AUTOSAR XML (schema 4-3-0)
standard types defined: dtRef_const_VOID, dtRef_VOID, boolean, float32, float64, sint16, sint16_least, sint32, sint32_least, sint64, sint8, sint8_least, uint16, uint16_least, uint32, uint32_least, uint64, uint8, uint8_least, boolean_CompuMethod, boolean_DataConstr, float32_DataConstr, float64_DataConstr, sint16_DataConstr, sint16_least_DataConstr, sint32_DataConstr, sint32_least_DataConstr, sint64_DataConstr, sint8_DataConstr, sint8_least_DataConstr, uint16_DataConstr, uint16_least_DataConstr, uint32_DataConstr, uint32_least_DataConstr, uint64_DataConstr, uint8_DataConstr, uint8_least_DataConstr, UInt8
package /MICROSAR/BswM_swc
  mode declaration group ESH_Mode: initial-mode=STARTUP
    5 x mode:
      STARTUP
      RUN
      POSTRUN
      WAKEUP
      SHUTDOWN
  mode declaration group ESH_RunRequest: initial-mode=RELEASED
    mode RELEASED
    mode REQUESTED
  mode declaration group MdgShutdownTimerState: initial-mode=TIMER_NOT_EXPIRED
    mode TIMER_EXPIRED
    mode TIMER_NOT_EXPIRED
  data type mapping set BswMMappingSet  # Contains Mapping for ModeDeclarations Groups which are provided by BswM.
    mode-request-type-maps:
      implementation-data-type=BswM_ESH_Mode, mode-group=ESH_Mode
      implementation-data-type=BswM_ESH_RunRequest, mode-group=ESH_RunRequest
      implementation-data-type=BswM_MdgShutdownTimerState, mode-group=MdgShutdownTimerState
package /MICROSAR/BswM_swc/DataTypes
  impl type BswM_ESH_Mode: compu {0=STARTUP, 1=RUN, 2=POSTRUN, 3=WAKEUP, 4=SHUTDOWN}, implementation-data-type=ImplementationDataTypes/uint8  # Unique value for each user
  impl type BswM_ESH_RunRequest: compu {0=RELEASED, 1=REQUESTED}, implementation-data-type=ImplementationDataTypes/uint8  # Unique value for each user
  impl type BswM_MdgShutdownTimerState: compu {0=TIMER_EXPIRED, 1=TIMER_NOT_EXPIRED}, implementation-data-type=ImplementationDataTypes/uint8  # Unique value for each user
package /MICROSAR/BswM_swc/Interfaces
  mode switch interface BswM_MSI_ESH_Mode: is-service=true, service-kind=BASIC-SOFTWARE-MODE-MANAGER
    mode group BswM_MDGP_ESH_Mode: type=ESH_Mode
  sender receiver interface BswM_SRI_BswM_MSI_ESH_Mode_BswM_MDGP_ESH_Mode: is-service=true, service-kind=BASIC-SOFTWARE-MODE-MANAGER
    data requestedMode: type=BswM_ESH_Mode
  mode switch interface BswM_MSI_ESH_RunRequest: is-service=true, service-kind=BASIC-SOFTWARE-MODE-MANAGER
    mode group BswM_MDGP_ESH_RunRequest: type=ESH_RunRequest
  sender receiver interface BswM_SRI_BswM_MSI_ESH_RunRequest_BswM_MDGP_ESH_RunRequest: is-service=true, service-kind=BASIC-SOFTWARE-MODE-MANAGER
    data requestedMode: type=BswM_ESH_RunRequest
  mode switch interface BswM_MSI_MdgShutdownTimerState: is-service=true, service-kind=BASIC-SOFTWARE-MODE-MANAGER
    mode group BswM_MDGP_MdgShutdownTimerState: type=MdgShutdownTimerState
  sender receiver interface BswM_SRI_BswM_MSI_MdgShutdownTimerState_BswM_MDGP_MdgShutdownTimerState: is-service=true, service-kind=BASIC-SOFTWARE-MODE-MANAGER
    data requestedMode: type=BswM_MdgShutdownTimerState
package /MICROSAR/BswM_swc/ComponentTypes
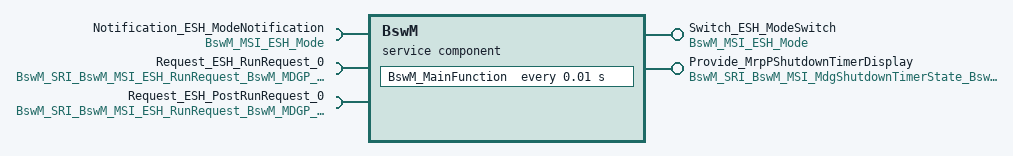
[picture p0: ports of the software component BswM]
  service sw component type BswM: category=SERVICE_COMPONENT
    provide port Switch_ESH_ModeSwitch: provided-interface=BswM_MSI_ESH_Mode
    require port Notification_ESH_ModeNotification: required-interface=BswM_MSI_ESH_Mode
    require port Request_ESH_RunRequest_0: nonqueued-receiver-com-spec{data-element=BswM_SRI_BswM_MSI_ESH_RunRequest_BswM_MDGP_ESH_RunRequest/requestedMode, handle-out-of-range-status=SILENT, init-value=RELEASED}, required-interface=BswM_SRI_BswM_MSI_ESH_RunRequest_BswM_MDGP_ESH_RunRequest
    require port Request_ESH_PostRunRequest_0: nonqueued-receiver-com-spec{data-element=BswM_SRI_BswM_MSI_ESH_RunRequest_BswM_MDGP_ESH_RunRequest/requestedMode, handle-out-of-range-status=SILENT, init-value=RELEASED}, required-interface=BswM_SRI_BswM_MSI_ESH_RunRequest_BswM_MDGP_ESH_RunRequest
    provide port Provide_MrpPShutdownTimerDisplay: nonqueued-sender-com-spec{data-element=BswM_SRI_BswM_MSI_MdgShutdownTimerState_BswM_MDGP_MdgShutdownTimerState/requestedMode, init-value=TIMER_NOT_EXPIRED}, provided-interface=BswM_SRI_BswM_MSI_MdgShutdownTimerState_BswM_MDGP_MdgShutdownTimerState
    behavior BswMInternalBehavior: data-type-mapping=BswMMappingSet, handle-termination-and-restart=NO-SUPPORT, included-data-type-set=data-type=[BswM_ESH_Mode, BswM_ESH_RunRequest, BswM_MdgShutdownTimerState]
      timing event Timer_BswM_MainFunction: start-on-event=BswM_MainFunction, period=0.01
      port-api-options:
        enable-take-address=true, indirect-api=false, port=Switch_ESH_ModeSwitch
        enable-take-address=true, indirect-api=false, port=Notification_ESH_ModeNotification
        enable-take-address=true, indirect-api=false, port=Request_ESH_RunRequest_0
        enable-take-address=true, indirect-api=false, port=Request_ESH_PostRunRequest_0
        enable-take-address=true, indirect-api=false, port=Provide_MrpPShutdownTimerDisplay
      runnable BswM_MainFunction: mode-access-point=Notification_ESH_ModeNotification.BswM_MDGP_ESH_Mode
        data-receive-point-by-arguments:
          access DataReceivePointBswM_MainFunction_Request_ESH_RunRequest_0_requestedMode: accessed-variable=Request_ESH_RunRequest_0.requestedMode
          access DataReceivePointBswM_MainFunction_Request_ESH_PostRunRequest_0_requestedMode: accessed-variable=Request_ESH_PostRunRequest_0.requestedMode
        data-send-points:
          access DataSendPointBswM_MainFunction_Provide_MrpPShutdownTimerDisplay_requestedMode: accessed-variable=Provide_MrpPShutdownTimerDisplay.requestedMode
        mode switch point ModeSwitchPointBswM_MainFunction_Switch_ESH_ModeSwitch_BswM_MDGP_ESH_Mode: mode-group=Switch_ESH_ModeSwitch.BswM_MDGP_ESH_Mode
  swc implementation BswMImplementation: programming-language=C, behavior=BswMInternalBehavior
package /MICROSAR/ComM_swc
  mode declaration group ComMMode: initial-mode=COMM_NO_COMMUNICATION
    mode COMM_NO_COMMUNICATION
    mode COMM_SILENT_COMMUNICATION
    mode COMM_FULL_COMMUNICATION
  data type mapping set ComMMode_DataTypeMappingSet: mode-request-type-map{implementation-data-type=ComM_ModeType, mode-group=ComMMode}  # Data Mapping for the Mode Declaration Group ComMMode.
package /MICROSAR/ComM_swc/DataTypes
  4 x impl type, all with category=TYPE_REFERENCE, implementation-data-type=ImplementationDataTypes/uint8:
    ComM_ModeType: compu {0=COMM_NO_COMMUNICATION, 1=COMM_SILENT_COMMUNICATION, 2=COMM_FULL_COMMUNICATION}
    ComM_InhibitionStatusType: range raw 0..255
    ComM_UserHandleType: range raw 0..255
    NetworkHandleType: range raw 0..255, type-emitter=ComM
package /MICROSAR/ComM_swc/Interfaces
  4 x client server interface, all with is-service=true, service-kind=COM-MANAGER:
    ComM_UserRequest
      4 x operation:
        RequestComMode: possible-error=[ComM_UserRequest/E_NOT_OK, E_MODE_LIMITATION]
          arg ComMode: type=ComM_ModeType, direction=IN
        GetCurrentComMode: possible-error=ComM_UserRequest/E_NOT_OK
          arg ComMode: type=ComM_ModeType, direction=OUT
        GetMaxComMode: possible-error=ComM_UserRequest/E_NOT_OK
          arg ComMode: type=ComM_ModeType, direction=OUT
        GetRequestedComMode: possible-error=ComM_UserRequest/E_NOT_OK
          arg ComMode: type=ComM_ModeType, direction=OUT
      error E_NOT_OK: error-code=1
      error E_MODE_LIMITATION: error-code=2
    ComM_ECUModeLimitation
      4 x operation, all with possible-error=ComM_ECUModeLimitation/E_NOT_OK:
        LimitECUToNoComMode
          arg Status: type=ImplementationDataTypes/boolean, direction=IN
        ReadInhibitCounter
          arg CounterValue: type=uint16, direction=OUT
        ResetInhibitCounter
        SetECUGroupClassification
          arg Status: type=ComM_InhibitionStatusType, direction=IN
      error E_NOT_OK: error-code=1
    ComM_ChannelWakeUp
      operation PreventWakeUp: possible-error=ComM_ChannelWakeUp/E_NOT_OK
        arg Status: type=ImplementationDataTypes/boolean, direction=IN
      error E_NOT_OK: error-code=1
    ComM_ChannelLimitation
      operation LimitChannelToNoComMode: possible-error=ComM_ChannelLimitation/E_NOT_OK
        arg Status: type=ImplementationDataTypes/boolean, direction=IN
      operation GetInhibitionStatus: possible-error=ComM_ChannelLimitation/E_NOT_OK
        arg Status: type=ComM_InhibitionStatusType, direction=OUT
      error E_NOT_OK: error-code=1
  mode switch interface ComM_CurrentMode: is-service=true, service-kind=COM-MANAGER
    mode group currentMode: type=ComMMode
package /MICROSAR/ComM_swc/ComponentTypes
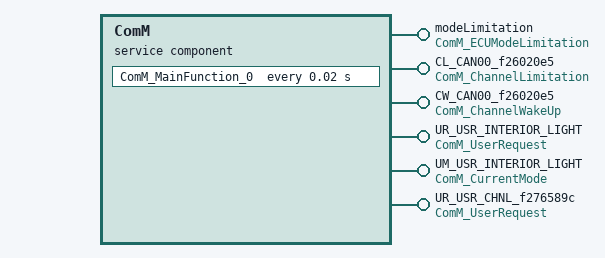
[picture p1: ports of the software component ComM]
  service sw component type ComM: category=SERVICE_COMPONENT
    6 x provide port:
      modeLimitation: provided-interface=ComM_ECUModeLimitation
      CL_CAN00_f26020e5: provided-interface=ComM_ChannelLimitation
      CW_CAN00_f26020e5: provided-interface=ComM_ChannelWakeUp
      UR_USR_INTERIOR_LIGHT: provided-interface=ComM_UserRequest
      UM_USR_INTERIOR_LIGHT: mode-switch-sender-com-spec=currentMode, provided-interface=ComM_CurrentMode
      UR_USR_CHNL_f276589c: provided-interface=ComM_UserRequest
    behavior ComMInternalBehavior: data-type-mapping=ComMMode_DataTypeMappingSet, handle-termination-and-restart=NO-SUPPORT, included-data-type-set=data-type=[ComM_ModeType, ComM_InhibitionStatusType, ComM_UserHandleType, NetworkHandleType]
      timing event Timer_ComM_MainFunction_0: start-on-event=ComM_MainFunction_0, period=0.02
      15 x operation invoked event:
        OpEventGetInhibitionStatus_GetInhibitionStatus_CL_CAN00_f26020e5: start-on-event=GetInhibitionStatus, operation=CL_CAN00_f26020e5.GetInhibitionStatus
        OpEventLimitECUToNoComMode_LimitECUToNoComMode_modeLimitation: start-on-event=LimitECUToNoComMode, operation=modeLimitation.LimitECUToNoComMode
        OpEventReadInhibitCounter_ReadInhibitCounter_modeLimitation: start-on-event=ReadInhibitCounter, operation=modeLimitation.ReadInhibitCounter
        OpEventResetInhibitCounter_ResetInhibitCounter_modeLimitation: start-on-event=ResetInhibitCounter, operation=modeLimitation.ResetInhibitCounter
        OpEventSetECUGroupClassification_SetECUGroupClassification_modeLimitation: start-on-event=SetECUGroupClassification, operation=modeLimitation.SetECUGroupClassification
        OpEventLimitChannelToNoComMode_LimitChannelToNoComMode_CL_CAN00_f26020e5: start-on-event=LimitChannelToNoComMode, operation=CL_CAN00_f26020e5.LimitChannelToNoComMode
        OpEventPreventWakeUp_PreventWakeUp_CW_CAN00_f26020e5: start-on-event=PreventWakeUp, operation=CW_CAN00_f26020e5.PreventWakeUp
        OpEventRequestComMode_RequestComMode_UR_USR_INTERIOR_LIGHT: start-on-event=RequestComMode, operation=UR_USR_INTERIOR_LIGHT.RequestComMode
        OpEventGetCurrentComMode_GetCurrentComMode_UR_USR_INTERIOR_LIGHT: start-on-event=GetCurrentComMode, operation=UR_USR_INTERIOR_LIGHT.GetCurrentComMode
        OpEventGetMaxComMode_GetMaxComMode_UR_USR_INTERIOR_LIGHT: start-on-event=GetMaxComMode, operation=UR_USR_INTERIOR_LIGHT.GetMaxComMode
        OpEventGetRequestedComMode_GetRequestedComMode_UR_USR_INTERIOR_LIGHT: start-on-event=GetRequestedComMode, operation=UR_USR_INTERIOR_LIGHT.GetRequestedComMode
        OpEventRequestComMode_RequestComMode_UR_USR_CHNL_f276589c: start-on-event=RequestComMode, operation=UR_USR_CHNL_f276589c.RequestComMode
        OpEventGetCurrentComMode_GetCurrentComMode_UR_USR_CHNL_f276589c: start-on-event=GetCurrentComMode, operation=UR_USR_CHNL_f276589c.GetCurrentComMode
        OpEventGetMaxComMode_GetMaxComMode_UR_USR_CHNL_f276589c: start-on-event=GetMaxComMode, operation=UR_USR_CHNL_f276589c.GetMaxComMode
        OpEventGetRequestedComMode_GetRequestedComMode_UR_USR_CHNL_f276589c: start-on-event=GetRequestedComMode, operation=UR_USR_CHNL_f276589c.GetRequestedComMode
      port-api-options:
        enable-take-address=true, indirect-api=false, port=modeLimitation
        {enable-take-address=true, indirect-api=false, port-defined-argument-value{value=0, value-type=NetworkHandleType}, port=CL_CAN00_f26020e5}
        {enable-take-address=true, indirect-api=false, port-defined-argument-value{value=0, value-type=NetworkHandleType}, port=CW_CAN00_f26020e5}
        {enable-take-address=true, indirect-api=false, port-defined-argument-value{value=0, value-type=ComM_UserHandleType}, port=UR_USR_INTERIOR_LIGHT}
        enable-take-address=true, indirect-api=false, port=UM_USR_INTERIOR_LIGHT
        {enable-take-address=true, indirect-api=false, port-defined-argument-value{value=1, value-type=ComM_UserHandleType}, port=UR_USR_CHNL_f276589c}
      12 x runnable, all with can-be-invoked-concurrently=true:
        ComM_MainFunction_0
          mode switch point ModeSwitchPointComM_MainFunction_0_UM_USR_INTERIOR_LIGHT_currentMode: mode-group=UM_USR_INTERIOR_LIGHT.currentMode
        GetInhibitionStatus: symbol=ComM_GetInhibitionStatus
        LimitECUToNoComMode: symbol=ComM_LimitECUToNoComMode
        ReadInhibitCounter: symbol=ComM_ReadInhibitCounter
        ResetInhibitCounter: symbol=ComM_ResetInhibitCounter
        SetECUGroupClassification: symbol=ComM_SetECUGroupClassification
        LimitChannelToNoComMode: symbol=ComM_LimitChannelToNoComMode
        PreventWakeUp: symbol=ComM_PreventWakeUp
        RequestComMode: symbol=ComM_RequestComMode
        GetCurrentComMode: symbol=ComM_GetCurrentComMode
        GetMaxComMode: symbol=ComM_GetMaxComMode
        GetRequestedComMode: symbol=ComM_GetRequestedComMode
  swc implementation ComMImplementation: programming-language=C, behavior=ComMInternalBehavior
package /MICROSAR/Dcm_swc
  mode declaration group DcmControlDtcSetting: category=EXPLICIT_ORDER, initial-mode=ENABLEDTCSETTING, on-transition-value=2
    mode ENABLEDTCSETTING: value=0
    mode DISABLEDTCSETTING: value=1
  mode declaration group DcmEcuReset: category=EXPLICIT_ORDER, initial-mode=NONE, on-transition-value=7
    7 x mode:
      NONE: value=0
      HARD: value=1
      KEYONOFF: value=2
      SOFT: value=3
      JUMPTOBOOTLOADER: value=4
      JUMPTOSYSSUPPLIERBOOTLOADER: value=5
      EXECUTE: value=6
  mode declaration group DcmDiagnosticSessionControl: category=EXPLICIT_ORDER, initial-mode=DEFAULT_SESSION, on-transition-value=255
    mode DEFAULT_SESSION: value=1
    mode PROGRAMMING_SESSION: value=2
    mode EXTENDED_SESSION: value=3
  data type mapping set DcmMappingSet  # Contains mapping for ModeDeclarationGroups which are provided by Dcm.
    mode-request-type-maps:
      implementation-data-type=Dcm_ControlDtcSettingType, mode-group=DcmControlDtcSetting
      implementation-data-type=Dcm_EcuResetType, mode-group=DcmEcuReset
      implementation-data-type=Dcm_DiagnosticSessionControlType, mode-group=DcmDiagnosticSessionControl
package /MICROSAR/Dcm_swc/DataTypes
  17 x impl type:
    Dcm_ConfirmationStatusType: compu {0=DCM_RES_POS_OK, 1=DCM_RES_POS_NOT_OK, 2=DCM_RES_NEG_OK, 3=DCM_RES_NEG_NOT_OK}, implementation-data-type=ImplementationDataTypes/uint8
    Dcm_OpStatusType: compu {0=DCM_INITIAL, 1=DCM_PENDING, 2=DCM_CANCEL, 3=DCM_FORCE_RCRRP_OK, 64=DCM_FORCE_RCRRP_NOT_OK}, implementation-data-type=ImplementationDataTypes/uint8
    Dcm_NegativeResponseCodeType: compu {0=DCM_E_POSITIVERESPONSE, 16=DCM_E_GENERALREJECT, 17=DCM_E_SERVICENOTSUPPORTED, 18=DCM_E_SUBFUNCTIONNOTSUPPORTED, 19=DCM_E_INCORRECTMESSAGELENGTHORINVALIDFORMAT, 20=DCM_E_RESPONSETOOLONG, 33=DCM_E_BUSYREPEATREQUEST, 34=DCM_E_CONDITIONSNOTCORRECT, 36=DCM_E_REQUESTSEQUENCEERROR, 37=DCM_E_NORESPONSEFROMSUBNETCOMPONENT, 38=DCM_E_FAILUREPREVENTSEXECUTIONOFREQUESTEDACTION, 49=DCM_E_REQUESTOUTOFRANGE, 51=DCM_E_SECURITYACCESSDENIED, 53=DCM_E_INVALIDKEY, 54=DCM_E_EXCEEDNUMBEROFATTEMPTS, 55=DCM_E_REQUIREDTIMEDELAYNOTEXPIRED, 112=DCM_E_UPLOADDOWNLOADNOTACCEPTED, 113=DCM_E_TRANSFERDATASUSPENDED, 114=DCM_E_GENERALPROGRAMMINGFAILURE, 115=DCM_E_WRONGBLOCKSEQUENCECOUNTER, 120=DCM_E_REQUESTCORRECTLYRECEIVEDRESPONSEPENDING, 126=DCM_E_SUBFUNCTIONNOTSUPPORTEDINACTIVESESSION, 127=DCM_E_SERVICENOTSUPPORTEDINACTIVESESSION, 129=DCM_E_RPMTOOHIGH, 130=DCM_E_RPMTOOLOW, 131=DCM_E_ENGINEISRUNNING, 132=DCM_E_ENGINEISNOTRUNNING, 133=DCM_E_ENGINERUNTIMETOOLOW, 134=DCM_E_TEMPERATURETOOHIGH, 135=DCM_E_TEMPERATURETOOLOW, 136=DCM_E_VEHICLESPEEDTOOHIGH, 137=DCM_E_VEHICLESPEEDTOOLOW, 138=DCM_E_THROTTLE_PEDALTOOHIGH, 139=DCM_E_THROTTLE_PEDALTOOLOW, 140=DCM_E_TRANSMISSIONRANGENOTINNEUTRAL, 141=DCM_E_TRANSMISSIONRANGENOTINGEAR, 143=DCM_E_BRAKESWITCH_NOTCLOSED, 144=DCM_E_SHIFTERLEVERNOTINPARK, 145=DCM_E_TORQUECONVERTERCLUTCHLOCKED, 146=DCM_E_VOLTAGETOOHIGH, 147=DCM_E_VOLTAGETOOLOW, 240..249=DCM_E_VMSCNC_0..DCM_E_VMSCNC_9, 250=DCM_E_VMSCNC_A, 251=DCM_E_VMSCNC_B, 252=DCM_E_VMSCNC_C, 253=DCM_E_VMSCNC_D, 254=DCM_E_VMSCNC_E}, implementation-data-type=ImplementationDataTypes/uint8
    Dcm_ProtocolType: compu {0=DCM_OBD_ON_CAN, 1=DCM_OBD_ON_FLEXRAY, 2=DCM_OBD_ON_IP, 3=DCM_UDS_ON_CAN, 4=DCM_UDS_ON_FLEXRAY, 5=DCM_UDS_ON_IP, 12=DCM_NO_ACTIVE_PROTOCOL, 240..254=DCM_SUPPLIER_1..DCM_SUPPLIER_15}, implementation-data-type=ImplementationDataTypes/uint8
    Dcm_RequestKindType: compu {0=DCM_REQ_KIND_NONE, 1=DCM_REQ_KIND_EXTERNAL, 2=DCM_REQ_KIND_ROE}, implementation-data-type=ImplementationDataTypes/uint8
    Dcm_SecLevelType: compu {0=DCM_SEC_LEV_LOCKED, 1=DCM_SEC_LEV_L1}, implementation-data-type=ImplementationDataTypes/uint8
    Dcm_SesCtrlType: compu {1=DCM_DEFAULT_SESSION, 2=DCM_PROGRAMMING_SESSION, 3=DCM_EXTENDED_DIAGNOSTIC_SESSION}, implementation-data-type=ImplementationDataTypes/uint8
    Dem_DTCFormatType: compu {0=DEM_DTC_FORMAT_OBD, 1=DEM_DTC_FORMAT_UDS, 2=DEM_DTC_FORMAT_J1939}, implementation-data-type=ImplementationDataTypes/uint8
    Dem_DTCKindType: compu {1=DEM_DTC_KIND_ALL_DTCS, 2=DEM_DTC_KIND_EMISSION_REL_DTCS}, implementation-data-type=ImplementationDataTypes/uint8
    Dem_DTCGroupType: range raw 0..16777215, implementation-data-type=ImplementationDataTypes/uint32
    Dem_DTCOriginType: compu {1=DEM_DTC_ORIGIN_PRIMARY_MEMORY, 2=DEM_DTC_ORIGIN_MIRROR_MEMORY, 3=DEM_DTC_ORIGIN_PERMANENT_MEMORY, 4=DEM_DTC_ORIGIN_SECONDARY_MEMORY}, implementation-data-type=ImplementationDataTypes/uint8
    Dcm_ControlDtcSettingType: compu {0=DCM_ENUM_ENABLEDTCSETTING, 1=DCM_ENUM_DISABLEDTCSETTING}, implementation-data-type=ImplementationDataTypes/uint8
    Dcm_EcuResetType: compu {0=DCM_ENUM_NONE, 1=DCM_ENUM_HARD, 2=DCM_ENUM_KEYONOFF, 3=DCM_ENUM_SOFT, 4=DCM_ENUM_JUMPTOBOOTLOADER, 5=DCM_ENUM_JUMPTOSYSSUPPLIERBOOTLOADER, 6=DCM_ENUM_EXECUTE}, implementation-data-type=ImplementationDataTypes/uint8
    Dcm_DiagnosticSessionControlType: compu {1=DCM_ENUM_DEFAULT_SESSION, 2=DCM_ENUM_PROGRAMMING_SESSION, 3=DCM_ENUM_EXTENDED_SESSION}, implementation-data-type=ImplementationDataTypes/uint8
    Dcm_CommunicationModeType: compu {0=DCM_ENABLE_RX_TX_NORM, 1=DCM_ENABLE_RX_DISABLE_TX_NORM, 2=DCM_DISABLE_RX_ENABLE_TX_NORM, 3=DCM_DISABLE_RX_TX_NORMAL, 4=DCM_ENABLE_RX_TX_NM, 5=DCM_ENABLE_RX_DISABLE_TX_NM, 6=DCM_DISABLE_RX_ENABLE_TX_NM, 7=DCM_DISABLE_RX_TX_NM, 8=DCM_ENABLE_RX_TX_NORM_NM, 9=DCM_ENABLE_RX_DISABLE_TX_NORM_NM, 10=DCM_DISABLE_RX_ENABLE_TX_NORM_NM, 11=DCM_DISABLE_RX_TX_NORM_NM}, implementation-data-type=ImplementationDataTypes/uint8
    Dcm_Data2ByteType: category=ARRAY, sw-calibration-access=READ-ONLY
      element Dcm_Data2ByteTypeElement: array-size=2, array-size-semantics=FIXED-SIZE, implementation-data-type=ImplementationDataTypes/uint8
    Dcm_Data4ByteType: category=ARRAY, sw-calibration-access=READ-ONLY
      element Dcm_Data4ByteTypeElement: array-size=4, array-size-semantics=FIXED-SIZE, implementation-data-type=ImplementationDataTypes/uint8
package /MICROSAR/Dcm_swc/Interfaces
  mode switch interface DcmControlDtcSetting: is-service=true, service-kind=DIAGNOSTIC-COMMUNICATION-MANAGER
    mode group DcmControlDtcSetting: type=DcmControlDtcSetting
  mode switch interface DcmEcuReset: is-service=true, service-kind=DIAGNOSTIC-COMMUNICATION-MANAGER
    mode group DcmEcuReset: type=DcmEcuReset
  mode switch interface DcmDiagnosticSessionControl: is-service=true, service-kind=DIAGNOSTIC-COMMUNICATION-MANAGER
    mode group DcmDiagnosticSessionControl: type=DcmDiagnosticSessionControl
  client server interface DCMServices: is-service=true, service-kind=DIAGNOSTIC-COMMUNICATION-MANAGER
    6 x operation:
      GetActiveProtocol: possible-error=DCMServices/E_OK
        arg ActiveProtocol: type=Dcm_ProtocolType, direction=OUT
      GetSesCtrlType: possible-error=DCMServices/E_OK
        arg SesCtrlType: type=Dcm_SesCtrlType, direction=OUT
      ResetToDefaultSession: possible-error=DCMServices/E_OK
      GetSecurityLevel: possible-error=DCMServices/E_OK
        arg SecLevel: type=Dcm_SecLevelType, direction=OUT
      SetActiveDiagnostic: possible-error=DCMServices/E_OK
        arg active: type=ImplementationDataTypes/boolean, direction=IN
      GetRequestKind: possible-error=DCMServices/E_NOT_OK
        arg TesterSourceAddress: type=uint16, direction=IN
        arg RequestKind: type=Dcm_RequestKindType, direction=OUT
    error E_OK: error-code=0
    error E_NOT_OK: error-code=1
  client server interface SecurityAccess_Level_01: is-service=true, service-kind=DIAGNOSTIC-COMMUNICATION-MANAGER
    operation GetSeed: possible-error=[SecurityAccess_Level_01/E_NOT_OK, SecurityAccess_Level_01/DCM_E_PENDING]
      arg OpStatus: type=Dcm_OpStatusType, direction=IN
      arg Seed: type=Dcm_Data2ByteType, direction=OUT
      arg ErrorCode: type=Dcm_NegativeResponseCodeType, direction=OUT
    operation CompareKey: possible-error=[SecurityAccess_Level_01/E_NOT_OK, SecurityAccess_Level_01/DCM_E_PENDING, DCM_E_COMPARE_KEY_FAILED]
      arg Key: type=Dcm_Data2ByteType, direction=IN
      arg OpStatus: type=Dcm_OpStatusType, direction=IN
      arg ErrorCode: type=Dcm_NegativeResponseCodeType, direction=OUT
    error E_NOT_OK: error-code=1
    error DCM_E_PENDING: error-code=10
    error DCM_E_COMPARE_KEY_FAILED: error-code=11
  client server interface DataServices_Diag_RWDI_LightOnOffCounter_LightOnOffCounter_Value: is-service=true, service-kind=DIAGNOSTIC-COMMUNICATION-MANAGER
    operation ReadData: possible-error=[DataServices_Diag_RWDI_LightOnOffCounter_LightOnOffCounter_Value/E_NOT_OK, DataServices_Diag_RWDI_LightOnOffCounter_LightOnOffCounter_Value/DCM_E_PENDING]
      arg OpStatus: type=Dcm_OpStatusType, direction=IN
      arg Data: type=Dcm_Data4ByteType, direction=OUT
    operation ConditionCheckRead: possible-error=[DataServices_Diag_RWDI_LightOnOffCounter_LightOnOffCounter_Value/E_NOT_OK, DataServices_Diag_RWDI_LightOnOffCounter_LightOnOffCounter_Value/DCM_E_PENDING]
      arg OpStatus: type=Dcm_OpStatusType, direction=IN
      arg ErrorCode: type=Dcm_NegativeResponseCodeType, direction=OUT
    operation WriteData: possible-error=[DataServices_Diag_RWDI_LightOnOffCounter_LightOnOffCounter_Value/E_NOT_OK, DataServices_Diag_RWDI_LightOnOffCounter_LightOnOffCounter_Value/DCM_E_PENDING]
      arg Data: type=Dcm_Data4ByteType, direction=IN
      arg OpStatus: type=Dcm_OpStatusType, direction=IN
      arg ErrorCode: type=Dcm_NegativeResponseCodeType, direction=OUT
    error E_NOT_OK: error-code=1
    error DCM_E_PENDING: error-code=10
package /MICROSAR/Dcm_swc/ComponentTypes
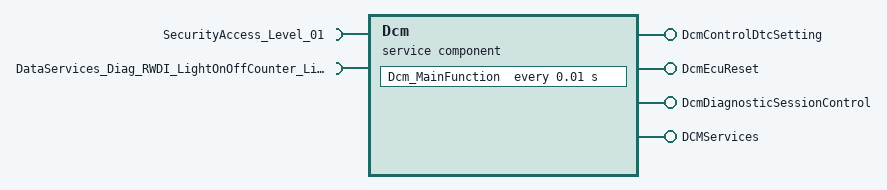
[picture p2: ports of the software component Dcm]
  service sw component type Dcm: category=SERVICE_COMPONENT
    4 x provide port:
      DcmControlDtcSetting: provided-interface=DcmControlDtcSetting
      DcmEcuReset: mode-switch-sender-com-spec{mode-group=DcmEcuReset, mode-switched-ack=timeout=0}, provided-interface=DcmEcuReset
      DcmDiagnosticSessionControl: provided-interface=DcmDiagnosticSessionControl
      DCMServices: provided-interface=DCMServices
    require port SecurityAccess_Level_01: required-interface=SecurityAccess_Level_01
    require port DataServices_Diag_RWDI_LightOnOffCounter_LightOnOffCounter_Value: required-interface=DataServices_Diag_RWDI_LightOnOffCounter_LightOnOffCounter_Value
    behavior DcmInternalBehavior: data-type-mapping=DcmMappingSet, handle-termination-and-restart=NO-SUPPORT, included-data-type-set=data-type=[Dcm_ConfirmationStatusType, Dcm_OpStatusType, Dcm_NegativeResponseCodeType, Dcm_ProtocolType, Dcm_RequestKindType, Dcm_SecLevelType, Dcm_SesCtrlType, Dcm_ControlDtcSettingType, Dcm_EcuResetType, Dcm_DiagnosticSessionControlType, Dcm_CommunicationModeType]
      timing event Timer_Dcm_MainFunction: start-on-event=Dcm_MainFunction, period=0.01
      6 x operation invoked event:
        OpEventGetActiveProtocol_GetActiveProtocol_DCMServices: start-on-event=GetActiveProtocol, operation=DCMServices.GetActiveProtocol
        OpEventGetSesCtrlType_GetSesCtrlType_DCMServices: start-on-event=GetSesCtrlType, operation=DCMServices.GetSesCtrlType
        OpEventResetToDefaultSession_ResetToDefaultSession_DCMServices: start-on-event=ResetToDefaultSession, operation=DCMServices.ResetToDefaultSession
        OpEventGetSecurityLevel_GetSecurityLevel_DCMServices: start-on-event=GetSecurityLevel, operation=DCMServices.GetSecurityLevel
        OpEventSetActiveDiagnostic_SetActiveDiagnostic_DCMServices: start-on-event=SetActiveDiagnostic, operation=DCMServices.SetActiveDiagnostic
        OpEventGetRequestKind_GetRequestKind_DCMServices: start-on-event=GetRequestKind, operation=DCMServices.GetRequestKind
      port-api-options:
        enable-take-address=true, indirect-api=false, port=DcmControlDtcSetting
        enable-take-address=true, indirect-api=false, port=DcmEcuReset
        enable-take-address=true, indirect-api=false, port=DcmDiagnosticSessionControl
        enable-take-address=true, indirect-api=false, port=DCMServices
        enable-take-address=true, indirect-api=false, port=SecurityAccess_Level_01
        enable-take-address=true, indirect-api=false, port=DataServices_Diag_RWDI_LightOnOffCounter_LightOnOffCounter_Value
      7 x runnable:
        Dcm_MainFunction
          mode switch point ModeSwitchPointDcm_MainFunction_DcmControlDtcSetting_DcmControlDtcSetting: mode-group=DcmControlDtcSetting.DcmControlDtcSetting
          mode switch point ModeSwitchPointDcm_MainFunction_DcmEcuReset_DcmEcuReset: mode-group=DcmEcuReset.DcmEcuReset
          mode switch point ModeSwitchPointDcm_MainFunction_DcmDiagnosticSessionControl_DcmDiagnosticSessionControl: mode-group=DcmDiagnosticSessionControl.DcmDiagnosticSessionControl
          5 x sync call, all with timeout=0:
            OpServerCallDcm_MainFunction_GetSeed_SecurityAccess_Level_01: operation=SecurityAccess_Level_01.GetSeed
            OpServerCallDcm_MainFunction_CompareKey_SecurityAccess_Level_01: operation=SecurityAccess_Level_01.CompareKey
            OpServerCallDcm_MainFunction_ReadData_DataServices_Diag_RWDI_LightOnOffCounter_LightOnOffCounter_Value: operation=DataServices_Diag_RWDI_LightOnOffCounter_LightOnOffCounter_Value.ReadData
            OpServerCallDcm_MainFunction_ConditionCheckRead_DataServices_Diag_RWDI_LightOnOffCounter_LightOnOffCounter_Value: operation=DataServices_Diag_RWDI_LightOnOffCounter_LightOnOffCounter_Value.ConditionCheckRead
            OpServerCallDcm_MainFunction_WriteData_DataServices_Diag_RWDI_LightOnOffCounter_LightOnOffCounter_Value: operation=DataServices_Diag_RWDI_LightOnOffCounter_LightOnOffCounter_Value.WriteData
        GetActiveProtocol: can-be-invoked-concurrently=true, symbol=Dcm_GetActiveProtocol
        GetSesCtrlType: can-be-invoked-concurrently=true, symbol=Dcm_GetSesCtrlType
        ResetToDefaultSession: can-be-invoked-concurrently=true, symbol=Dcm_ResetToDefaultSession
        GetSecurityLevel: can-be-invoked-concurrently=true, symbol=Dcm_GetSecurityLevel
        SetActiveDiagnostic: can-be-invoked-concurrently=true, symbol=Dcm_SetActiveDiagnostic
        GetRequestKind: can-be-invoked-concurrently=true, symbol=Dcm_GetRequestKind
  swc implementation DcmImplementation: programming-language=C, behavior=DcmInternalBehavior
package /MICROSAR/Dem_swc/DataTypes
  23 x impl type:
    Dem_EventIdType: range raw 1..65535, implementation-data-type=uint16
    Dem_RatioIdType: range raw 1..65535, implementation-data-type=uint16
    Dem_DTCStatusMaskType: range raw 0..255, implementation-data-type=ImplementationDataTypes/uint8
    Dem_OperationCycleIdType: range raw 0..255, implementation-data-type=ImplementationDataTypes/uint8
    Dem_DTCGroupType: range raw 0..16777215, implementation-data-type=ImplementationDataTypes/uint32
    Dem_EventStatusType: compu {0=DEM_EVENT_STATUS_PASSED, 1=DEM_EVENT_STATUS_FAILED, 2=DEM_EVENT_STATUS_PREPASSED, 3=DEM_EVENT_STATUS_PREFAILED, 4=DEM_EVENT_STATUS_FDC_THRESHOLD_REACHED, 5=DEM_EVENT_STATUS_PASSED_CONDITIONS_NOT_FULFILLED, 6=DEM_EVENT_STATUS_FAILED_CONDITIONS_NOT_FULFILLED, 7=DEM_EVENT_STATUS_PREPASSED_CONDITIONS_NOT_FULFILLED, 8=DEM_EVENT_STATUS_PREFAILED_CONDITIONS_NOT_FULFILLED}, implementation-data-type=ImplementationDataTypes/uint8
    Dem_InitMonitorReasonType: compu {1=DEM_INIT_MONITOR_CLEAR, 2=DEM_INIT_MONITOR_RESTART, 3=DEM_INIT_MONITOR_REENABLED, 4=DEM_INIT_MONITOR_STORAGE_REENABLED}, implementation-data-type=ImplementationDataTypes/uint8
    Dem_DTCOriginType: compu {1=DEM_DTC_ORIGIN_PRIMARY_MEMORY, 2=DEM_DTC_ORIGIN_MIRROR_MEMORY, 3=DEM_DTC_ORIGIN_PERMANENT_MEMORY, 4=DEM_DTC_ORIGIN_OBD_RELEVANT_MEMORY, 5=DEM_DTC_ORIGIN_SECONDARY_MEMORY, 5=DEM_DTC_ORIGIN_USERDEFINED_MEMORY_10, 5=DEM_DTC_ORIGIN_USERDEFINED_MEMORY_11, 5=DEM_DTC_ORIGIN_USERDEFINED_MEMORY_12, 5=DEM_DTC_ORIGIN_USERDEFINED_MEMORY_13, 5=DEM_DTC_ORIGIN_USERDEFINED_MEMORY_14, 5=DEM_DTC_ORIGIN_USERDEFINED_MEMORY_15, 5=DEM_DTC_ORIGIN_USERDEFINED_MEMORY_16, 5=DEM_DTC_ORIGIN_USERDEFINED_MEMORY_17, 5=DEM_DTC_ORIGIN_USERDEFINED_MEMORY_18, 5=DEM_DTC_ORIGIN_USERDEFINED_MEMORY_19, 5=DEM_DTC_ORIGIN_USERDEFINED_MEMORY_1A, 5=DEM_DTC_ORIGIN_USERDEFINED_MEMORY_1B, 5=DEM_DTC_ORIGIN_USERDEFINED_MEMORY_1C, 5=DEM_DTC_ORIGIN_USERDEFINED_MEMORY_1D, 5=DEM_DTC_ORIGIN_USERDEFINED_MEMORY_1E, 5=DEM_DTC_ORIGIN_USERDEFINED_MEMORY_1F, 5=DEM_DTC_ORIGIN_USERDEFINED_MEMORY_20, 5=DEM_DTC_ORIGIN_USERDEFINED_MEMORY_21, 5=DEM_DTC_ORIGIN_USERDEFINED_MEMORY_22, 5=DEM_DTC_ORIGIN_USERDEFINED_MEMORY_23, 5=DEM_DTC_ORIGIN_USERDEFINED_MEMORY_24, 5=DEM_DTC_ORIGIN_USERDEFINED_MEMORY_25, 5=DEM_DTC_ORIGIN_USERDEFINED_MEMORY_26, 5=DEM_DTC_ORIGIN_USERDEFINED_MEMORY_27, 5=DEM_DTC_ORIGIN_USERDEFINED_MEMORY_28, 5=DEM_DTC_ORIGIN_USERDEFINED_MEMORY_29, 5=DEM_DTC_ORIGIN_USERDEFINED_MEMORY_2A, 5=DEM_DTC_ORIGIN_USERDEFINED_MEMORY_2B, 5=DEM_DTC_ORIGIN_USERDEFINED_MEMORY_2C, 5=DEM_DTC_ORIGIN_USERDEFINED_MEMORY_2D, 5=DEM_DTC_ORIGIN_USERDEFINED_MEMORY_2E, 5=DEM_DTC_ORIGIN_USERDEFINED_MEMORY_2F, 5=DEM_DTC_ORIGIN_USERDEFINED_MEMORY_30, 5=DEM_DTC_ORIGIN_USERDEFINED_MEMORY_31, 5=DEM_DTC_ORIGIN_USERDEFINED_MEMORY_32, 5=DEM_DTC_ORIGIN_USERDEFINED_MEMORY_33, 5=DEM_DTC_ORIGIN_USERDEFINED_MEMORY_34, 5=DEM_DTC_ORIGIN_USERDEFINED_MEMORY_35, 5=DEM_DTC_ORIGIN_USERDEFINED_MEMORY_36, 5=DEM_DTC_ORIGIN_USERDEFINED_MEMORY_37, 5=DEM_DTC_ORIGIN_USERDEFINED_MEMORY_38, 5=DEM_DTC_ORIGIN_USERDEFINED_MEMORY_39, 5=DEM_DTC_ORIGIN_USERDEFINED_MEMORY_3A, 5=DEM_DTC_ORIGIN_USERDEFINED_MEMORY_3B, 5=DEM_DTC_ORIGIN_USERDEFINED_MEMORY_3C, 5=DEM_DTC_ORIGIN_USERDEFINED_MEMORY_3D, 5=DEM_DTC_ORIGIN_USERDEFINED_MEMORY_3E, 5=DEM_DTC_ORIGIN_USERDEFINED_MEMORY_3F, 5=DEM_DTC_ORIGIN_USERDEFINED_MEMORY_40, 5=DEM_DTC_ORIGIN_USERDEFINED_MEMORY_41, 5=DEM_DTC_ORIGIN_USERDEFINED_MEMORY_42, 5=DEM_DTC_ORIGIN_USERDEFINED_MEMORY_43, 5=DEM_DTC_ORIGIN_USERDEFINED_MEMORY_44, 5=DEM_DTC_ORIGIN_USERDEFINED_MEMORY_45, 5=DEM_DTC_ORIGIN_USERDEFINED_MEMORY_46, 5=DEM_DTC_ORIGIN_USERDEFINED_MEMORY_47, 5=DEM_DTC_ORIGIN_USERDEFINED_MEMORY_48, 5=DEM_DTC_ORIGIN_USERDEFINED_MEMORY_49, 5=DEM_DTC_ORIGIN_USERDEFINED_MEMORY_4A, 5=DEM_DTC_ORIGIN_USERDEFINED_MEMORY_4B, 5=DEM_DTC_ORIGIN_USERDEFINED_MEMORY_4C, 5=DEM_DTC_ORIGIN_USERDEFINED_MEMORY_4D, 5=DEM_DTC_ORIGIN_USERDEFINED_MEMORY_4E, 5=DEM_DTC_ORIGIN_USERDEFINED_MEMORY_4F, 5=DEM_DTC_ORIGIN_USERDEFINED_MEMORY_50, 5=DEM_DTC_ORIGIN_USERDEFINED_MEMORY_51, 5=DEM_DTC_ORIGIN_USERDEFINED_MEMORY_52, 5=DEM_DTC_ORIGIN_USERDEFINED_MEMORY_53, 5=DEM_DTC_ORIGIN_USERDEFINED_MEMORY_54, 5=DEM_DTC_ORIGIN_USERDEFINED_MEMORY_55, 5=DEM_DTC_ORIGIN_USERDEFINED_MEMORY_56, 5=DEM_DTC_ORIGIN_USERDEFINED_MEMORY_57, 5=DEM_DTC_ORIGIN_USERDEFINED_MEMORY_58, 5=DEM_DTC_ORIGIN_USERDEFINED_MEMORY_59, 5=DEM_DTC_ORIGIN_USERDEFINED_MEMORY_5A, 5=DEM_DTC_ORIGIN_USERDEFINED_MEMORY_5B, 5=DEM_DTC_ORIGIN_USERDEFINED_MEMORY_5C, 5=DEM_DTC_ORIGIN_USERDEFINED_MEMORY_5D, 5=DEM_DTC_ORIGIN_USERDEFINED_MEMORY_5E, 5=DEM_DTC_ORIGIN_USERDEFINED_MEMORY_5F, 5=DEM_DTC_ORIGIN_USERDEFINED_MEMORY_60, 5=DEM_DTC_ORIGIN_USERDEFINED_MEMORY_61, 5=DEM_DTC_ORIGIN_USERDEFINED_MEMORY_62, 5=DEM_DTC_ORIGIN_USERDEFINED_MEMORY_63, 5=DEM_DTC_ORIGIN_USERDEFINED_MEMORY_64, 5=DEM_DTC_ORIGIN_USERDEFINED_MEMORY_65, 5=DEM_DTC_ORIGIN_USERDEFINED_MEMORY_66, 5=DEM_DTC_ORIGIN_USERDEFINED_MEMORY_67, 5=DEM_DTC_ORIGIN_USERDEFINED_MEMORY_68, 5=DEM_DTC_ORIGIN_USERDEFINED_MEMORY_69, 5=DEM_DTC_ORIGIN_USERDEFINED_MEMORY_6A, 5=DEM_DTC_ORIGIN_USERDEFINED_MEMORY_6B, 5=DEM_DTC_ORIGIN_USERDEFINED_MEMORY_6C, 5=DEM_DTC_ORIGIN_USERDEFINED_MEMORY_6D, 5=DEM_DTC_ORIGIN_USERDEFINED_MEMORY_6E, 5=DEM_DTC_ORIGIN_USERDEFINED_MEMORY_6F, 5=DEM_DTC_ORIGIN_USERDEFINED_MEMORY_70, 5=DEM_DTC_ORIGIN_USERDEFINED_MEMORY_71, 5=DEM_DTC_ORIGIN_USERDEFINED_MEMORY_72, 5=DEM_DTC_ORIGIN_USERDEFINED_MEMORY_73, 5=DEM_DTC_ORIGIN_USERDEFINED_MEMORY_74, 5=DEM_DTC_ORIGIN_USERDEFINED_MEMORY_75, 5=DEM_DTC_ORIGIN_USERDEFINED_MEMORY_76, 5=DEM_DTC_ORIGIN_USERDEFINED_MEMORY_77, 5=DEM_DTC_ORIGIN_USERDEFINED_MEMORY_78, 5=DEM_DTC_ORIGIN_USERDEFINED_MEMORY_79, 5=DEM_DTC_ORIGIN_USERDEFINED_MEMORY_7A, 5=DEM_DTC_ORIGIN_USERDEFINED_MEMORY_7B, 5=DEM_DTC_ORIGIN_USERDEFINED_MEMORY_7C, 5=DEM_DTC_ORIGIN_USERDEFINED_MEMORY_7D, 5=DEM_DTC_ORIGIN_USERDEFINED_MEMORY_7E, 5=DEM_DTC_ORIGIN_USERDEFINED_MEMORY_7F, 5=DEM_DTC_ORIGIN_USERDEFINED_MEMORY_80, 5=DEM_DTC_ORIGIN_USERDEFINED_MEMORY_81, 5=DEM_DTC_ORIGIN_USERDEFINED_MEMORY_82, 5=DEM_DTC_ORIGIN_USERDEFINED_MEMORY_83, 5=DEM_DTC_ORIGIN_USERDEFINED_MEMORY_84, 5=DEM_DTC_ORIGIN_USERDEFINED_MEMORY_85, 5=DEM_DTC_ORIGIN_USERDEFINED_MEMORY_86, 5=DEM_DTC_ORIGIN_USERDEFINED_MEMORY_87, 5=DEM_DTC_ORIGIN_USERDEFINED_MEMORY_88, 5=DEM_DTC_ORIGIN_USERDEFINED_MEMORY_89, 5=DEM_DTC_ORIGIN_USERDEFINED_MEMORY_8A, 5=DEM_DTC_ORIGIN_USERDEFINED_MEMORY_8B, 5=DEM_DTC_ORIGIN_USERDEFINED_MEMORY_8C, 5=DEM_DTC_ORIGIN_USERDEFINED_MEMORY_8D, 5=DEM_DTC_ORIGIN_USERDEFINED_MEMORY_8E, 5=DEM_DTC_ORIGIN_USERDEFINED_MEMORY_8F, 5=DEM_DTC_ORIGIN_USERDEFINED_MEMORY_90, 5=DEM_DTC_ORIGIN_USERDEFINED_MEMORY_91, 5=DEM_DTC_ORIGIN_USERDEFINED_MEMORY_92, 5=DEM_DTC_ORIGIN_USERDEFINED_MEMORY_93, 5=DEM_DTC_ORIGIN_USERDEFINED_MEMORY_94, 5=DEM_DTC_ORIGIN_USERDEFINED_MEMORY_95, 5=DEM_DTC_ORIGIN_USERDEFINED_MEMORY_96, 5=DEM_DTC_ORIGIN_USERDEFINED_MEMORY_97, 5=DEM_DTC_ORIGIN_USERDEFINED_MEMORY_98, 5=DEM_DTC_ORIGIN_USERDEFINED_MEMORY_99, 5=DEM_DTC_ORIGIN_USERDEFINED_MEMORY_9A, 5=DEM_DTC_ORIGIN_USERDEFINED_MEMORY_9B, 5=DEM_DTC_ORIGIN_USERDEFINED_MEMORY_9C, 5=DEM_DTC_ORIGIN_USERDEFINED_MEMORY_9D, 5=DEM_DTC_ORIGIN_USERDEFINED_MEMORY_9E, 5=DEM_DTC_ORIGIN_USERDEFINED_MEMORY_9F, 5=DEM_DTC_ORIGIN_USERDEFINED_MEMORY_A0, 5=DEM_DTC_ORIGIN_USERDEFINED_MEMORY_A1, 5=DEM_DTC_ORIGIN_USERDEFINED_MEMORY_A2, 5=DEM_DTC_ORIGIN_USERDEFINED_MEMORY_A3, 5=DEM_DTC_ORIGIN_USERDEFINED_MEMORY_A4, 5=DEM_DTC_ORIGIN_USERDEFINED_MEMORY_A5, 5=DEM_DTC_ORIGIN_USERDEFINED_MEMORY_A6, 5=DEM_DTC_ORIGIN_USERDEFINED_MEMORY_A7, 5=DEM_DTC_ORIGIN_USERDEFINED_MEMORY_A8, 5=DEM_DTC_ORIGIN_USERDEFINED_MEMORY_A9, 5=DEM_DTC_ORIGIN_USERDEFINED_MEMORY_AA, 5=DEM_DTC_ORIGIN_USERDEFINED_MEMORY_AB, 5=DEM_DTC_ORIGIN_USERDEFINED_MEMORY_AC, 5=DEM_DTC_ORIGIN_USERDEFINED_MEMORY_AD, 5=DEM_DTC_ORIGIN_USERDEFINED_MEMORY_AE, 5=DEM_DTC_ORIGIN_USERDEFINED_MEMORY_AF, 5=DEM_DTC_ORIGIN_USERDEFINED_MEMORY_B0, 5=DEM_DTC_ORIGIN_USERDEFINED_MEMORY_B1, 5=DEM_DTC_ORIGIN_USERDEFINED_MEMORY_B2, 5=DEM_DTC_ORIGIN_USERDEFINED_MEMORY_B3, 5=DEM_DTC_ORIGIN_USERDEFINED_MEMORY_B4, 5=DEM_DTC_ORIGIN_USERDEFINED_MEMORY_B5, 5=DEM_DTC_ORIGIN_USERDEFINED_MEMORY_B6, 5=DEM_DTC_ORIGIN_USERDEFINED_MEMORY_B7, 5=DEM_DTC_ORIGIN_USERDEFINED_MEMORY_B8, 5=DEM_DTC_ORIGIN_USERDEFINED_MEMORY_B9, 5=DEM_DTC_ORIGIN_USERDEFINED_MEMORY_BA, 5=DEM_DTC_ORIGIN_USERDEFINED_MEMORY_BB, 5=DEM_DTC_ORIGIN_USERDEFINED_MEMORY_BC, 5=DEM_DTC_ORIGIN_USERDEFINED_MEMORY_BD, 5=DEM_DTC_ORIGIN_USERDEFINED_MEMORY_BE, 5=DEM_DTC_ORIGIN_USERDEFINED_MEMORY_BF, 5=DEM_DTC_ORIGIN_USERDEFINED_MEMORY_C0, 5=DEM_DTC_ORIGIN_USERDEFINED_MEMORY_C1, 5=DEM_DTC_ORIGIN_USERDEFINED_MEMORY_C2, 5=DEM_DTC_ORIGIN_USERDEFINED_MEMORY_C3, 5=DEM_DTC_ORIGIN_USERDEFINED_MEMORY_C4, 5=DEM_DTC_ORIGIN_USERDEFINED_MEMORY_C5, 5=DEM_DTC_ORIGIN_USERDEFINED_MEMORY_C6, 5=DEM_DTC_ORIGIN_USERDEFINED_MEMORY_C7, 5=DEM_DTC_ORIGIN_USERDEFINED_MEMORY_C8, 5=DEM_DTC_ORIGIN_USERDEFINED_MEMORY_C9, 5=DEM_DTC_ORIGIN_USERDEFINED_MEMORY_CA, 5=DEM_DTC_ORIGIN_USERDEFINED_MEMORY_CB, 5=DEM_DTC_ORIGIN_USERDEFINED_MEMORY_CC, 5=DEM_DTC_ORIGIN_USERDEFINED_MEMORY_CD, 5=DEM_DTC_ORIGIN_USERDEFINED_MEMORY_CE, 5=DEM_DTC_ORIGIN_USERDEFINED_MEMORY_CF, 5=DEM_DTC_ORIGIN_USERDEFINED_MEMORY_D0, 5=DEM_DTC_ORIGIN_USERDEFINED_MEMORY_D1, 5=DEM_DTC_ORIGIN_USERDEFINED_MEMORY_D2, 5=DEM_DTC_ORIGIN_USERDEFINED_MEMORY_D3, 5=DEM_DTC_ORIGIN_USERDEFINED_MEMORY_D4, 5=DEM_DTC_ORIGIN_USERDEFINED_MEMORY_D5, 5=DEM_DTC_ORIGIN_USERDEFINED_MEMORY_D6, 5=DEM_DTC_ORIGIN_USERDEFINED_MEMORY_D7, 5=DEM_DTC_ORIGIN_USERDEFINED_MEMORY_D8, 5=DEM_DTC_ORIGIN_USERDEFINED_MEMORY_D9, 5=DEM_DTC_ORIGIN_USERDEFINED_MEMORY_DA, 5=DEM_DTC_ORIGIN_USERDEFINED_MEMORY_DB, 5=DEM_DTC_ORIGIN_USERDEFINED_MEMORY_DC, 5=DEM_DTC_ORIGIN_USERDEFINED_MEMORY_DD, 5=DEM_DTC_ORIGIN_USERDEFINED_MEMORY_DE, 5=DEM_DTC_ORIGIN_USERDEFINED_MEMORY_DF, 5=DEM_DTC_ORIGIN_USERDEFINED_MEMORY_E0, 5=DEM_DTC_ORIGIN_USERDEFINED_MEMORY_E1, 5=DEM_DTC_ORIGIN_USERDEFINED_MEMORY_E2, 5=DEM_DTC_ORIGIN_USERDEFINED_MEMORY_E3, 5=DEM_DTC_ORIGIN_USERDEFINED_MEMORY_E4, 5=DEM_DTC_ORIGIN_USERDEFINED_MEMORY_E5, 5=DEM_DTC_ORIGIN_USERDEFINED_MEMORY_E6, 5=DEM_DTC_ORIGIN_USERDEFINED_MEMORY_E7, 5=DEM_DTC_ORIGIN_USERDEFINED_MEMORY_E8, 5=DEM_DTC_ORIGIN_USERDEFINED_MEMORY_E9, 5=DEM_DTC_ORIGIN_USERDEFINED_MEMORY_EA, 5=DEM_DTC_ORIGIN_USERDEFINED_MEMORY_EB, 5=DEM_DTC_ORIGIN_USERDEFINED_MEMORY_EC, 5=DEM_DTC_ORIGIN_USERDEFINED_MEMORY_ED, 5=DEM_DTC_ORIGIN_USERDEFINED_MEMORY_EE, 5=DEM_DTC_ORIGIN_USERDEFINED_MEMORY_EF, 5=DEM_DTC_ORIGIN_USERDEFINED_MEMORY_F0, 5=DEM_DTC_ORIGIN_USERDEFINED_MEMORY_F1, 5=DEM_DTC_ORIGIN_USERDEFINED_MEMORY_F2, 5=DEM_DTC_ORIGIN_USERDEFINED_MEMORY_F3, 5=DEM_DTC_ORIGIN_USERDEFINED_MEMORY_F4, 5=DEM_DTC_ORIGIN_USERDEFINED_MEMORY_F5, 5=DEM_DTC_ORIGIN_USERDEFINED_MEMORY_F6, 5=DEM_DTC_ORIGIN_USERDEFINED_MEMORY_F7, 5=DEM_DTC_ORIGIN_USERDEFINED_MEMORY_F8, 5=DEM_DTC_ORIGIN_USERDEFINED_MEMORY_F9, 5=DEM_DTC_ORIGIN_USERDEFINED_MEMORY_FA, 5=DEM_DTC_ORIGIN_USERDEFINED_MEMORY_FB, 5=DEM_DTC_ORIGIN_USERDEFINED_MEMORY_FC, 5=DEM_DTC_ORIGIN_USERDEFINED_MEMORY_FD, 5=DEM_DTC_ORIGIN_USERDEFINED_MEMORY_FE, 5=DEM_DTC_ORIGIN_USERDEFINED_MEMORY_FF}, implementation-data-type=uint16
    Dem_DTCFormatType: compu {0=DEM_DTC_FORMAT_OBD, 1=DEM_DTC_FORMAT_UDS, 2=DEM_DTC_FORMAT_J1939}, implementation-data-type=ImplementationDataTypes/uint8
    Dem_OperationCycleStateType: compu {0=DEM_CYCLE_STATE_START, 1=DEM_CYCLE_STATE_END}, implementation-data-type=ImplementationDataTypes/uint8
    Dem_IndicatorStatusType: compu {0=DEM_INDICATOR_OFF, 1=DEM_INDICATOR_CONTINUOUS, 2=DEM_INDICATOR_BLINKING, 3=DEM_INDICATOR_BLINK_CONT, 4=DEM_INDICATOR_SLOW_FLASH, 5=DEM_INDICATOR_FAST_FLASH, 6=DEM_INDICATOR_ON_DEMAND, 7=DEM_INDICATOR_SHORT}, implementation-data-type=ImplementationDataTypes/uint8
    Dem_DTCKindType: compu {1=DEM_DTC_KIND_ALL_DTCS, 2=DEM_DTC_KIND_EMISSION_REL_DTCS}, implementation-data-type=ImplementationDataTypes/uint8
    Dem_IumprDenomCondIdType: compu {1=DEM_IUMPR_GENERAL_DENOMINATOR, 2=DEM_IUMPR_DEN_COND_COLDSTART, 3=DEM_IUMPR_DEN_COND_EVAP, 4=DEM_IUMPR_DEN_COND_500MI}, implementation-data-type=ImplementationDataTypes/uint8
    Dem_IumprDenomCondStatusType: compu {0=DEM_IUMPR_DEN_STATUS_NOT_REACHED, 1=DEM_IUMPR_DEN_STATUS_REACHED, 2=DEM_IUMPR_DEN_STATUS_INHIBITED}, implementation-data-type=ImplementationDataTypes/uint8
    Dem_DebounceResetStatusType: compu {0=DEM_DEBOUNCE_STATUS_FREEZE, 1=DEM_DEBOUNCE_STATUS_RESET}, implementation-data-type=ImplementationDataTypes/uint8
    Dem_IumprReadinessGroupType: compu {0=DEM_IUMPR_BOOSTPRS, 1=DEM_IUMPR_CAT1, 2=DEM_IUMPR_CAT2, 3=DEM_IUMPR_EGR, 4=DEM_IUMPR_EGSENSOR, 5=DEM_IUMPR_EVAP, 6=DEM_IUMPR_NMHCCAT, 7=DEM_IUMPR_NOXADSORB, 8=DEM_IUMPR_NOXCAT, 9=DEM_IUMPR_OXS1, 10=DEM_IUMPR_OXS2, 11=DEM_IUMPR_PMFILTER, 12=DEM_IUMPR_PRIVATE, 13=DEM_IUMPR_SAIR, 14=DEM_IUMPR_SECOXS1, 15=DEM_IUMPR_SECOXS2, 16=DEM_IUMPR_FLSYS, 255=DEM_IUMPR_ALLGROUPS}, implementation-data-type=ImplementationDataTypes/uint8
    Dem_DTRControlType: compu {0=DEM_DTR_CTL_NORMAL, 1=DEM_DTR_CTL_NO_MAX, 2=DEM_DTR_CTL_NO_MIN, 3=DEM_DTR_CTL_RESET, 4=DEM_DTR_CTL_INVISIBLE}, implementation-data-type=ImplementationDataTypes/uint8
    Dem_DebouncingStateType: compu {mask 1: 1=DEM_TEMPORARILY_DEFECTIVE, mask 2: 2=DEM_FINALLY_DEFECTIVE, mask 4: 4=DEM_TEMPORARILY_HEALED, mask 8: 8=DEM_TEST_COMPLETE, mask 16: 16=DEM_DTR_UPDATE}, range raw 0..255, implementation-data-type=ImplementationDataTypes/uint8
    Dem_DTCSeverityType:
      compu {mask 255: 0=DEM_SEVERITY_NO_SEVERITY, mask 31: 2=DEM_SEVERITY_WWHOBD_CLASS_A, mask 31: 4=DEM_SEVERITY_WWHOBD_CLASS_B1, mask 31: 8=DEM_SEVERITY_WWHOBD_CLASS_B2, mask 31: 16=DEM_SEVERITY_WWHOBD_CLASS_C, mask 31: 1=DEM_SEVERITY_WWHOBD_CLASS_NO_CLASS, mask 224: 64=DEM_SEVERITY_CHECK_AT_NEXT_HALT, mask 224: 128=DEM_SEVERITY_CHECK_IMMEDIATELY, mask 224: 32=DEM_SEVERITY_MAINTENANCE_ONLY}
      range raw 0..255
      implementation-data-type=ImplementationDataTypes/uint8
    Dem_UdsStatusByteType: compu {mask 1: 1=DEM_UDS_STATUS_TF, mask 2: 2=DEM_UDS_STATUS_TFTOC, mask 4: 4=DEM_UDS_STATUS_PDTC, mask 8: 8=DEM_UDS_STATUS_CDTC, mask 16: 16=DEM_UDS_STATUS_TNCSLC, mask 32: 32=DEM_UDS_STATUS_TFSLC, mask 64: 64=DEM_UDS_STATUS_TNCTOC, mask 128: 128=DEM_UDS_STATUS_WIR}, range raw 0..255, implementation-data-type=ImplementationDataTypes/uint8
    Dem_MonitorStatusType: compu {mask 1: 1=DEM_MONITOR_STATUS_TF, mask 2: 2=DEM_MONITOR_STATUS_TNCTOC}, range raw 0..255, implementation-data-type=ImplementationDataTypes/uint8
    Dem_MaxDataValueType: category=ARRAY, sw-calibration-access=READ-ONLY
      element Dem_MaxDataValueTypeElement: array-size=4, array-size-semantics=FIXED-SIZE, implementation-data-type=ImplementationDataTypes/uint8
    DataArrayType_uint8_4: category=ARRAY, sw-calibration-access=READ-ONLY
      element DataArrayType_uint8_4Element: array-size=4, array-size-semantics=FIXED-SIZE, implementation-data-type=ImplementationDataTypes/uint8
package /MICROSAR/Dem_swc/Interfaces
  9 x client server interface, all with is-service=true, service-kind=DIAGNOSTIC-EVENT-MANAGER:
    DemServices
      operation GetPostRunRequested: possible-error=DemServices/E_NOT_OK
        arg IsRequested: type=ImplementationDataTypes/boolean, direction=OUT
      operation GetDTCStatusAvailabilityMask: possible-error=DemServices/E_NOT_OK
        arg ClientId: type=ImplementationDataTypes/uint8, direction=IN
        arg DTCStatusMask: type=ImplementationDataTypes/uint8, direction=OUT
      error E_NOT_OK: error-code=1
    ClearDTC
      operation ClearDTC: possible-error=[ClearDTC/E_NOT_OK, DEM_CLEAR_FAILED, DEM_PENDING, DEM_CLEAR_BUSY, DEM_CLEAR_MEMORY_ERROR, DEM_WRONG_DTC, DEM_WRONG_DTCORIGIN]
      operation SelectDTC: possible-error=[ClearDTC/E_OK, ClearDTC/E_NOT_OK]
        arg DTC: type=ImplementationDataTypes/uint32, direction=IN
        arg DTCFormat: type=DataTypes/Dem_DTCFormatType, direction=IN
        arg DTCOrigin: type=DataTypes/Dem_DTCOriginType, direction=IN
      8 x error:
        E_OK: error-code=0
        E_NOT_OK: error-code=1
        DEM_CLEAR_FAILED: error-code=7
        DEM_PENDING: error-code=4
        DEM_CLEAR_BUSY: error-code=5
        DEM_CLEAR_MEMORY_ERROR: error-code=6
        DEM_WRONG_DTC: error-code=8
        DEM_WRONG_DTCORIGIN: error-code=9
    EvMemOverflowIndication
      operation GetEventMemoryOverflow: possible-error=EvMemOverflowIndication/E_NOT_OK
        arg OverflowIndication: type=ImplementationDataTypes/boolean, direction=OUT
      operation GetNumberOfEventMemoryEntries: possible-error=EvMemOverflowIndication/E_NOT_OK
        arg NumberOfEventMemoryEntries: type=ImplementationDataTypes/uint8, direction=OUT
      error E_NOT_OK: error-code=1
    OperationCycle
      operation GetOperationCycleState: possible-error=[OperationCycle/E_OK, OperationCycle/E_NOT_OK]
        arg CycleState: type=Dem_OperationCycleStateType, direction=OUT
      operation SetOperationCycleState: possible-error=[OperationCycle/E_OK, OperationCycle/E_NOT_OK]
        arg CycleState: type=Dem_OperationCycleStateType, direction=IN
      error E_OK: error-code=0
      error E_NOT_OK: error-code=1
    GeneralDiagnosticInfo
      11 x operation:
        GetEventUdsStatus: possible-error=GeneralDiagnosticInfo/E_NOT_OK
          arg EventId: type=Dem_EventIdType, direction=IN
          arg UDSStatusByte: type=DataTypes/Dem_UdsStatusByteType, direction=OUT
        GetEventStatus: possible-error=GeneralDiagnosticInfo/E_NOT_OK
          arg EventId: type=Dem_EventIdType, direction=IN
          arg UDSStatusByte: type=DataTypes/Dem_UdsStatusByteType, direction=OUT
        GetEventFailed: possible-error=GeneralDiagnosticInfo/E_NOT_OK
          arg EventId: type=Dem_EventIdType, direction=IN
          arg EventFailed: type=ImplementationDataTypes/boolean, direction=OUT
        GetEventTested: possible-error=GeneralDiagnosticInfo/E_NOT_OK
          arg EventId: type=Dem_EventIdType, direction=IN
          arg EventTested: type=ImplementationDataTypes/boolean, direction=OUT
        GetDTCOfEvent: possible-error=[GeneralDiagnosticInfo/E_NOT_OK, GeneralDiagnosticInfo/DEM_E_NO_DTC_AVAILABLE]
          arg EventId: type=Dem_EventIdType, direction=IN
          arg DTCFormat: type=DataTypes/Dem_DTCFormatType, direction=IN
          arg DTCOfEvent: type=ImplementationDataTypes/uint32, direction=OUT
        GetFaultDetectionCounter: possible-error=[GeneralDiagnosticInfo/E_NOT_OK, GeneralDiagnosticInfo/DEM_E_NO_FDC_AVAILABLE]
          arg EventId: type=Dem_EventIdType, direction=IN
          arg FaultDetectionCounter: type=sint8, direction=OUT
        GetEventFreezeFrameDataEx: possible-error=[GeneralDiagnosticInfo/E_NOT_OK, GeneralDiagnosticInfo/DEM_BUFFER_TOO_SMALL, GeneralDiagnosticInfo/DEM_NO_SUCH_ELEMENT]
          5 x arg:
            EventId: type=Dem_EventIdType, direction=IN
            RecordNumber: type=ImplementationDataTypes/uint8, direction=IN
            DataId: type=uint16, direction=IN
            DestBuffer: type=Dem_MaxDataValueType, direction=OUT
            BufSize: type=uint16, direction=INOUT
        GetEventExtendedDataRecordEx: possible-error=[GeneralDiagnosticInfo/E_NOT_OK, GeneralDiagnosticInfo/DEM_BUFFER_TOO_SMALL, GeneralDiagnosticInfo/DEM_NO_SUCH_ELEMENT]
          4 x arg:
            EventId: type=Dem_EventIdType, direction=IN
            RecordNumber: type=ImplementationDataTypes/uint8, direction=IN
            DestBuffer: type=Dem_MaxDataValueType, direction=OUT
            BufSize: type=uint16, direction=INOUT
        GetEventEnableCondition: possible-error=GeneralDiagnosticInfo/E_NOT_OK
          arg EventId: type=Dem_EventIdType, direction=IN
          arg ConditionFullfilled: type=ImplementationDataTypes/boolean, direction=OUT
        GetDebouncingOfEvent: possible-error=GeneralDiagnosticInfo/E_NOT_OK
          arg EventId: type=Dem_EventIdType, direction=IN
          arg DebouncingState: type=Dem_DebouncingStateType, direction=OUT
        GetMonitorStatus: possible-error=GeneralDiagnosticInfo/E_NOT_OK
          arg EventId: type=Dem_EventIdType, direction=IN
          arg MonitorStatus: type=Dem_MonitorStatusType, direction=OUT
      5 x error:
        E_NOT_OK: error-code=1
        DEM_E_NO_DTC_AVAILABLE: error-code=10
        DEM_E_NO_FDC_AVAILABLE: error-code=14
        DEM_BUFFER_TOO_SMALL: error-code=21
        DEM_NO_SUCH_ELEMENT: error-code=48
    DiagnosticInfo
      11 x operation:
        GetEventUdsStatus: possible-error=DiagnosticInfo/E_NOT_OK
          arg UDSStatusByte: type=DataTypes/Dem_UdsStatusByteType, direction=OUT
        GetEventStatus: possible-error=DiagnosticInfo/E_NOT_OK
          arg UDSStatusByte: type=DataTypes/Dem_UdsStatusByteType, direction=OUT
        GetEventFailed: possible-error=DiagnosticInfo/E_NOT_OK
          arg EventFailed: type=ImplementationDataTypes/boolean, direction=OUT
        GetEventTested: possible-error=DiagnosticInfo/E_NOT_OK
          arg EventTested: type=ImplementationDataTypes/boolean, direction=OUT
        GetDTCOfEvent: possible-error=[DiagnosticInfo/E_NOT_OK, DiagnosticInfo/DEM_E_NO_DTC_AVAILABLE]
          arg DTCFormat: type=DataTypes/Dem_DTCFormatType, direction=IN
          arg DTCOfEvent: type=ImplementationDataTypes/uint32, direction=OUT
        GetFaultDetectionCounter: possible-error=[DiagnosticInfo/E_NOT_OK, DiagnosticInfo/DEM_E_NO_FDC_AVAILABLE]
          arg FaultDetectionCounter: type=sint8, direction=OUT
        GetEventFreezeFrameDataEx: possible-error=[DiagnosticInfo/E_NOT_OK, DiagnosticInfo/DEM_BUFFER_TOO_SMALL, DiagnosticInfo/DEM_NO_SUCH_ELEMENT]
          4 x arg:
            RecordNumber: type=ImplementationDataTypes/uint8, direction=IN
            DataId: type=uint16, direction=IN
            DestBuffer: type=Dem_MaxDataValueType, direction=OUT
            BufSize: type=uint16, direction=INOUT
        GetEventExtendedDataRecordEx: possible-error=[DiagnosticInfo/E_NOT_OK, DiagnosticInfo/DEM_BUFFER_TOO_SMALL, DiagnosticInfo/DEM_NO_SUCH_ELEMENT]
          arg RecordNumber: type=ImplementationDataTypes/uint8, direction=IN
          arg DestBuffer: type=Dem_MaxDataValueType, direction=OUT
          arg BufSize: type=uint16, direction=INOUT
        GetEventEnableCondition: possible-error=DiagnosticInfo/E_NOT_OK
          arg ConditionFullfilled: type=ImplementationDataTypes/boolean, direction=OUT
        GetDebouncingOfEvent: possible-error=DiagnosticInfo/E_NOT_OK
          arg DebouncingState: type=Dem_DebouncingStateType, direction=OUT
        GetMonitorStatus: possible-error=DiagnosticInfo/E_NOT_OK
          arg MonitorStatus: type=Dem_MonitorStatusType, direction=OUT
      5 x error:
        E_NOT_OK: error-code=1
        DEM_E_NO_DTC_AVAILABLE: error-code=10
        DEM_E_NO_FDC_AVAILABLE: error-code=14
        DEM_BUFFER_TOO_SMALL: error-code=21
        DEM_NO_SUCH_ELEMENT: error-code=48
    CSDataServices_OccurrenceCounter_OccurenceCounter
      operation ReadData: possible-error=CSDataServices_OccurrenceCounter_OccurenceCounter/E_NOT_OK
        arg Data: type=DataArrayType_uint8_4, direction=OUT
      error E_NOT_OK: error-code=1
    CSDataServices_OdometerValue_OdometerValue
      operation ReadData: possible-error=CSDataServices_OdometerValue_OdometerValue/E_NOT_OK
        arg Data: type=DataArrayType_uint8_4, direction=OUT
      error E_NOT_OK: error-code=1
    DiagnosticMonitor
      11 x operation:
        SetEventStatus: possible-error=DiagnosticMonitor/E_NOT_OK
          arg EventStatus: type=Dem_EventStatusType, direction=IN
        ResetEventStatus: possible-error=DiagnosticMonitor/E_NOT_OK
        ResetEventDebounceStatus: possible-error=DiagnosticMonitor/E_NOT_OK
          arg DebounceResetStatus: type=Dem_DebounceResetStatusType, direction=IN
        GetEventUdsStatus: possible-error=DiagnosticMonitor/E_NOT_OK
          arg UDSStatusByte: type=DataTypes/Dem_UdsStatusByteType, direction=OUT
        GetEventStatus: possible-error=DiagnosticMonitor/E_NOT_OK
          arg UDSStatusByte: type=DataTypes/Dem_UdsStatusByteType, direction=OUT
        GetEventFailed: possible-error=DiagnosticMonitor/E_NOT_OK
          arg EventFailed: type=ImplementationDataTypes/boolean, direction=OUT
        GetEventTested: possible-error=DiagnosticMonitor/E_NOT_OK
          arg EventTested: type=ImplementationDataTypes/boolean, direction=OUT
        GetDTCOfEvent: possible-error=[DiagnosticMonitor/E_NOT_OK, DiagnosticMonitor/DEM_E_NO_DTC_AVAILABLE]
          arg DTCFormat: type=DataTypes/Dem_DTCFormatType, direction=IN
          arg DTCOfEvent: type=ImplementationDataTypes/uint32, direction=OUT
        GetFaultDetectionCounter: possible-error=[DiagnosticMonitor/E_NOT_OK, DiagnosticMonitor/DEM_E_NO_FDC_AVAILABLE]
          arg FaultDetectionCounter: type=sint8, direction=OUT
        GetEventFreezeFrameDataEx: possible-error=[DiagnosticMonitor/E_NOT_OK, DiagnosticMonitor/DEM_BUFFER_TOO_SMALL, DiagnosticMonitor/DEM_NO_SUCH_ELEMENT]
          4 x arg:
            RecordNumber: type=ImplementationDataTypes/uint8, direction=IN
            DataId: type=uint16, direction=IN
            DestBuffer: type=Dem_MaxDataValueType, direction=OUT
            BufSize: type=uint16, direction=INOUT
        GetEventExtendedDataRecordEx: possible-error=[DiagnosticMonitor/E_NOT_OK, DiagnosticMonitor/DEM_BUFFER_TOO_SMALL, DiagnosticMonitor/DEM_NO_SUCH_ELEMENT]
          arg RecordNumber: type=ImplementationDataTypes/uint8, direction=IN
          arg DestBuffer: type=Dem_MaxDataValueType, direction=OUT
          arg BufSize: type=uint16, direction=INOUT
      5 x error:
        E_NOT_OK: error-code=1
        DEM_E_NO_DTC_AVAILABLE: error-code=10
        DEM_E_NO_FDC_AVAILABLE: error-code=14
        DEM_BUFFER_TOO_SMALL: error-code=21
        DEM_NO_SUCH_ELEMENT: error-code=48
package /MICROSAR/Dem_swc/ComponentTypes
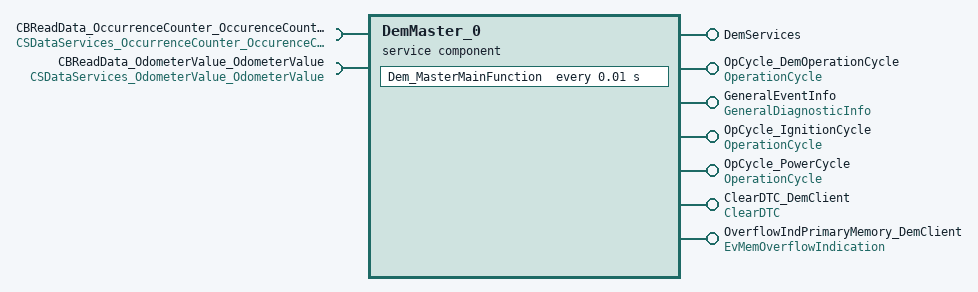
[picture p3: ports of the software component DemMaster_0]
  service sw component type DemMaster_0: category=SERVICE_COMPONENT
    5 x provide port:
      DemServices: provided-interface=DemServices
      OpCycle_DemOperationCycle: provided-interface=OperationCycle
      GeneralEventInfo: provided-interface=GeneralDiagnosticInfo
      OpCycle_IgnitionCycle: provided-interface=OperationCycle
      OpCycle_PowerCycle: provided-interface=OperationCycle
    require port CBReadData_OccurrenceCounter_OccurenceCounter: required-interface=CSDataServices_OccurrenceCounter_OccurenceCounter
    require port CBReadData_OdometerValue_OdometerValue: required-interface=CSDataServices_OdometerValue_OdometerValue
    provide port ClearDTC_DemClient: provided-interface=ClearDTC
    provide port OverflowIndPrimaryMemory_DemClient: provided-interface=EvMemOverflowIndication
    behavior DemMaster_0InternalBehavior: handle-termination-and-restart=NO-SUPPORT, included-data-type-set=data-type=[Dem_EventIdType, Dem_RatioIdType, Dem_EventStatusType, DataTypes/Dem_UdsStatusByteType, DataTypes/Dem_DTCFormatType, Dem_InitMonitorReasonType, Dem_OperationCycleStateType, Dem_DTCStatusMaskType, Dem_IndicatorStatusType, Dem_MaxDataValueType, DataTypes/Dem_DTCKindType, DataTypes/Dem_DTCGroupType, Dem_IumprDenomCondIdType, Dem_IumprDenomCondStatusType, Dem_DebounceResetStatusType, Dem_DebouncingStateType, Dem_IumprReadinessGroupType, Dem_DTRControlType, Dem_DTCSeverityType, Dem_MonitorStatusType]
      timing event Timer_Dem_MasterMainFunction: start-on-event=Dem_MasterMainFunction, period=0.01
      23 x operation invoked event:
        OpEventPostRunRequested_GetPostRunRequested_DemServices: start-on-event=PostRunRequested, operation=DemServices.GetPostRunRequested
        OpEventGetDTCStatusAvailabilityMask_GetDTCStatusAvailabilityMask_DemServices: start-on-event=GetDTCStatusAvailabilityMask, operation=DemServices.GetDTCStatusAvailabilityMask
        OpEventGetOperationCycleState_GetOperationCycleState_OpCycle_DemOperationCycle: start-on-event=GetOperationCycleState, operation=OpCycle_DemOperationCycle.GetOperationCycleState
        OpEventSetOperationCycleState_SetOperationCycleState_OpCycle_DemOperationCycle: start-on-event=SetOperationCycleState, operation=OpCycle_DemOperationCycle.SetOperationCycleState
        OpEventGetEventUdsStatus_GetEventUdsStatus_GeneralEventInfo: start-on-event=DemMaster_0InternalBehavior/GetEventUdsStatus, operation=GeneralEventInfo.GetEventUdsStatus
        OpEventGetEventStatus_GetEventStatus_GeneralEventInfo: start-on-event=DemMaster_0InternalBehavior/GetEventStatus, operation=GeneralEventInfo.GetEventStatus
        OpEventGetEventFailed_GetEventFailed_GeneralEventInfo: start-on-event=DemMaster_0InternalBehavior/GetEventFailed, operation=GeneralEventInfo.GetEventFailed
        OpEventGetEventTested_GetEventTested_GeneralEventInfo: start-on-event=DemMaster_0InternalBehavior/GetEventTested, operation=GeneralEventInfo.GetEventTested
        OpEventGetDTCOfEvent_GetDTCOfEvent_GeneralEventInfo: start-on-event=DemMaster_0InternalBehavior/GetDTCOfEvent, operation=GeneralEventInfo.GetDTCOfEvent
        OpEventGetFaultDetectionCounter_GetFaultDetectionCounter_GeneralEventInfo: start-on-event=DemMaster_0InternalBehavior/GetFaultDetectionCounter, operation=GeneralEventInfo.GetFaultDetectionCounter
        OpEventGetEventFreezeFrameDataEx_GetEventFreezeFrameDataEx_GeneralEventInfo: start-on-event=DemMaster_0InternalBehavior/GetEventFreezeFrameDataEx, operation=GeneralEventInfo.GetEventFreezeFrameDataEx
        OpEventGetEventExtendedDataRecordEx_GetEventExtendedDataRecordEx_GeneralEventInfo: start-on-event=DemMaster_0InternalBehavior/GetEventExtendedDataRecordEx, operation=GeneralEventInfo.GetEventExtendedDataRecordEx
        OpEventGetEventEnableCondition_GetEventEnableCondition_GeneralEventInfo: start-on-event=DemMaster_0InternalBehavior/GetEventEnableCondition, operation=GeneralEventInfo.GetEventEnableCondition
        OpEventGetDebouncingOfEvent_GetDebouncingOfEvent_GeneralEventInfo: start-on-event=DemMaster_0InternalBehavior/GetDebouncingOfEvent, operation=GeneralEventInfo.GetDebouncingOfEvent
        OpEventGetMonitorStatus_GetMonitorStatus_GeneralEventInfo: start-on-event=DemMaster_0InternalBehavior/GetMonitorStatus, operation=GeneralEventInfo.GetMonitorStatus
        OpEventGetOperationCycleState_GetOperationCycleState_OpCycle_IgnitionCycle: start-on-event=GetOperationCycleState, operation=OpCycle_IgnitionCycle.GetOperationCycleState
        OpEventGetOperationCycleState_GetOperationCycleState_OpCycle_PowerCycle: start-on-event=GetOperationCycleState, operation=OpCycle_PowerCycle.GetOperationCycleState
        OpEventSetOperationCycleState_SetOperationCycleState_OpCycle_IgnitionCycle: start-on-event=SetOperationCycleState, operation=OpCycle_IgnitionCycle.SetOperationCycleState
        OpEventSetOperationCycleState_SetOperationCycleState_OpCycle_PowerCycle: start-on-event=SetOperationCycleState, operation=OpCycle_PowerCycle.SetOperationCycleState
        OpEventClearDTC_ClearDTC_ClearDTC_DemClient: start-on-event=ClearDTC, operation=ClearDTC_DemClient.ClearDTC
        OpEventSelectDTC_SelectDTC_ClearDTC_DemClient: start-on-event=SelectDTC, operation=ClearDTC_DemClient.SelectDTC
        OpEventGetEventMemoryOverflow_GetEventMemoryOverflow_OverflowIndPrimaryMemory_DemClient: start-on-event=GetEventMemoryOverflow, operation=OverflowIndPrimaryMemory_DemClient.GetEventMemoryOverflow
        OpEventGetNumberOfEventMemoryEntries_GetNumberOfEventMemoryEntries_OverflowIndPrimaryMemory_DemClient: start-on-event=GetNumberOfEventMemoryEntries, operation=OverflowIndPrimaryMemory_DemClient.GetNumberOfEventMemoryEntries
      port-api-options:
        enable-take-address=true, indirect-api=false, port=DemServices
        {enable-take-address=true, indirect-api=false, port-defined-argument-value{value=0, value-type=Dem_OperationCycleIdType}, port=OpCycle_DemOperationCycle}
        enable-take-address=true, indirect-api=false, port=DemMaster_0/GeneralEventInfo
        {enable-take-address=true, indirect-api=false, port-defined-argument-value{value=1, value-type=Dem_OperationCycleIdType}, port=OpCycle_IgnitionCycle}
        {enable-take-address=true, indirect-api=false, port-defined-argument-value{value=2, value-type=Dem_OperationCycleIdType}, port=OpCycle_PowerCycle}
        enable-take-address=true, indirect-api=false, port=CBReadData_OccurrenceCounter_OccurenceCounter
        enable-take-address=true, indirect-api=false, port=CBReadData_OdometerValue_OdometerValue
        {enable-take-address=true, indirect-api=false, port-defined-argument-value{value=0, value-type=ImplementationDataTypes/uint8}, port=ClearDTC_DemClient}
        {enable-take-address=true, indirect-api=false, port-arg-values=[{value=0, value-type=ImplementationDataTypes/uint8}, {value=1, value-type=DataTypes/Dem_DTCOriginType}], port=OverflowIndPrimaryMemory_DemClient}
      20 x runnable:
        Dem_MasterMainFunction
          sync call OpServerCallDem_MasterMainFunction_ReadData_CBReadData_OccurrenceCounter_OccurenceCounter: operation=CBReadData_OccurrenceCounter_OccurenceCounter.ReadData, timeout=0
          sync call OpServerCallDem_MasterMainFunction_ReadData_CBReadData_OdometerValue_OdometerValue: operation=CBReadData_OdometerValue_OdometerValue.ReadData, timeout=0
        PostRunRequested: can-be-invoked-concurrently=true, symbol=Dem_PostRunRequested
        GetDTCStatusAvailabilityMask: can-be-invoked-concurrently=true, symbol=Dem_GetDTCStatusAvailabilityMask
        GetOperationCycleState: can-be-invoked-concurrently=true, symbol=Dem_GetOperationCycleState
        SetOperationCycleState: can-be-invoked-concurrently=true, symbol=Dem_SetOperationCycleState
        GetEventUdsStatus: can-be-invoked-concurrently=true, symbol=Dem_GetEventUdsStatus
        GetEventStatus: can-be-invoked-concurrently=true, symbol=Dem_GetEventUdsStatus
        GetEventFailed: can-be-invoked-concurrently=true, symbol=Dem_GetEventFailed
        GetEventTested: can-be-invoked-concurrently=true, symbol=Dem_GetEventTested
        GetDTCOfEvent: can-be-invoked-concurrently=true, symbol=Dem_GetDTCOfEvent
        GetFaultDetectionCounter: can-be-invoked-concurrently=true, symbol=Dem_GetFaultDetectionCounter
        GetEventFreezeFrameDataEx: can-be-invoked-concurrently=true, symbol=Dem_GetEventFreezeFrameDataEx
        GetEventExtendedDataRecordEx: can-be-invoked-concurrently=true, symbol=Dem_GetEventExtendedDataRecordEx
        GetEventEnableCondition: can-be-invoked-concurrently=true, symbol=Dem_GetEventEnableCondition
        GetDebouncingOfEvent: can-be-invoked-concurrently=true, symbol=Dem_GetDebouncingOfEvent
        GetMonitorStatus: can-be-invoked-concurrently=true, symbol=Dem_GetMonitorStatus
        ClearDTC: can-be-invoked-concurrently=true, symbol=Dem_ClearDTC
        SelectDTC: can-be-invoked-concurrently=true, symbol=Dem_SelectDTC
        GetEventMemoryOverflow: can-be-invoked-concurrently=true, symbol=Dem_GetEventMemoryOverflow
        GetNumberOfEventMemoryEntries: can-be-invoked-concurrently=true, symbol=Dem_GetNumberOfEventMemoryEntries
  swc implementation DemMaster_0Implementation: programming-language=C, behavior=DemMaster_0InternalBehavior
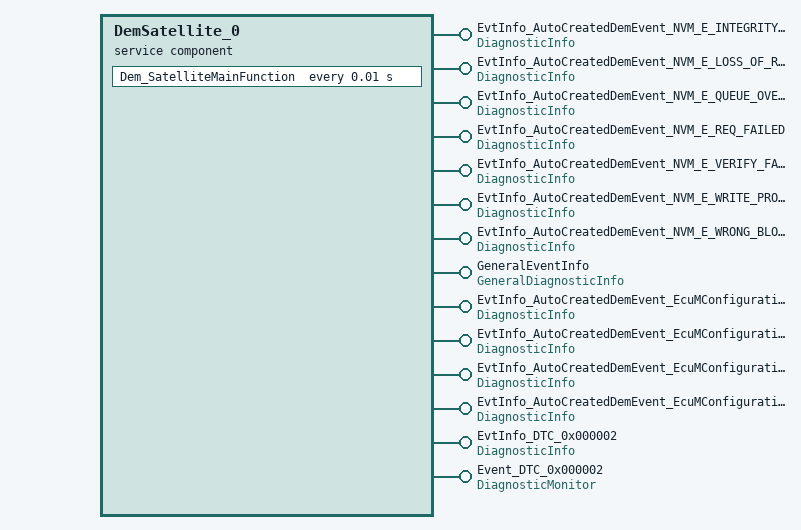
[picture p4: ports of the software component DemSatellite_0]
  service sw component type DemSatellite_0: category=SERVICE_COMPONENT
    14 x provide port:
      EvtInfo_AutoCreatedDemEvent_NVM_E_INTEGRITY_FAILED: provided-interface=DiagnosticInfo
      EvtInfo_AutoCreatedDemEvent_NVM_E_LOSS_OF_REDUNDANCY: provided-interface=DiagnosticInfo
      EvtInfo_AutoCreatedDemEvent_NVM_E_QUEUE_OVERFLOW: provided-interface=DiagnosticInfo
      EvtInfo_AutoCreatedDemEvent_NVM_E_REQ_FAILED: provided-interface=DiagnosticInfo
      EvtInfo_AutoCreatedDemEvent_NVM_E_VERIFY_FAILED: provided-interface=DiagnosticInfo
      EvtInfo_AutoCreatedDemEvent_NVM_E_WRITE_PROTECTED: provided-interface=DiagnosticInfo
      EvtInfo_AutoCreatedDemEvent_NVM_E_WRONG_BLOCK_ID: provided-interface=DiagnosticInfo
      GeneralEventInfo: provided-interface=GeneralDiagnosticInfo
      EvtInfo_AutoCreatedDemEvent_EcuMConfiguration_ECUM_E_ALL_RUN_REQUESTS_KILLED: provided-interface=DiagnosticInfo
      EvtInfo_AutoCreatedDemEvent_EcuMConfiguration_ECUM_E_CONFIGURATION_DATA_INCONSISTENT: provided-interface=DiagnosticInfo
      EvtInfo_AutoCreatedDemEvent_EcuMConfiguration_ECUM_E_RAM_CHECK_FAILED: provided-interface=DiagnosticInfo
      EvtInfo_AutoCreatedDemEvent_EcuMConfiguration_ECUM_E_IMPROPER_CALLER: provided-interface=DiagnosticInfo
      EvtInfo_DTC_0x000002: provided-interface=DiagnosticInfo
      Event_DTC_0x000002: provided-interface=DiagnosticMonitor
    behavior DemSatellite_0InternalBehavior: handle-termination-and-restart=NO-SUPPORT, included-data-type-set=data-type=[Dem_EventIdType, Dem_RatioIdType, Dem_EventStatusType, DataTypes/Dem_UdsStatusByteType, DataTypes/Dem_DTCFormatType, Dem_InitMonitorReasonType, Dem_OperationCycleStateType, Dem_DTCStatusMaskType, Dem_IndicatorStatusType, Dem_MaxDataValueType, DataTypes/Dem_DTCKindType, DataTypes/Dem_DTCGroupType, Dem_IumprDenomCondIdType, Dem_IumprDenomCondStatusType, Dem_DebounceResetStatusType, Dem_DebouncingStateType, Dem_IumprReadinessGroupType, Dem_DTRControlType, Dem_DTCSeverityType, Dem_MonitorStatusType]
      timing event Timer_Dem_SatelliteMainFunction: start-on-event=Dem_SatelliteMainFunction, period=0.01
      154 x operation invoked event:
        OpEventGetEventUdsStatus_GetEventUdsStatus_EvtInfo_AutoCreatedDemEvent_NVM_E_INTEGRITY_FAILED: start-on-event=DemSatellite_0InternalBehavior/GetEventUdsStatus, operation=EvtInfo_AutoCreatedDemEvent_NVM_E_INTEGRITY_FAILED.GetEventUdsStatus
        OpEventGetEventUdsStatus_GetEventUdsStatus_EvtInfo_AutoCreatedDemEvent_NVM_E_LOSS_OF_REDUNDANCY: start-on-event=DemSatellite_0InternalBehavior/GetEventUdsStatus, operation=EvtInfo_AutoCreatedDemEvent_NVM_E_LOSS_OF_REDUNDANCY.GetEventUdsStatus
        OpEventGetEventUdsStatus_GetEventUdsStatus_EvtInfo_AutoCreatedDemEvent_NVM_E_QUEUE_OVERFLOW: start-on-event=DemSatellite_0InternalBehavior/GetEventUdsStatus, operation=EvtInfo_AutoCreatedDemEvent_NVM_E_QUEUE_OVERFLOW.GetEventUdsStatus
        OpEventGetEventUdsStatus_GetEventUdsStatus_EvtInfo_AutoCreatedDemEvent_NVM_E_REQ_FAILED: start-on-event=DemSatellite_0InternalBehavior/GetEventUdsStatus, operation=EvtInfo_AutoCreatedDemEvent_NVM_E_REQ_FAILED.GetEventUdsStatus
        OpEventGetEventUdsStatus_GetEventUdsStatus_EvtInfo_AutoCreatedDemEvent_NVM_E_VERIFY_FAILED: start-on-event=DemSatellite_0InternalBehavior/GetEventUdsStatus, operation=EvtInfo_AutoCreatedDemEvent_NVM_E_VERIFY_FAILED.GetEventUdsStatus
        OpEventGetEventUdsStatus_GetEventUdsStatus_EvtInfo_AutoCreatedDemEvent_NVM_E_WRITE_PROTECTED: start-on-event=DemSatellite_0InternalBehavior/GetEventUdsStatus, operation=EvtInfo_AutoCreatedDemEvent_NVM_E_WRITE_PROTECTED.GetEventUdsStatus
        OpEventGetEventUdsStatus_GetEventUdsStatus_EvtInfo_AutoCreatedDemEvent_NVM_E_WRONG_BLOCK_ID: start-on-event=DemSatellite_0InternalBehavior/GetEventUdsStatus, operation=EvtInfo_AutoCreatedDemEvent_NVM_E_WRONG_BLOCK_ID.GetEventUdsStatus
        OpEventGetEventUdsStatus_GetEventUdsStatus_GeneralEventInfo: start-on-event=DemSatellite_0InternalBehavior/GetEventUdsStatus, operation=GeneralEventInfo.GetEventUdsStatus
        OpEventGetEventStatus_GetEventStatus_EvtInfo_AutoCreatedDemEvent_NVM_E_INTEGRITY_FAILED: start-on-event=DemSatellite_0InternalBehavior/GetEventStatus, operation=EvtInfo_AutoCreatedDemEvent_NVM_E_INTEGRITY_FAILED.GetEventStatus
        OpEventGetEventStatus_GetEventStatus_EvtInfo_AutoCreatedDemEvent_NVM_E_LOSS_OF_REDUNDANCY: start-on-event=DemSatellite_0InternalBehavior/GetEventStatus, operation=EvtInfo_AutoCreatedDemEvent_NVM_E_LOSS_OF_REDUNDANCY.GetEventStatus
        OpEventGetEventStatus_GetEventStatus_EvtInfo_AutoCreatedDemEvent_NVM_E_QUEUE_OVERFLOW: start-on-event=DemSatellite_0InternalBehavior/GetEventStatus, operation=EvtInfo_AutoCreatedDemEvent_NVM_E_QUEUE_OVERFLOW.GetEventStatus
        OpEventGetEventStatus_GetEventStatus_EvtInfo_AutoCreatedDemEvent_NVM_E_REQ_FAILED: start-on-event=DemSatellite_0InternalBehavior/GetEventStatus, operation=EvtInfo_AutoCreatedDemEvent_NVM_E_REQ_FAILED.GetEventStatus
        OpEventGetEventStatus_GetEventStatus_EvtInfo_AutoCreatedDemEvent_NVM_E_VERIFY_FAILED: start-on-event=DemSatellite_0InternalBehavior/GetEventStatus, operation=EvtInfo_AutoCreatedDemEvent_NVM_E_VERIFY_FAILED.GetEventStatus
        OpEventGetEventStatus_GetEventStatus_EvtInfo_AutoCreatedDemEvent_NVM_E_WRITE_PROTECTED: start-on-event=DemSatellite_0InternalBehavior/GetEventStatus, operation=EvtInfo_AutoCreatedDemEvent_NVM_E_WRITE_PROTECTED.GetEventStatus
        OpEventGetEventStatus_GetEventStatus_EvtInfo_AutoCreatedDemEvent_NVM_E_WRONG_BLOCK_ID: start-on-event=DemSatellite_0InternalBehavior/GetEventStatus, operation=EvtInfo_AutoCreatedDemEvent_NVM_E_WRONG_BLOCK_ID.GetEventStatus
        OpEventGetEventStatus_GetEventStatus_GeneralEventInfo: start-on-event=DemSatellite_0InternalBehavior/GetEventStatus, operation=GeneralEventInfo.GetEventStatus
        OpEventGetEventFailed_GetEventFailed_EvtInfo_AutoCreatedDemEvent_NVM_E_INTEGRITY_FAILED: start-on-event=DemSatellite_0InternalBehavior/GetEventFailed, operation=EvtInfo_AutoCreatedDemEvent_NVM_E_INTEGRITY_FAILED.GetEventFailed
        OpEventGetEventFailed_GetEventFailed_EvtInfo_AutoCreatedDemEvent_NVM_E_LOSS_OF_REDUNDANCY: start-on-event=DemSatellite_0InternalBehavior/GetEventFailed, operation=EvtInfo_AutoCreatedDemEvent_NVM_E_LOSS_OF_REDUNDANCY.GetEventFailed
        OpEventGetEventFailed_GetEventFailed_EvtInfo_AutoCreatedDemEvent_NVM_E_QUEUE_OVERFLOW: start-on-event=DemSatellite_0InternalBehavior/GetEventFailed, operation=EvtInfo_AutoCreatedDemEvent_NVM_E_QUEUE_OVERFLOW.GetEventFailed
        OpEventGetEventFailed_GetEventFailed_EvtInfo_AutoCreatedDemEvent_NVM_E_REQ_FAILED: start-on-event=DemSatellite_0InternalBehavior/GetEventFailed, operation=EvtInfo_AutoCreatedDemEvent_NVM_E_REQ_FAILED.GetEventFailed
        OpEventGetEventFailed_GetEventFailed_EvtInfo_AutoCreatedDemEvent_NVM_E_VERIFY_FAILED: start-on-event=DemSatellite_0InternalBehavior/GetEventFailed, operation=EvtInfo_AutoCreatedDemEvent_NVM_E_VERIFY_FAILED.GetEventFailed
        OpEventGetEventFailed_GetEventFailed_EvtInfo_AutoCreatedDemEvent_NVM_E_WRITE_PROTECTED: start-on-event=DemSatellite_0InternalBehavior/GetEventFailed, operation=EvtInfo_AutoCreatedDemEvent_NVM_E_WRITE_PROTECTED.GetEventFailed
        OpEventGetEventFailed_GetEventFailed_EvtInfo_AutoCreatedDemEvent_NVM_E_WRONG_BLOCK_ID: start-on-event=DemSatellite_0InternalBehavior/GetEventFailed, operation=EvtInfo_AutoCreatedDemEvent_NVM_E_WRONG_BLOCK_ID.GetEventFailed
        OpEventGetEventFailed_GetEventFailed_GeneralEventInfo: start-on-event=DemSatellite_0InternalBehavior/GetEventFailed, operation=GeneralEventInfo.GetEventFailed
        OpEventGetEventTested_GetEventTested_EvtInfo_AutoCreatedDemEvent_NVM_E_INTEGRITY_FAILED: start-on-event=DemSatellite_0InternalBehavior/GetEventTested, operation=EvtInfo_AutoCreatedDemEvent_NVM_E_INTEGRITY_FAILED.GetEventTested
        OpEventGetEventTested_GetEventTested_EvtInfo_AutoCreatedDemEvent_NVM_E_LOSS_OF_REDUNDANCY: start-on-event=DemSatellite_0InternalBehavior/GetEventTested, operation=EvtInfo_AutoCreatedDemEvent_NVM_E_LOSS_OF_REDUNDANCY.GetEventTested
        OpEventGetEventTested_GetEventTested_EvtInfo_AutoCreatedDemEvent_NVM_E_QUEUE_OVERFLOW: start-on-event=DemSatellite_0InternalBehavior/GetEventTested, operation=EvtInfo_AutoCreatedDemEvent_NVM_E_QUEUE_OVERFLOW.GetEventTested
        OpEventGetEventTested_GetEventTested_EvtInfo_AutoCreatedDemEvent_NVM_E_REQ_FAILED: start-on-event=DemSatellite_0InternalBehavior/GetEventTested, operation=EvtInfo_AutoCreatedDemEvent_NVM_E_REQ_FAILED.GetEventTested
        OpEventGetEventTested_GetEventTested_EvtInfo_AutoCreatedDemEvent_NVM_E_VERIFY_FAILED: start-on-event=DemSatellite_0InternalBehavior/GetEventTested, operation=EvtInfo_AutoCreatedDemEvent_NVM_E_VERIFY_FAILED.GetEventTested
        OpEventGetEventTested_GetEventTested_EvtInfo_AutoCreatedDemEvent_NVM_E_WRITE_PROTECTED: start-on-event=DemSatellite_0InternalBehavior/GetEventTested, operation=EvtInfo_AutoCreatedDemEvent_NVM_E_WRITE_PROTECTED.GetEventTested
        OpEventGetEventTested_GetEventTested_EvtInfo_AutoCreatedDemEvent_NVM_E_WRONG_BLOCK_ID: start-on-event=DemSatellite_0InternalBehavior/GetEventTested, operation=EvtInfo_AutoCreatedDemEvent_NVM_E_WRONG_BLOCK_ID.GetEventTested
        OpEventGetEventTested_GetEventTested_GeneralEventInfo: start-on-event=DemSatellite_0InternalBehavior/GetEventTested, operation=GeneralEventInfo.GetEventTested
        OpEventGetDTCOfEvent_GetDTCOfEvent_EvtInfo_AutoCreatedDemEvent_NVM_E_INTEGRITY_FAILED: start-on-event=DemSatellite_0InternalBehavior/GetDTCOfEvent, operation=EvtInfo_AutoCreatedDemEvent_NVM_E_INTEGRITY_FAILED.GetDTCOfEvent
        OpEventGetDTCOfEvent_GetDTCOfEvent_EvtInfo_AutoCreatedDemEvent_NVM_E_LOSS_OF_REDUNDANCY: start-on-event=DemSatellite_0InternalBehavior/GetDTCOfEvent, operation=EvtInfo_AutoCreatedDemEvent_NVM_E_LOSS_OF_REDUNDANCY.GetDTCOfEvent
        OpEventGetDTCOfEvent_GetDTCOfEvent_EvtInfo_AutoCreatedDemEvent_NVM_E_QUEUE_OVERFLOW: start-on-event=DemSatellite_0InternalBehavior/GetDTCOfEvent, operation=EvtInfo_AutoCreatedDemEvent_NVM_E_QUEUE_OVERFLOW.GetDTCOfEvent
        OpEventGetDTCOfEvent_GetDTCOfEvent_EvtInfo_AutoCreatedDemEvent_NVM_E_REQ_FAILED: start-on-event=DemSatellite_0InternalBehavior/GetDTCOfEvent, operation=EvtInfo_AutoCreatedDemEvent_NVM_E_REQ_FAILED.GetDTCOfEvent
        OpEventGetDTCOfEvent_GetDTCOfEvent_EvtInfo_AutoCreatedDemEvent_NVM_E_VERIFY_FAILED: start-on-event=DemSatellite_0InternalBehavior/GetDTCOfEvent, operation=EvtInfo_AutoCreatedDemEvent_NVM_E_VERIFY_FAILED.GetDTCOfEvent
        OpEventGetDTCOfEvent_GetDTCOfEvent_EvtInfo_AutoCreatedDemEvent_NVM_E_WRITE_PROTECTED: start-on-event=DemSatellite_0InternalBehavior/GetDTCOfEvent, operation=EvtInfo_AutoCreatedDemEvent_NVM_E_WRITE_PROTECTED.GetDTCOfEvent
        OpEventGetDTCOfEvent_GetDTCOfEvent_EvtInfo_AutoCreatedDemEvent_NVM_E_WRONG_BLOCK_ID: start-on-event=DemSatellite_0InternalBehavior/GetDTCOfEvent, operation=EvtInfo_AutoCreatedDemEvent_NVM_E_WRONG_BLOCK_ID.GetDTCOfEvent
        OpEventGetDTCOfEvent_GetDTCOfEvent_GeneralEventInfo: start-on-event=DemSatellite_0InternalBehavior/GetDTCOfEvent, operation=GeneralEventInfo.GetDTCOfEvent
        OpEventGetFaultDetectionCounter_GetFaultDetectionCounter_EvtInfo_AutoCreatedDemEvent_NVM_E_INTEGRITY_FAILED: start-on-event=DemSatellite_0InternalBehavior/GetFaultDetectionCounter, operation=EvtInfo_AutoCreatedDemEvent_NVM_E_INTEGRITY_FAILED.GetFaultDetectionCounter
        OpEventGetFaultDetectionCounter_GetFaultDetectionCounter_EvtInfo_AutoCreatedDemEvent_NVM_E_LOSS_OF_REDUNDANCY: start-on-event=DemSatellite_0InternalBehavior/GetFaultDetectionCounter, operation=EvtInfo_AutoCreatedDemEvent_NVM_E_LOSS_OF_REDUNDANCY.GetFaultDetectionCounter
        OpEventGetFaultDetectionCounter_GetFaultDetectionCounter_EvtInfo_AutoCreatedDemEvent_NVM_E_QUEUE_OVERFLOW: start-on-event=DemSatellite_0InternalBehavior/GetFaultDetectionCounter, operation=EvtInfo_AutoCreatedDemEvent_NVM_E_QUEUE_OVERFLOW.GetFaultDetectionCounter
        OpEventGetFaultDetectionCounter_GetFaultDetectionCounter_EvtInfo_AutoCreatedDemEvent_NVM_E_REQ_FAILED: start-on-event=DemSatellite_0InternalBehavior/GetFaultDetectionCounter, operation=EvtInfo_AutoCreatedDemEvent_NVM_E_REQ_FAILED.GetFaultDetectionCounter
        OpEventGetFaultDetectionCounter_GetFaultDetectionCounter_EvtInfo_AutoCreatedDemEvent_NVM_E_VERIFY_FAILED: start-on-event=DemSatellite_0InternalBehavior/GetFaultDetectionCounter, operation=EvtInfo_AutoCreatedDemEvent_NVM_E_VERIFY_FAILED.GetFaultDetectionCounter
        OpEventGetFaultDetectionCounter_GetFaultDetectionCounter_EvtInfo_AutoCreatedDemEvent_NVM_E_WRITE_PROTECTED: start-on-event=DemSatellite_0InternalBehavior/GetFaultDetectionCounter, operation=EvtInfo_AutoCreatedDemEvent_NVM_E_WRITE_PROTECTED.GetFaultDetectionCounter
        OpEventGetFaultDetectionCounter_GetFaultDetectionCounter_EvtInfo_AutoCreatedDemEvent_NVM_E_WRONG_BLOCK_ID: start-on-event=DemSatellite_0InternalBehavior/GetFaultDetectionCounter, operation=EvtInfo_AutoCreatedDemEvent_NVM_E_WRONG_BLOCK_ID.GetFaultDetectionCounter
        OpEventGetFaultDetectionCounter_GetFaultDetectionCounter_GeneralEventInfo: start-on-event=DemSatellite_0InternalBehavior/GetFaultDetectionCounter, operation=GeneralEventInfo.GetFaultDetectionCounter
        OpEventGetEventFreezeFrameDataEx_GetEventFreezeFrameDataEx_EvtInfo_AutoCreatedDemEvent_NVM_E_INTEGRITY_FAILED: start-on-event=DemSatellite_0InternalBehavior/GetEventFreezeFrameDataEx, operation=EvtInfo_AutoCreatedDemEvent_NVM_E_INTEGRITY_FAILED.GetEventFreezeFrameDataEx
        OpEventGetEventFreezeFrameDataEx_GetEventFreezeFrameDataEx_EvtInfo_AutoCreatedDemEvent_NVM_E_LOSS_OF_REDUNDANCY: start-on-event=DemSatellite_0InternalBehavior/GetEventFreezeFrameDataEx, operation=EvtInfo_AutoCreatedDemEvent_NVM_E_LOSS_OF_REDUNDANCY.GetEventFreezeFrameDataEx
        OpEventGetEventFreezeFrameDataEx_GetEventFreezeFrameDataEx_EvtInfo_AutoCreatedDemEvent_NVM_E_QUEUE_OVERFLOW: start-on-event=DemSatellite_0InternalBehavior/GetEventFreezeFrameDataEx, operation=EvtInfo_AutoCreatedDemEvent_NVM_E_QUEUE_OVERFLOW.GetEventFreezeFrameDataEx
        OpEventGetEventFreezeFrameDataEx_GetEventFreezeFrameDataEx_EvtInfo_AutoCreatedDemEvent_NVM_E_REQ_FAILED: start-on-event=DemSatellite_0InternalBehavior/GetEventFreezeFrameDataEx, operation=EvtInfo_AutoCreatedDemEvent_NVM_E_REQ_FAILED.GetEventFreezeFrameDataEx
        OpEventGetEventFreezeFrameDataEx_GetEventFreezeFrameDataEx_EvtInfo_AutoCreatedDemEvent_NVM_E_VERIFY_FAILED: start-on-event=DemSatellite_0InternalBehavior/GetEventFreezeFrameDataEx, operation=EvtInfo_AutoCreatedDemEvent_NVM_E_VERIFY_FAILED.GetEventFreezeFrameDataEx
        OpEventGetEventFreezeFrameDataEx_GetEventFreezeFrameDataEx_EvtInfo_AutoCreatedDemEvent_NVM_E_WRITE_PROTECTED: start-on-event=DemSatellite_0InternalBehavior/GetEventFreezeFrameDataEx, operation=EvtInfo_AutoCreatedDemEvent_NVM_E_WRITE_PROTECTED.GetEventFreezeFrameDataEx
        OpEventGetEventFreezeFrameDataEx_GetEventFreezeFrameDataEx_EvtInfo_AutoCreatedDemEvent_NVM_E_WRONG_BLOCK_ID: start-on-event=DemSatellite_0InternalBehavior/GetEventFreezeFrameDataEx, operation=EvtInfo_AutoCreatedDemEvent_NVM_E_WRONG_BLOCK_ID.GetEventFreezeFrameDataEx
        OpEventGetEventFreezeFrameDataEx_GetEventFreezeFrameDataEx_GeneralEventInfo: start-on-event=DemSatellite_0InternalBehavior/GetEventFreezeFrameDataEx, operation=GeneralEventInfo.GetEventFreezeFrameDataEx
        OpEventGetEventExtendedDataRecordEx_GetEventExtendedDataRecordEx_EvtInfo_AutoCreatedDemEvent_NVM_E_INTEGRITY_FAILED: start-on-event=DemSatellite_0InternalBehavior/GetEventExtendedDataRecordEx, operation=EvtInfo_AutoCreatedDemEvent_NVM_E_INTEGRITY_FAILED.GetEventExtendedDataRecordEx
        OpEventGetEventExtendedDataRecordEx_GetEventExtendedDataRecordEx_EvtInfo_AutoCreatedDemEvent_NVM_E_LOSS_OF_REDUNDANCY: start-on-event=DemSatellite_0InternalBehavior/GetEventExtendedDataRecordEx, operation=EvtInfo_AutoCreatedDemEvent_NVM_E_LOSS_OF_REDUNDANCY.GetEventExtendedDataRecordEx
        OpEventGetEventExtendedDataRecordEx_GetEventExtendedDataRecordEx_EvtInfo_AutoCreatedDemEvent_NVM_E_QUEUE_OVERFLOW: start-on-event=DemSatellite_0InternalBehavior/GetEventExtendedDataRecordEx, operation=EvtInfo_AutoCreatedDemEvent_NVM_E_QUEUE_OVERFLOW.GetEventExtendedDataRecordEx
        OpEventGetEventExtendedDataRecordEx_GetEventExtendedDataRecordEx_EvtInfo_AutoCreatedDemEvent_NVM_E_REQ_FAILED: start-on-event=DemSatellite_0InternalBehavior/GetEventExtendedDataRecordEx, operation=EvtInfo_AutoCreatedDemEvent_NVM_E_REQ_FAILED.GetEventExtendedDataRecordEx
        OpEventGetEventExtendedDataRecordEx_GetEventExtendedDataRecordEx_EvtInfo_AutoCreatedDemEvent_NVM_E_VERIFY_FAILED: start-on-event=DemSatellite_0InternalBehavior/GetEventExtendedDataRecordEx, operation=EvtInfo_AutoCreatedDemEvent_NVM_E_VERIFY_FAILED.GetEventExtendedDataRecordEx
        OpEventGetEventExtendedDataRecordEx_GetEventExtendedDataRecordEx_EvtInfo_AutoCreatedDemEvent_NVM_E_WRITE_PROTECTED: start-on-event=DemSatellite_0InternalBehavior/GetEventExtendedDataRecordEx, operation=EvtInfo_AutoCreatedDemEvent_NVM_E_WRITE_PROTECTED.GetEventExtendedDataRecordEx
        OpEventGetEventExtendedDataRecordEx_GetEventExtendedDataRecordEx_EvtInfo_AutoCreatedDemEvent_NVM_E_WRONG_BLOCK_ID: start-on-event=DemSatellite_0InternalBehavior/GetEventExtendedDataRecordEx, operation=EvtInfo_AutoCreatedDemEvent_NVM_E_WRONG_BLOCK_ID.GetEventExtendedDataRecordEx
        OpEventGetEventExtendedDataRecordEx_GetEventExtendedDataRecordEx_GeneralEventInfo: start-on-event=DemSatellite_0InternalBehavior/GetEventExtendedDataRecordEx, operation=GeneralEventInfo.GetEventExtendedDataRecordEx
        OpEventGetEventEnableCondition_GetEventEnableCondition_EvtInfo_AutoCreatedDemEvent_NVM_E_INTEGRITY_FAILED: start-on-event=DemSatellite_0InternalBehavior/GetEventEnableCondition, operation=EvtInfo_AutoCreatedDemEvent_NVM_E_INTEGRITY_FAILED.GetEventEnableCondition
        OpEventGetEventEnableCondition_GetEventEnableCondition_EvtInfo_AutoCreatedDemEvent_NVM_E_LOSS_OF_REDUNDANCY: start-on-event=DemSatellite_0InternalBehavior/GetEventEnableCondition, operation=EvtInfo_AutoCreatedDemEvent_NVM_E_LOSS_OF_REDUNDANCY.GetEventEnableCondition
        OpEventGetEventEnableCondition_GetEventEnableCondition_EvtInfo_AutoCreatedDemEvent_NVM_E_QUEUE_OVERFLOW: start-on-event=DemSatellite_0InternalBehavior/GetEventEnableCondition, operation=EvtInfo_AutoCreatedDemEvent_NVM_E_QUEUE_OVERFLOW.GetEventEnableCondition
        OpEventGetEventEnableCondition_GetEventEnableCondition_EvtInfo_AutoCreatedDemEvent_NVM_E_REQ_FAILED: start-on-event=DemSatellite_0InternalBehavior/GetEventEnableCondition, operation=EvtInfo_AutoCreatedDemEvent_NVM_E_REQ_FAILED.GetEventEnableCondition
        OpEventGetEventEnableCondition_GetEventEnableCondition_EvtInfo_AutoCreatedDemEvent_NVM_E_VERIFY_FAILED: start-on-event=DemSatellite_0InternalBehavior/GetEventEnableCondition, operation=EvtInfo_AutoCreatedDemEvent_NVM_E_VERIFY_FAILED.GetEventEnableCondition
        OpEventGetEventEnableCondition_GetEventEnableCondition_EvtInfo_AutoCreatedDemEvent_NVM_E_WRITE_PROTECTED: start-on-event=DemSatellite_0InternalBehavior/GetEventEnableCondition, operation=EvtInfo_AutoCreatedDemEvent_NVM_E_WRITE_PROTECTED.GetEventEnableCondition
        OpEventGetEventEnableCondition_GetEventEnableCondition_EvtInfo_AutoCreatedDemEvent_NVM_E_WRONG_BLOCK_ID: start-on-event=DemSatellite_0InternalBehavior/GetEventEnableCondition, operation=EvtInfo_AutoCreatedDemEvent_NVM_E_WRONG_BLOCK_ID.GetEventEnableCondition
        OpEventGetEventEnableCondition_GetEventEnableCondition_GeneralEventInfo: start-on-event=DemSatellite_0InternalBehavior/GetEventEnableCondition, operation=GeneralEventInfo.GetEventEnableCondition
        OpEventGetDebouncingOfEvent_GetDebouncingOfEvent_EvtInfo_AutoCreatedDemEvent_NVM_E_INTEGRITY_FAILED: start-on-event=DemSatellite_0InternalBehavior/GetDebouncingOfEvent, operation=EvtInfo_AutoCreatedDemEvent_NVM_E_INTEGRITY_FAILED.GetDebouncingOfEvent
        OpEventGetDebouncingOfEvent_GetDebouncingOfEvent_EvtInfo_AutoCreatedDemEvent_NVM_E_LOSS_OF_REDUNDANCY: start-on-event=DemSatellite_0InternalBehavior/GetDebouncingOfEvent, operation=EvtInfo_AutoCreatedDemEvent_NVM_E_LOSS_OF_REDUNDANCY.GetDebouncingOfEvent
        OpEventGetDebouncingOfEvent_GetDebouncingOfEvent_EvtInfo_AutoCreatedDemEvent_NVM_E_QUEUE_OVERFLOW: start-on-event=DemSatellite_0InternalBehavior/GetDebouncingOfEvent, operation=EvtInfo_AutoCreatedDemEvent_NVM_E_QUEUE_OVERFLOW.GetDebouncingOfEvent
        OpEventGetDebouncingOfEvent_GetDebouncingOfEvent_EvtInfo_AutoCreatedDemEvent_NVM_E_REQ_FAILED: start-on-event=DemSatellite_0InternalBehavior/GetDebouncingOfEvent, operation=EvtInfo_AutoCreatedDemEvent_NVM_E_REQ_FAILED.GetDebouncingOfEvent
        OpEventGetDebouncingOfEvent_GetDebouncingOfEvent_EvtInfo_AutoCreatedDemEvent_NVM_E_VERIFY_FAILED: start-on-event=DemSatellite_0InternalBehavior/GetDebouncingOfEvent, operation=EvtInfo_AutoCreatedDemEvent_NVM_E_VERIFY_FAILED.GetDebouncingOfEvent
        OpEventGetDebouncingOfEvent_GetDebouncingOfEvent_EvtInfo_AutoCreatedDemEvent_NVM_E_WRITE_PROTECTED: start-on-event=DemSatellite_0InternalBehavior/GetDebouncingOfEvent, operation=EvtInfo_AutoCreatedDemEvent_NVM_E_WRITE_PROTECTED.GetDebouncingOfEvent
        OpEventGetDebouncingOfEvent_GetDebouncingOfEvent_EvtInfo_AutoCreatedDemEvent_NVM_E_WRONG_BLOCK_ID: start-on-event=DemSatellite_0InternalBehavior/GetDebouncingOfEvent, operation=EvtInfo_AutoCreatedDemEvent_NVM_E_WRONG_BLOCK_ID.GetDebouncingOfEvent
        OpEventGetDebouncingOfEvent_GetDebouncingOfEvent_GeneralEventInfo: start-on-event=DemSatellite_0InternalBehavior/GetDebouncingOfEvent, operation=GeneralEventInfo.GetDebouncingOfEvent
        OpEventGetMonitorStatus_GetMonitorStatus_EvtInfo_AutoCreatedDemEvent_NVM_E_INTEGRITY_FAILED: start-on-event=DemSatellite_0InternalBehavior/GetMonitorStatus, operation=EvtInfo_AutoCreatedDemEvent_NVM_E_INTEGRITY_FAILED.GetMonitorStatus
        OpEventGetMonitorStatus_GetMonitorStatus_EvtInfo_AutoCreatedDemEvent_NVM_E_LOSS_OF_REDUNDANCY: start-on-event=DemSatellite_0InternalBehavior/GetMonitorStatus, operation=EvtInfo_AutoCreatedDemEvent_NVM_E_LOSS_OF_REDUNDANCY.GetMonitorStatus
        OpEventGetMonitorStatus_GetMonitorStatus_EvtInfo_AutoCreatedDemEvent_NVM_E_QUEUE_OVERFLOW: start-on-event=DemSatellite_0InternalBehavior/GetMonitorStatus, operation=EvtInfo_AutoCreatedDemEvent_NVM_E_QUEUE_OVERFLOW.GetMonitorStatus
        OpEventGetMonitorStatus_GetMonitorStatus_EvtInfo_AutoCreatedDemEvent_NVM_E_REQ_FAILED: start-on-event=DemSatellite_0InternalBehavior/GetMonitorStatus, operation=EvtInfo_AutoCreatedDemEvent_NVM_E_REQ_FAILED.GetMonitorStatus
        OpEventGetMonitorStatus_GetMonitorStatus_EvtInfo_AutoCreatedDemEvent_NVM_E_VERIFY_FAILED: start-on-event=DemSatellite_0InternalBehavior/GetMonitorStatus, operation=EvtInfo_AutoCreatedDemEvent_NVM_E_VERIFY_FAILED.GetMonitorStatus
        OpEventGetMonitorStatus_GetMonitorStatus_EvtInfo_AutoCreatedDemEvent_NVM_E_WRITE_PROTECTED: start-on-event=DemSatellite_0InternalBehavior/GetMonitorStatus, operation=EvtInfo_AutoCreatedDemEvent_NVM_E_WRITE_PROTECTED.GetMonitorStatus
        OpEventGetMonitorStatus_GetMonitorStatus_EvtInfo_AutoCreatedDemEvent_NVM_E_WRONG_BLOCK_ID: start-on-event=DemSatellite_0InternalBehavior/GetMonitorStatus, operation=EvtInfo_AutoCreatedDemEvent_NVM_E_WRONG_BLOCK_ID.GetMonitorStatus
        OpEventGetMonitorStatus_GetMonitorStatus_GeneralEventInfo: start-on-event=DemSatellite_0InternalBehavior/GetMonitorStatus, operation=GeneralEventInfo.GetMonitorStatus
        OpEventGetEventUdsStatus_GetEventUdsStatus_EvtInfo_AutoCreatedDemEvent_EcuMConfiguration_ECUM_E_ALL_RUN_REQUESTS_KILLED: start-on-event=DemSatellite_0InternalBehavior/GetEventUdsStatus, operation=EvtInfo_AutoCreatedDemEvent_EcuMConfiguration_ECUM_E_ALL_RUN_REQUESTS_KILLED.GetEventUdsStatus
        OpEventGetEventUdsStatus_GetEventUdsStatus_EvtInfo_AutoCreatedDemEvent_EcuMConfiguration_ECUM_E_CONFIGURATION_DATA_INCONSISTENT: start-on-event=DemSatellite_0InternalBehavior/GetEventUdsStatus, operation=EvtInfo_AutoCreatedDemEvent_EcuMConfiguration_ECUM_E_CONFIGURATION_DATA_INCONSISTENT.GetEventUdsStatus
        OpEventGetEventUdsStatus_GetEventUdsStatus_EvtInfo_AutoCreatedDemEvent_EcuMConfiguration_ECUM_E_RAM_CHECK_FAILED: start-on-event=DemSatellite_0InternalBehavior/GetEventUdsStatus, operation=EvtInfo_AutoCreatedDemEvent_EcuMConfiguration_ECUM_E_RAM_CHECK_FAILED.GetEventUdsStatus
        OpEventGetEventUdsStatus_GetEventUdsStatus_EvtInfo_AutoCreatedDemEvent_EcuMConfiguration_ECUM_E_IMPROPER_CALLER: start-on-event=DemSatellite_0InternalBehavior/GetEventUdsStatus, operation=EvtInfo_AutoCreatedDemEvent_EcuMConfiguration_ECUM_E_IMPROPER_CALLER.GetEventUdsStatus
        OpEventGetEventStatus_GetEventStatus_EvtInfo_AutoCreatedDemEvent_EcuMConfiguration_ECUM_E_ALL_RUN_REQUESTS_KILLED: start-on-event=DemSatellite_0InternalBehavior/GetEventStatus, operation=EvtInfo_AutoCreatedDemEvent_EcuMConfiguration_ECUM_E_ALL_RUN_REQUESTS_KILLED.GetEventStatus
        OpEventGetEventStatus_GetEventStatus_EvtInfo_AutoCreatedDemEvent_EcuMConfiguration_ECUM_E_CONFIGURATION_DATA_INCONSISTENT: start-on-event=DemSatellite_0InternalBehavior/GetEventStatus, operation=EvtInfo_AutoCreatedDemEvent_EcuMConfiguration_ECUM_E_CONFIGURATION_DATA_INCONSISTENT.GetEventStatus
        OpEventGetEventStatus_GetEventStatus_EvtInfo_AutoCreatedDemEvent_EcuMConfiguration_ECUM_E_RAM_CHECK_FAILED: start-on-event=DemSatellite_0InternalBehavior/GetEventStatus, operation=EvtInfo_AutoCreatedDemEvent_EcuMConfiguration_ECUM_E_RAM_CHECK_FAILED.GetEventStatus
        OpEventGetEventStatus_GetEventStatus_EvtInfo_AutoCreatedDemEvent_EcuMConfiguration_ECUM_E_IMPROPER_CALLER: start-on-event=DemSatellite_0InternalBehavior/GetEventStatus, operation=EvtInfo_AutoCreatedDemEvent_EcuMConfiguration_ECUM_E_IMPROPER_CALLER.GetEventStatus
        OpEventGetEventFailed_GetEventFailed_EvtInfo_AutoCreatedDemEvent_EcuMConfiguration_ECUM_E_ALL_RUN_REQUESTS_KILLED: start-on-event=DemSatellite_0InternalBehavior/GetEventFailed, operation=EvtInfo_AutoCreatedDemEvent_EcuMConfiguration_ECUM_E_ALL_RUN_REQUESTS_KILLED.GetEventFailed
        OpEventGetEventFailed_GetEventFailed_EvtInfo_AutoCreatedDemEvent_EcuMConfiguration_ECUM_E_CONFIGURATION_DATA_INCONSISTENT: start-on-event=DemSatellite_0InternalBehavior/GetEventFailed, operation=EvtInfo_AutoCreatedDemEvent_EcuMConfiguration_ECUM_E_CONFIGURATION_DATA_INCONSISTENT.GetEventFailed
        OpEventGetEventFailed_GetEventFailed_EvtInfo_AutoCreatedDemEvent_EcuMConfiguration_ECUM_E_RAM_CHECK_FAILED: start-on-event=DemSatellite_0InternalBehavior/GetEventFailed, operation=EvtInfo_AutoCreatedDemEvent_EcuMConfiguration_ECUM_E_RAM_CHECK_FAILED.GetEventFailed
        OpEventGetEventFailed_GetEventFailed_EvtInfo_AutoCreatedDemEvent_EcuMConfiguration_ECUM_E_IMPROPER_CALLER: start-on-event=DemSatellite_0InternalBehavior/GetEventFailed, operation=EvtInfo_AutoCreatedDemEvent_EcuMConfiguration_ECUM_E_IMPROPER_CALLER.GetEventFailed
        OpEventGetEventTested_GetEventTested_EvtInfo_AutoCreatedDemEvent_EcuMConfiguration_ECUM_E_ALL_RUN_REQUESTS_KILLED: start-on-event=DemSatellite_0InternalBehavior/GetEventTested, operation=EvtInfo_AutoCreatedDemEvent_EcuMConfiguration_ECUM_E_ALL_RUN_REQUESTS_KILLED.GetEventTested
        OpEventGetEventTested_GetEventTested_EvtInfo_AutoCreatedDemEvent_EcuMConfiguration_ECUM_E_CONFIGURATION_DATA_INCONSISTENT: start-on-event=DemSatellite_0InternalBehavior/GetEventTested, operation=EvtInfo_AutoCreatedDemEvent_EcuMConfiguration_ECUM_E_CONFIGURATION_DATA_INCONSISTENT.GetEventTested
        OpEventGetEventTested_GetEventTested_EvtInfo_AutoCreatedDemEvent_EcuMConfiguration_ECUM_E_RAM_CHECK_FAILED: start-on-event=DemSatellite_0InternalBehavior/GetEventTested, operation=EvtInfo_AutoCreatedDemEvent_EcuMConfiguration_ECUM_E_RAM_CHECK_FAILED.GetEventTested
        OpEventGetEventTested_GetEventTested_EvtInfo_AutoCreatedDemEvent_EcuMConfiguration_ECUM_E_IMPROPER_CALLER: start-on-event=DemSatellite_0InternalBehavior/GetEventTested, operation=EvtInfo_AutoCreatedDemEvent_EcuMConfiguration_ECUM_E_IMPROPER_CALLER.GetEventTested
        OpEventGetDTCOfEvent_GetDTCOfEvent_EvtInfo_AutoCreatedDemEvent_EcuMConfiguration_ECUM_E_ALL_RUN_REQUESTS_KILLED: start-on-event=DemSatellite_0InternalBehavior/GetDTCOfEvent, operation=EvtInfo_AutoCreatedDemEvent_EcuMConfiguration_ECUM_E_ALL_RUN_REQUESTS_KILLED.GetDTCOfEvent
        OpEventGetDTCOfEvent_GetDTCOfEvent_EvtInfo_AutoCreatedDemEvent_EcuMConfiguration_ECUM_E_CONFIGURATION_DATA_INCONSISTENT: start-on-event=DemSatellite_0InternalBehavior/GetDTCOfEvent, operation=EvtInfo_AutoCreatedDemEvent_EcuMConfiguration_ECUM_E_CONFIGURATION_DATA_INCONSISTENT.GetDTCOfEvent
        OpEventGetDTCOfEvent_GetDTCOfEvent_EvtInfo_AutoCreatedDemEvent_EcuMConfiguration_ECUM_E_RAM_CHECK_FAILED: start-on-event=DemSatellite_0InternalBehavior/GetDTCOfEvent, operation=EvtInfo_AutoCreatedDemEvent_EcuMConfiguration_ECUM_E_RAM_CHECK_FAILED.GetDTCOfEvent
        OpEventGetDTCOfEvent_GetDTCOfEvent_EvtInfo_AutoCreatedDemEvent_EcuMConfiguration_ECUM_E_IMPROPER_CALLER: start-on-event=DemSatellite_0InternalBehavior/GetDTCOfEvent, operation=EvtInfo_AutoCreatedDemEvent_EcuMConfiguration_ECUM_E_IMPROPER_CALLER.GetDTCOfEvent
        OpEventGetFaultDetectionCounter_GetFaultDetectionCounter_EvtInfo_AutoCreatedDemEvent_EcuMConfiguration_ECUM_E_ALL_RUN_R_5c1d7bad: start-on-event=DemSatellite_0InternalBehavior/GetFaultDetectionCounter, operation=EvtInfo_AutoCreatedDemEvent_EcuMConfiguration_ECUM_E_ALL_RUN_REQUESTS_KILLED.GetFaultDetectionCounter
        OpEventGetFaultDetectionCounter_GetFaultDetectionCounter_EvtInfo_AutoCreatedDemEvent_EcuMConfiguration_ECUM_E_CONFIGURA_55d3b4f6: start-on-event=DemSatellite_0InternalBehavior/GetFaultDetectionCounter, operation=EvtInfo_AutoCreatedDemEvent_EcuMConfiguration_ECUM_E_CONFIGURATION_DATA_INCONSISTENT.GetFaultDetectionCounter
        OpEventGetFaultDetectionCounter_GetFaultDetectionCounter_EvtInfo_AutoCreatedDemEvent_EcuMConfiguration_ECUM_E_RAM_CHECK_FAILED: start-on-event=DemSatellite_0InternalBehavior/GetFaultDetectionCounter, operation=EvtInfo_AutoCreatedDemEvent_EcuMConfiguration_ECUM_E_RAM_CHECK_FAILED.GetFaultDetectionCounter
        OpEventGetFaultDetectionCounter_GetFaultDetectionCounter_EvtInfo_AutoCreatedDemEvent_EcuMConfiguration_ECUM_E_IMPROPER_CALLER: start-on-event=DemSatellite_0InternalBehavior/GetFaultDetectionCounter, operation=EvtInfo_AutoCreatedDemEvent_EcuMConfiguration_ECUM_E_IMPROPER_CALLER.GetFaultDetectionCounter
        OpEventGetEventFreezeFrameDataEx_GetEventFreezeFrameDataEx_EvtInfo_AutoCreatedDemEvent_EcuMConfiguration_ECUM_E_ALL_RUN_993f76de: start-on-event=DemSatellite_0InternalBehavior/GetEventFreezeFrameDataEx, operation=EvtInfo_AutoCreatedDemEvent_EcuMConfiguration_ECUM_E_ALL_RUN_REQUESTS_KILLED.GetEventFreezeFrameDataEx
        OpEventGetEventFreezeFrameDataEx_GetEventFreezeFrameDataEx_EvtInfo_AutoCreatedDemEvent_EcuMConfiguration_ECUM_E_CONFIGU_7d4a80d3: start-on-event=DemSatellite_0InternalBehavior/GetEventFreezeFrameDataEx, operation=EvtInfo_AutoCreatedDemEvent_EcuMConfiguration_ECUM_E_CONFIGURATION_DATA_INCONSISTENT.GetEventFreezeFrameDataEx
        OpEventGetEventFreezeFrameDataEx_GetEventFreezeFrameDataEx_EvtInfo_AutoCreatedDemEvent_EcuMConfiguration_ECUM_E_RAM_CHECK_FAILED: start-on-event=DemSatellite_0InternalBehavior/GetEventFreezeFrameDataEx, operation=EvtInfo_AutoCreatedDemEvent_EcuMConfiguration_ECUM_E_RAM_CHECK_FAILED.GetEventFreezeFrameDataEx
        OpEventGetEventFreezeFrameDataEx_GetEventFreezeFrameDataEx_EvtInfo_AutoCreatedDemEvent_EcuMConfiguration_ECUM_E_IMPROPER_CALLER: start-on-event=DemSatellite_0InternalBehavior/GetEventFreezeFrameDataEx, operation=EvtInfo_AutoCreatedDemEvent_EcuMConfiguration_ECUM_E_IMPROPER_CALLER.GetEventFreezeFrameDataEx
        OpEventGetEventExtendedDataRecordEx_GetEventExtendedDataRecordEx_EvtInfo_AutoCreatedDemEvent_EcuMConfiguration_ECUM_E_A_6cc04a27: start-on-event=DemSatellite_0InternalBehavior/GetEventExtendedDataRecordEx, operation=EvtInfo_AutoCreatedDemEvent_EcuMConfiguration_ECUM_E_ALL_RUN_REQUESTS_KILLED.GetEventExtendedDataRecordEx
        OpEventGetEventExtendedDataRecordEx_GetEventExtendedDataRecordEx_EvtInfo_AutoCreatedDemEvent_EcuMConfiguration_ECUM_E_C_96bd3475: start-on-event=DemSatellite_0InternalBehavior/GetEventExtendedDataRecordEx, operation=EvtInfo_AutoCreatedDemEvent_EcuMConfiguration_ECUM_E_CONFIGURATION_DATA_INCONSISTENT.GetEventExtendedDataRecordEx
        OpEventGetEventExtendedDataRecordEx_GetEventExtendedDataRecordEx_EvtInfo_AutoCreatedDemEvent_EcuMConfiguration_ECUM_E_R_25bd882a: start-on-event=DemSatellite_0InternalBehavior/GetEventExtendedDataRecordEx, operation=EvtInfo_AutoCreatedDemEvent_EcuMConfiguration_ECUM_E_RAM_CHECK_FAILED.GetEventExtendedDataRecordEx
        OpEventGetEventExtendedDataRecordEx_GetEventExtendedDataRecordEx_EvtInfo_AutoCreatedDemEvent_EcuMConfiguration_ECUM_E_I_7db075fd: start-on-event=DemSatellite_0InternalBehavior/GetEventExtendedDataRecordEx, operation=EvtInfo_AutoCreatedDemEvent_EcuMConfiguration_ECUM_E_IMPROPER_CALLER.GetEventExtendedDataRecordEx
        OpEventGetEventEnableCondition_GetEventEnableCondition_EvtInfo_AutoCreatedDemEvent_EcuMConfiguration_ECUM_E_ALL_RUN_REQ_5b1f807c: start-on-event=DemSatellite_0InternalBehavior/GetEventEnableCondition, operation=EvtInfo_AutoCreatedDemEvent_EcuMConfiguration_ECUM_E_ALL_RUN_REQUESTS_KILLED.GetEventEnableCondition
        OpEventGetEventEnableCondition_GetEventEnableCondition_EvtInfo_AutoCreatedDemEvent_EcuMConfiguration_ECUM_E_CONFIGURATI_06f5d14c: start-on-event=DemSatellite_0InternalBehavior/GetEventEnableCondition, operation=EvtInfo_AutoCreatedDemEvent_EcuMConfiguration_ECUM_E_CONFIGURATION_DATA_INCONSISTENT.GetEventEnableCondition
        OpEventGetEventEnableCondition_GetEventEnableCondition_EvtInfo_AutoCreatedDemEvent_EcuMConfiguration_ECUM_E_RAM_CHECK_FAILED: start-on-event=DemSatellite_0InternalBehavior/GetEventEnableCondition, operation=EvtInfo_AutoCreatedDemEvent_EcuMConfiguration_ECUM_E_RAM_CHECK_FAILED.GetEventEnableCondition
        OpEventGetEventEnableCondition_GetEventEnableCondition_EvtInfo_AutoCreatedDemEvent_EcuMConfiguration_ECUM_E_IMPROPER_CALLER: start-on-event=DemSatellite_0InternalBehavior/GetEventEnableCondition, operation=EvtInfo_AutoCreatedDemEvent_EcuMConfiguration_ECUM_E_IMPROPER_CALLER.GetEventEnableCondition
        OpEventGetDebouncingOfEvent_GetDebouncingOfEvent_EvtInfo_AutoCreatedDemEvent_EcuMConfiguration_ECUM_E_ALL_RUN_REQUESTS_KILLED: start-on-event=DemSatellite_0InternalBehavior/GetDebouncingOfEvent, operation=EvtInfo_AutoCreatedDemEvent_EcuMConfiguration_ECUM_E_ALL_RUN_REQUESTS_KILLED.GetDebouncingOfEvent
        OpEventGetDebouncingOfEvent_GetDebouncingOfEvent_EvtInfo_AutoCreatedDemEvent_EcuMConfiguration_ECUM_E_CONFIGURATION_DAT_7642b2c3: start-on-event=DemSatellite_0InternalBehavior/GetDebouncingOfEvent, operation=EvtInfo_AutoCreatedDemEvent_EcuMConfiguration_ECUM_E_CONFIGURATION_DATA_INCONSISTENT.GetDebouncingOfEvent
        OpEventGetDebouncingOfEvent_GetDebouncingOfEvent_EvtInfo_AutoCreatedDemEvent_EcuMConfiguration_ECUM_E_RAM_CHECK_FAILED: start-on-event=DemSatellite_0InternalBehavior/GetDebouncingOfEvent, operation=EvtInfo_AutoCreatedDemEvent_EcuMConfiguration_ECUM_E_RAM_CHECK_FAILED.GetDebouncingOfEvent
        OpEventGetDebouncingOfEvent_GetDebouncingOfEvent_EvtInfo_AutoCreatedDemEvent_EcuMConfiguration_ECUM_E_IMPROPER_CALLER: start-on-event=DemSatellite_0InternalBehavior/GetDebouncingOfEvent, operation=EvtInfo_AutoCreatedDemEvent_EcuMConfiguration_ECUM_E_IMPROPER_CALLER.GetDebouncingOfEvent
        OpEventGetMonitorStatus_GetMonitorStatus_EvtInfo_AutoCreatedDemEvent_EcuMConfiguration_ECUM_E_ALL_RUN_REQUESTS_KILLED: start-on-event=DemSatellite_0InternalBehavior/GetMonitorStatus, operation=EvtInfo_AutoCreatedDemEvent_EcuMConfiguration_ECUM_E_ALL_RUN_REQUESTS_KILLED.GetMonitorStatus
        OpEventGetMonitorStatus_GetMonitorStatus_EvtInfo_AutoCreatedDemEvent_EcuMConfiguration_ECUM_E_CONFIGURATION_DATA_INCONSISTENT: start-on-event=DemSatellite_0InternalBehavior/GetMonitorStatus, operation=EvtInfo_AutoCreatedDemEvent_EcuMConfiguration_ECUM_E_CONFIGURATION_DATA_INCONSISTENT.GetMonitorStatus
        OpEventGetMonitorStatus_GetMonitorStatus_EvtInfo_AutoCreatedDemEvent_EcuMConfiguration_ECUM_E_RAM_CHECK_FAILED: start-on-event=DemSatellite_0InternalBehavior/GetMonitorStatus, operation=EvtInfo_AutoCreatedDemEvent_EcuMConfiguration_ECUM_E_RAM_CHECK_FAILED.GetMonitorStatus
        OpEventGetMonitorStatus_GetMonitorStatus_EvtInfo_AutoCreatedDemEvent_EcuMConfiguration_ECUM_E_IMPROPER_CALLER: start-on-event=DemSatellite_0InternalBehavior/GetMonitorStatus, operation=EvtInfo_AutoCreatedDemEvent_EcuMConfiguration_ECUM_E_IMPROPER_CALLER.GetMonitorStatus
        OpEventGetEventUdsStatus_GetEventUdsStatus_EvtInfo_DTC_0x000002: start-on-event=DemSatellite_0InternalBehavior/GetEventUdsStatus, operation=EvtInfo_DTC_0x000002.GetEventUdsStatus
        OpEventGetEventUdsStatus_GetEventUdsStatus_Event_DTC_0x000002: start-on-event=DemSatellite_0InternalBehavior/GetEventUdsStatus, operation=Event_DTC_0x000002.GetEventUdsStatus
        OpEventGetEventStatus_GetEventStatus_EvtInfo_DTC_0x000002: start-on-event=DemSatellite_0InternalBehavior/GetEventStatus, operation=EvtInfo_DTC_0x000002.GetEventStatus
        OpEventGetEventStatus_GetEventStatus_Event_DTC_0x000002: start-on-event=DemSatellite_0InternalBehavior/GetEventStatus, operation=Event_DTC_0x000002.GetEventStatus
        OpEventGetEventFailed_GetEventFailed_EvtInfo_DTC_0x000002: start-on-event=DemSatellite_0InternalBehavior/GetEventFailed, operation=EvtInfo_DTC_0x000002.GetEventFailed
        OpEventGetEventFailed_GetEventFailed_Event_DTC_0x000002: start-on-event=DemSatellite_0InternalBehavior/GetEventFailed, operation=Event_DTC_0x000002.GetEventFailed
        OpEventGetEventTested_GetEventTested_EvtInfo_DTC_0x000002: start-on-event=DemSatellite_0InternalBehavior/GetEventTested, operation=EvtInfo_DTC_0x000002.GetEventTested
        OpEventGetEventTested_GetEventTested_Event_DTC_0x000002: start-on-event=DemSatellite_0InternalBehavior/GetEventTested, operation=Event_DTC_0x000002.GetEventTested
        OpEventGetDTCOfEvent_GetDTCOfEvent_EvtInfo_DTC_0x000002: start-on-event=DemSatellite_0InternalBehavior/GetDTCOfEvent, operation=EvtInfo_DTC_0x000002.GetDTCOfEvent
        OpEventGetDTCOfEvent_GetDTCOfEvent_Event_DTC_0x000002: start-on-event=DemSatellite_0InternalBehavior/GetDTCOfEvent, operation=Event_DTC_0x000002.GetDTCOfEvent
        OpEventGetFaultDetectionCounter_GetFaultDetectionCounter_EvtInfo_DTC_0x000002: start-on-event=DemSatellite_0InternalBehavior/GetFaultDetectionCounter, operation=EvtInfo_DTC_0x000002.GetFaultDetectionCounter
        OpEventGetFaultDetectionCounter_GetFaultDetectionCounter_Event_DTC_0x000002: start-on-event=DemSatellite_0InternalBehavior/GetFaultDetectionCounter, operation=Event_DTC_0x000002.GetFaultDetectionCounter
        OpEventGetEventFreezeFrameDataEx_GetEventFreezeFrameDataEx_EvtInfo_DTC_0x000002: start-on-event=DemSatellite_0InternalBehavior/GetEventFreezeFrameDataEx, operation=EvtInfo_DTC_0x000002.GetEventFreezeFrameDataEx
        OpEventGetEventFreezeFrameDataEx_GetEventFreezeFrameDataEx_Event_DTC_0x000002: start-on-event=DemSatellite_0InternalBehavior/GetEventFreezeFrameDataEx, operation=Event_DTC_0x000002.GetEventFreezeFrameDataEx
        OpEventGetEventExtendedDataRecordEx_GetEventExtendedDataRecordEx_EvtInfo_DTC_0x000002: start-on-event=DemSatellite_0InternalBehavior/GetEventExtendedDataRecordEx, operation=EvtInfo_DTC_0x000002.GetEventExtendedDataRecordEx
        OpEventGetEventExtendedDataRecordEx_GetEventExtendedDataRecordEx_Event_DTC_0x000002: start-on-event=DemSatellite_0InternalBehavior/GetEventExtendedDataRecordEx, operation=Event_DTC_0x000002.GetEventExtendedDataRecordEx
        OpEventGetEventEnableCondition_GetEventEnableCondition_EvtInfo_DTC_0x000002: start-on-event=DemSatellite_0InternalBehavior/GetEventEnableCondition, operation=EvtInfo_DTC_0x000002.GetEventEnableCondition
        OpEventGetDebouncingOfEvent_GetDebouncingOfEvent_EvtInfo_DTC_0x000002: start-on-event=DemSatellite_0InternalBehavior/GetDebouncingOfEvent, operation=EvtInfo_DTC_0x000002.GetDebouncingOfEvent
        OpEventGetMonitorStatus_GetMonitorStatus_EvtInfo_DTC_0x000002: start-on-event=DemSatellite_0InternalBehavior/GetMonitorStatus, operation=EvtInfo_DTC_0x000002.GetMonitorStatus
        OpEventSetEventStatus_SetEventStatus_Event_DTC_0x000002: start-on-event=SetEventStatus, operation=Event_DTC_0x000002.SetEventStatus
        OpEventResetEventStatus_ResetEventStatus_Event_DTC_0x000002: start-on-event=ResetEventStatus, operation=Event_DTC_0x000002.ResetEventStatus
        OpEventResetEventDebounceStatus_ResetEventDebounceStatus_Event_DTC_0x000002: start-on-event=ResetEventDebounceStatus, operation=Event_DTC_0x000002.ResetEventDebounceStatus
      port-api-options:
        {enable-take-address=true, indirect-api=false, port-defined-argument-value{value=1, value-type=Dem_EventIdType}, port=EvtInfo_AutoCreatedDemEvent_NVM_E_INTEGRITY_FAILED}
        {enable-take-address=true, indirect-api=false, port-defined-argument-value{value=2, value-type=Dem_EventIdType}, port=EvtInfo_AutoCreatedDemEvent_NVM_E_LOSS_OF_REDUNDANCY}
        {enable-take-address=true, indirect-api=false, port-defined-argument-value{value=3, value-type=Dem_EventIdType}, port=EvtInfo_AutoCreatedDemEvent_NVM_E_QUEUE_OVERFLOW}
        {enable-take-address=true, indirect-api=false, port-defined-argument-value{value=4, value-type=Dem_EventIdType}, port=EvtInfo_AutoCreatedDemEvent_NVM_E_REQ_FAILED}
        {enable-take-address=true, indirect-api=false, port-defined-argument-value{value=5, value-type=Dem_EventIdType}, port=EvtInfo_AutoCreatedDemEvent_NVM_E_VERIFY_FAILED}
        {enable-take-address=true, indirect-api=false, port-defined-argument-value{value=6, value-type=Dem_EventIdType}, port=EvtInfo_AutoCreatedDemEvent_NVM_E_WRITE_PROTECTED}
        {enable-take-address=true, indirect-api=false, port-defined-argument-value{value=7, value-type=Dem_EventIdType}, port=EvtInfo_AutoCreatedDemEvent_NVM_E_WRONG_BLOCK_ID}
        enable-take-address=true, indirect-api=false, port=DemSatellite_0/GeneralEventInfo
        {enable-take-address=true, indirect-api=false, port-defined-argument-value{value=8, value-type=Dem_EventIdType}, port=EvtInfo_AutoCreatedDemEvent_EcuMConfiguration_ECUM_E_ALL_RUN_REQUESTS_KILLED}
        {enable-take-address=true, indirect-api=false, port-defined-argument-value{value=9, value-type=Dem_EventIdType}, port=EvtInfo_AutoCreatedDemEvent_EcuMConfiguration_ECUM_E_CONFIGURATION_DATA_INCONSISTENT}
        {enable-take-address=true, indirect-api=false, port-defined-argument-value{value=11, value-type=Dem_EventIdType}, port=EvtInfo_AutoCreatedDemEvent_EcuMConfiguration_ECUM_E_RAM_CHECK_FAILED}
        {enable-take-address=true, indirect-api=false, port-defined-argument-value{value=10, value-type=Dem_EventIdType}, port=EvtInfo_AutoCreatedDemEvent_EcuMConfiguration_ECUM_E_IMPROPER_CALLER}
        {enable-take-address=true, indirect-api=false, port-defined-argument-value{value=12, value-type=Dem_EventIdType}, port=EvtInfo_DTC_0x000002}
        {enable-take-address=true, indirect-api=false, port-defined-argument-value{value=12, value-type=Dem_EventIdType}, port=Event_DTC_0x000002}
      15 x runnable:
        Dem_SatelliteMainFunction
        GetEventUdsStatus: can-be-invoked-concurrently=true, symbol=Dem_GetEventUdsStatus
        GetEventStatus: can-be-invoked-concurrently=true, symbol=Dem_GetEventUdsStatus
        GetEventFailed: can-be-invoked-concurrently=true, symbol=Dem_GetEventFailed
        GetEventTested: can-be-invoked-concurrently=true, symbol=Dem_GetEventTested
        GetDTCOfEvent: can-be-invoked-concurrently=true, symbol=Dem_GetDTCOfEvent
        GetFaultDetectionCounter: can-be-invoked-concurrently=true, symbol=Dem_GetFaultDetectionCounter
        GetEventFreezeFrameDataEx: can-be-invoked-concurrently=true, symbol=Dem_GetEventFreezeFrameDataEx
        GetEventExtendedDataRecordEx: can-be-invoked-concurrently=true, symbol=Dem_GetEventExtendedDataRecordEx
        GetEventEnableCondition: can-be-invoked-concurrently=true, symbol=Dem_GetEventEnableCondition
        GetDebouncingOfEvent: can-be-invoked-concurrently=true, symbol=Dem_GetDebouncingOfEvent
        GetMonitorStatus: can-be-invoked-concurrently=true, symbol=Dem_GetMonitorStatus
        SetEventStatus: can-be-invoked-concurrently=true, symbol=Dem_SetEventStatus
        ResetEventStatus: can-be-invoked-concurrently=true, symbol=Dem_ResetEventStatus
        ResetEventDebounceStatus: can-be-invoked-concurrently=true, symbol=Dem_ResetEventDebounceStatus
  swc implementation DemSatellite_0Implementation: programming-language=C, behavior=DemSatellite_0InternalBehavior
package /MICROSAR/Det_swc/Interfaces
  client server interface DETServiceLegacy: is-service=true, service-kind=DEVELOPMENT-ERROR-TRACER
    operation ReportError: possible-error=DETServiceLegacy/E_OK
      arg InstanceId: type=ImplementationDataTypes/uint8, direction=IN
      arg ApiId: type=ImplementationDataTypes/uint8, direction=IN
      arg ErrorId: type=ImplementationDataTypes/uint8, direction=IN
    error E_OK: error-code=0
  client server interface DETService: is-service=true, service-kind=DEVELOPMENT-ERROR-TRACER
    operation ReportError: possible-error=DETService/E_OK
      arg ApiId: type=ImplementationDataTypes/uint8, direction=IN
      arg ErrorId: type=ImplementationDataTypes/uint8, direction=IN
    operation ReportRuntimeError: possible-error=DETService/E_OK
      arg ApiId: type=ImplementationDataTypes/uint8, direction=IN
      arg ErrorId: type=ImplementationDataTypes/uint8, direction=IN
    error E_OK: error-code=0
package /MICROSAR/Det_swc/ComponentTypes
  service sw component type Det: category=SERVICE_COMPONENT
    behavior DetInternalBehavior: handle-termination-and-restart=NO-SUPPORT
  swc implementation DetImplementation: programming-language=C, behavior=DetInternalBehavior
package /MICROSAR/EcuM_swc/DataTypes
  6 x impl type, all with category=TYPE_REFERENCE:
    EcuM_StateType: compu {80=ECUM_STATE_SLEEP, 128=ECUM_STATE_OFF, 144=ECUM_STATE_RESET}, implementation-data-type=ImplementationDataTypes/uint8
    EcuM_TimeType: range raw 0..4294967295, implementation-data-type=ImplementationDataTypes/uint32
    EcuM_ShutdownCauseType: compu {0=EcuMConf_EcuMShutdownCause_ECUM_CAUSE_UNKNOWN, 3=EcuMConf_EcuMShutdownCause_ECUM_CAUSE_DCM, 1=EcuMConf_EcuMShutdownCause_ECUM_CAUSE_ECU_STATE, 2=EcuMConf_EcuMShutdownCause_ECUM_CAUSE_WDGM}, implementation-data-type=ImplementationDataTypes/uint8  # This type describes the cause for a shutdown by the ECU State Manager. It can be extended by configuration.
    EcuM_BootTargetType: compu {0=ECUM_BOOT_TARGET_APP, 1=ECUM_BOOT_TARGET_OEM_BOOTLOADER, 2=ECUM_BOOT_TARGET_SYS_BOOTLOADER}, implementation-data-type=ImplementationDataTypes/uint8  # This type represents the boot targets the ECU Manager module can be configured with. The default boot target is ECUM_BOOT_TARGET_OEM_BOOTLOADER.
    EcuM_ModeType: compu {1=EcuMConf_EcuMResetMode_ECUM_RESET_WDG, 2=EcuMConf_EcuMResetMode_ECUM_RESET_IO, 0=EcuMConf_EcuMResetMode_ECUM_RESET_MCU, 3=EcuMConf_EcuMResetMode_ECUM_RESET_WAKEUP, 0=EcuMConf_EcuMSleepMode_EcuMSleepMode}, implementation-data-type=ImplementationDataTypes/uint8  # ECU State Manager states.
    EcuM_UserType: compu {0=EcuMConf_EcuMFlexUserConfig_EcuMFlexUserConfig}, implementation-data-type=ImplementationDataTypes/uint8  # Unique value for each user
package /MICROSAR/EcuM_swc/Interfaces
  client server interface EcuM_ShutdownTarget: is-service=true, service-kind=ECU-MANAGER  # A SW-C can select a shutdown target using this interface.
    5 x operation, all with possible-error=EcuM_ShutdownTarget/E_NOT_OK:
      SelectShutdownTarget  # The SW-C selects the cause corresponding to the next shutdown target.
        arg targetState: type=EcuM_StateType, direction=IN  # The selected shutdown cause.
        arg resetSleepMode: type=EcuM_ModeType, direction=IN  # The sleep mode (if target is ECUM_STATE_SLEEP) or the reset mechanism (if target is ECUM_STATE_RESET) of the shutdown.
      GetShutdownTarget  # Returns the currently selected shutdown target for the next shutdown as set by the operation SelectShutdownTarget.
        arg target: type=EcuM_StateType, direction=OUT  # The shutdown target of the next shutdown.
        arg resetSleepMode: type=EcuM_ModeType, direction=OUT  # The sleep mode (if target is ECUM_STATE_SLEEP) or the reset mechanism (if target is ECUM_STATE_RESET) of the shutdown.
      GetLastShutdownTarget  # Returns the shutdown target of the previous shutdown.
        arg target: type=EcuM_StateType, direction=OUT  # The shutdown target of the previous shutdown.
        arg resetSleepMode: type=EcuM_ModeType, direction=OUT  # The sleep mode (if target is ECUM_STATE_SLEEP) or the reset mechanism (if target is ECUM_STATE_RESET) of the shutdown.
      SelectShutdownCause  # The SW-C selects the cause corresponding to the next shutdown target.
        arg shutdownCause: type=EcuM_ShutdownCauseType, direction=IN  # The selected shutdown cause.
      GetShutdownCause  # Returns the selected shutdown cause as set by the operation SelectShutdownCause.
        arg shutdownCause: type=EcuM_ShutdownCauseType, direction=OUT  # The selected cause of the next shutdown.
    error E_NOT_OK: error-code=1  # The new shutdown target was not set
  client server interface EcuM_BootTarget: is-service=true, service-kind=ECU-MANAGER
    operation SelectBootTarget: possible-error=EcuM_BootTarget/E_NOT_OK  # The SW-C selects a boot target.
      arg BootTarget: type=EcuM_BootTargetType, direction=IN  # The selected boot target.
    operation GetBootTarget: possible-error=EcuM_BootTarget/E_NOT_OK  # Returns the current boot target.
      arg BootTarget: type=EcuM_BootTargetType, direction=OUT  # The currently selected boot target.
    error E_NOT_OK: error-code=1  # The new boot target was not accepted by EcuM
package /MICROSAR/EcuM_swc/ComponentTypes
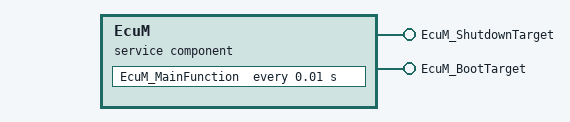
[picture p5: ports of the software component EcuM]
  service sw component type EcuM: category=SERVICE_COMPONENT
    provide port EcuM_ShutdownTarget: provided-interface=EcuM_ShutdownTarget
    provide port EcuM_BootTarget: provided-interface=EcuM_BootTarget
    behavior EcuMInternalBehavior: handle-termination-and-restart=NO-SUPPORT, included-data-type-set=data-type=[EcuM_StateType, EcuM_ModeType, EcuM_TimeType, EcuM_UserType, EcuM_ShutdownCauseType, EcuM_BootTargetType]
      timing event Timer_EcuM_MainFunction: start-on-event=EcuM_MainFunction, period=0.01
      7 x operation invoked event:
        OpEventSelectShutdownTarget_SelectShutdownTarget_EcuM_ShutdownTarget: start-on-event=SelectShutdownTarget, operation=EcuM_ShutdownTarget.SelectShutdownTarget
        OpEventGetShutdownTarget_GetShutdownTarget_EcuM_ShutdownTarget: start-on-event=GetShutdownTarget, operation=EcuM_ShutdownTarget.GetShutdownTarget
        OpEventGetLastShutdownTarget_GetLastShutdownTarget_EcuM_ShutdownTarget: start-on-event=GetLastShutdownTarget, operation=EcuM_ShutdownTarget.GetLastShutdownTarget
        OpEventSelectShutdownCause_SelectShutdownCause_EcuM_ShutdownTarget: start-on-event=SelectShutdownCause, operation=EcuM_ShutdownTarget.SelectShutdownCause
        OpEventGetShutdownCause_GetShutdownCause_EcuM_ShutdownTarget: start-on-event=GetShutdownCause, operation=EcuM_ShutdownTarget.GetShutdownCause
        OpEventSelectBootTarget_SelectBootTarget_EcuM_BootTarget: start-on-event=SelectBootTarget, operation=EcuM_BootTarget.SelectBootTarget
        OpEventGetBootTarget_GetBootTarget_EcuM_BootTarget: start-on-event=GetBootTarget, operation=EcuM_BootTarget.GetBootTarget
      port-api-options:
        enable-take-address=true, indirect-api=false, port=EcuM_ShutdownTarget
        enable-take-address=true, indirect-api=false, port=EcuM_BootTarget
      8 x runnable:
        EcuM_MainFunction
        SelectShutdownTarget: can-be-invoked-concurrently=true, symbol=EcuM_SelectShutdownTarget
        GetShutdownTarget: can-be-invoked-concurrently=true, symbol=EcuM_GetShutdownTarget
        GetLastShutdownTarget: can-be-invoked-concurrently=true, symbol=EcuM_GetLastShutdownTarget
        SelectShutdownCause: can-be-invoked-concurrently=true, symbol=EcuM_SelectShutdownCause
        GetShutdownCause: can-be-invoked-concurrently=true, symbol=EcuM_GetShutdownCause
        SelectBootTarget: can-be-invoked-concurrently=true, symbol=EcuM_SelectBootTarget
        GetBootTarget: can-be-invoked-concurrently=true, symbol=EcuM_GetBootTarget
  swc implementation EcuMImplementation: programming-language=C, behavior=EcuMInternalBehavior
package /MICROSAR/NvM_swc/DataTypes
  impl type NvM_RequestResultType: compu {0=NVM_REQ_OK, 1=NVM_REQ_NOT_OK, 2=NVM_REQ_PENDING, 3=NVM_REQ_INTEGRITY_FAILED, 4=NVM_REQ_BLOCK_SKIPPED, 5=NVM_REQ_NV_INVALIDATED, 6=NVM_REQ_CANCELED, 7=NVM_REQ_REDUNDANCY_FAILED, 8=NVM_REQ_RESTORED_FROM_ROM}, implementation-data-type=ImplementationDataTypes/uint8
  impl type NvM_BlockIdType: range raw 1..32767, implementation-data-type=uint16
  impl type NvM_ServiceIdType: compu {6=NVM_READ_BLOCK, 7=NVM_WRITE_BLOCK, 8=NVM_RESTORE_BLOCK_DEFAULTS, 9=NVM_ERASE_BLOCK, 11=NVM_INVALIDATE_NV_BLOCK, 12=NVM_READ_ALL}, implementation-data-type=ImplementationDataTypes/uint8
package /MICROSAR/NvM_swc/Interfaces
  4 x client server interface, all with is-service=true, service-kind=NON-VOLATILE-RAM-MANAGER:
    NvMAdministration
      operation SetBlockProtection: possible-error=NvMAdministration/E_NOT_OK
        arg ProtectionEnabled: type=ImplementationDataTypes/boolean, direction=IN
      error E_NOT_OK: error-code=1
    NvMService_AC3_SRBS
      6 x operation, all with possible-error=NvMService_AC3_SRBS/E_NOT_OK:
        GetErrorStatus
          arg ErrorStatus: type=DataTypes/NvM_RequestResultType, direction=OUT
        SetRamBlockStatus
          arg RamBlockStatus: type=ImplementationDataTypes/boolean, direction=IN
        ReadBlock
          arg DstPtr: type=dtRef_VOID, direction=IN
        WriteBlock
          arg SrcPtr: type=dtRef_const_VOID, direction=IN
        InvalidateNvBlock
        EraseBlock
      error E_NOT_OK: error-code=1
    NvMService_AC3_SRBS_Defs
      7 x operation, all with possible-error=NvMService_AC3_SRBS_Defs/E_NOT_OK:
        GetErrorStatus
          arg ErrorStatus: type=DataTypes/NvM_RequestResultType, direction=OUT
        SetRamBlockStatus
          arg RamBlockStatus: type=ImplementationDataTypes/boolean, direction=IN
        ReadBlock
          arg DstPtr: type=dtRef_VOID, direction=IN
        WriteBlock
          arg SrcPtr: type=dtRef_const_VOID, direction=IN
        RestoreBlockDefaults
          arg DstPtr: type=dtRef_VOID, direction=IN
        InvalidateNvBlock
        EraseBlock
      error E_NOT_OK: error-code=1
    NvMNotifyJobFinished
      operation JobFinished
        arg ServiceId: type=DataTypes/NvM_ServiceIdType, direction=IN
        arg JobResult: type=DataTypes/NvM_RequestResultType, direction=IN
package /MICROSAR/NvM_swc/ComponentTypes
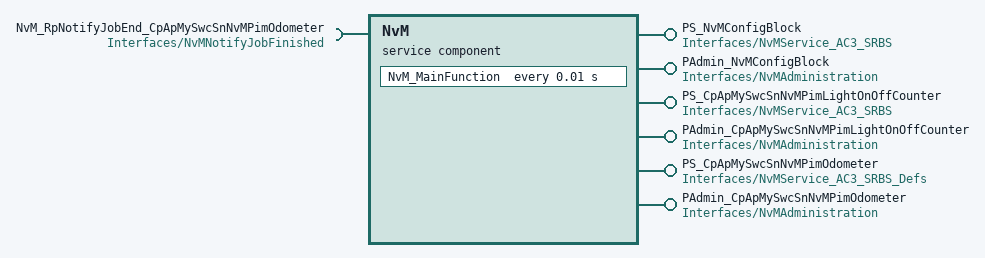
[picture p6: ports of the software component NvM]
  service sw component type NvM: category=SERVICE_COMPONENT
    6 x provide port:
      PS_NvMConfigBlock: provided-interface=Interfaces/NvMService_AC3_SRBS
      PAdmin_NvMConfigBlock: provided-interface=Interfaces/NvMAdministration
      PS_CpApMySwcSnNvMPimLightOnOffCounter: provided-interface=Interfaces/NvMService_AC3_SRBS
      PAdmin_CpApMySwcSnNvMPimLightOnOffCounter: provided-interface=Interfaces/NvMAdministration
      PS_CpApMySwcSnNvMPimOdometer: provided-interface=Interfaces/NvMService_AC3_SRBS_Defs
      PAdmin_CpApMySwcSnNvMPimOdometer: provided-interface=Interfaces/NvMAdministration
    require port NvM_RpNotifyJobEnd_CpApMySwcSnNvMPimOdometer: required-interface=Interfaces/NvMNotifyJobFinished
    behavior NvMInternalBehavior: handle-termination-and-restart=NO-SUPPORT
      timing event Timer_NvM_MainFunction: start-on-event=NvM_MainFunction, period=0.01
      22 x operation invoked event:
        OpEventGetErrorStatus_GetErrorStatus_PS_NvMConfigBlock: start-on-event=GetErrorStatus, operation=PS_NvMConfigBlock.GetErrorStatus
        OpEventSetRamBlockStatus_SetRamBlockStatus_PS_NvMConfigBlock: start-on-event=SetRamBlockStatus, operation=PS_NvMConfigBlock.SetRamBlockStatus
        OpEventReadBlock_ReadBlock_PS_NvMConfigBlock: start-on-event=ReadBlock, operation=PS_NvMConfigBlock.ReadBlock
        OpEventWriteBlock_WriteBlock_PS_NvMConfigBlock: start-on-event=WriteBlock, operation=PS_NvMConfigBlock.WriteBlock
        OpEventInvalidateNvBlock_InvalidateNvBlock_PS_NvMConfigBlock: start-on-event=InvalidateNvBlock, operation=PS_NvMConfigBlock.InvalidateNvBlock
        OpEventEraseBlock_EraseBlock_PS_NvMConfigBlock: start-on-event=EraseBlock, operation=PS_NvMConfigBlock.EraseBlock
        OpEventSetBlockProtection_SetBlockProtection_PAdmin_NvMConfigBlock: start-on-event=SetBlockProtection, operation=PAdmin_NvMConfigBlock.SetBlockProtection
        OpEventGetErrorStatus_GetErrorStatus_PS_CpApMySwcSnNvMPimLightOnOffCounter: start-on-event=GetErrorStatus, operation=PS_CpApMySwcSnNvMPimLightOnOffCounter.GetErrorStatus
        OpEventGetErrorStatus_GetErrorStatus_PS_CpApMySwcSnNvMPimOdometer: start-on-event=GetErrorStatus, operation=PS_CpApMySwcSnNvMPimOdometer.GetErrorStatus
        OpEventSetRamBlockStatus_SetRamBlockStatus_PS_CpApMySwcSnNvMPimLightOnOffCounter: start-on-event=SetRamBlockStatus, operation=PS_CpApMySwcSnNvMPimLightOnOffCounter.SetRamBlockStatus
        OpEventSetRamBlockStatus_SetRamBlockStatus_PS_CpApMySwcSnNvMPimOdometer: start-on-event=SetRamBlockStatus, operation=PS_CpApMySwcSnNvMPimOdometer.SetRamBlockStatus
        OpEventReadBlock_ReadBlock_PS_CpApMySwcSnNvMPimLightOnOffCounter: start-on-event=ReadBlock, operation=PS_CpApMySwcSnNvMPimLightOnOffCounter.ReadBlock
        OpEventReadBlock_ReadBlock_PS_CpApMySwcSnNvMPimOdometer: start-on-event=ReadBlock, operation=PS_CpApMySwcSnNvMPimOdometer.ReadBlock
        OpEventWriteBlock_WriteBlock_PS_CpApMySwcSnNvMPimLightOnOffCounter: start-on-event=WriteBlock, operation=PS_CpApMySwcSnNvMPimLightOnOffCounter.WriteBlock
        OpEventWriteBlock_WriteBlock_PS_CpApMySwcSnNvMPimOdometer: start-on-event=WriteBlock, operation=PS_CpApMySwcSnNvMPimOdometer.WriteBlock
        OpEventInvalidateNvBlock_InvalidateNvBlock_PS_CpApMySwcSnNvMPimLightOnOffCounter: start-on-event=InvalidateNvBlock, operation=PS_CpApMySwcSnNvMPimLightOnOffCounter.InvalidateNvBlock
        OpEventInvalidateNvBlock_InvalidateNvBlock_PS_CpApMySwcSnNvMPimOdometer: start-on-event=InvalidateNvBlock, operation=PS_CpApMySwcSnNvMPimOdometer.InvalidateNvBlock
        OpEventEraseBlock_EraseBlock_PS_CpApMySwcSnNvMPimLightOnOffCounter: start-on-event=EraseBlock, operation=PS_CpApMySwcSnNvMPimLightOnOffCounter.EraseBlock
        OpEventEraseBlock_EraseBlock_PS_CpApMySwcSnNvMPimOdometer: start-on-event=EraseBlock, operation=PS_CpApMySwcSnNvMPimOdometer.EraseBlock
        OpEventSetBlockProtection_SetBlockProtection_PAdmin_CpApMySwcSnNvMPimLightOnOffCounter: start-on-event=SetBlockProtection, operation=PAdmin_CpApMySwcSnNvMPimLightOnOffCounter.SetBlockProtection
        OpEventSetBlockProtection_SetBlockProtection_PAdmin_CpApMySwcSnNvMPimOdometer: start-on-event=SetBlockProtection, operation=PAdmin_CpApMySwcSnNvMPimOdometer.SetBlockProtection
        OpEventRestoreBlockDefaults_RestoreBlockDefaults_PS_CpApMySwcSnNvMPimOdometer: start-on-event=RestoreBlockDefaults, operation=PS_CpApMySwcSnNvMPimOdometer.RestoreBlockDefaults
      port-api-options:
        {enable-take-address=true, indirect-api=false, port-defined-argument-value{value=1, value-type=NvM_BlockIdType}, port=PS_NvMConfigBlock}
        {enable-take-address=true, indirect-api=false, port-defined-argument-value{value=1, value-type=NvM_BlockIdType}, port=PAdmin_NvMConfigBlock}
        {enable-take-address=true, indirect-api=false, port-defined-argument-value{value=3, value-type=NvM_BlockIdType}, port=PS_CpApMySwcSnNvMPimLightOnOffCounter}
        {enable-take-address=true, indirect-api=false, port-defined-argument-value{value=3, value-type=NvM_BlockIdType}, port=PAdmin_CpApMySwcSnNvMPimLightOnOffCounter}
        {enable-take-address=true, indirect-api=false, port-defined-argument-value{value=4, value-type=NvM_BlockIdType}, port=PS_CpApMySwcSnNvMPimOdometer}
        {enable-take-address=true, indirect-api=false, port-defined-argument-value{value=4, value-type=NvM_BlockIdType}, port=PAdmin_CpApMySwcSnNvMPimOdometer}
        enable-take-address=true, indirect-api=false, port=NvM_RpNotifyJobEnd_CpApMySwcSnNvMPimOdometer
      9 x runnable:
        NvM_MainFunction
          sync call OpServerCallNvM_MainFunction_JobFinished_NvM_RpNotifyJobEnd_CpApMySwcSnNvMPimOdometer: operation=NvM_RpNotifyJobEnd_CpApMySwcSnNvMPimOdometer.JobFinished, timeout=0
        GetErrorStatus: can-be-invoked-concurrently=true, symbol=NvM_GetErrorStatus
        SetRamBlockStatus: can-be-invoked-concurrently=true, symbol=NvM_SetRamBlockStatus
        ReadBlock: can-be-invoked-concurrently=true, symbol=NvM_ReadBlock
        WriteBlock: can-be-invoked-concurrently=true, symbol=NvM_WriteBlock
        InvalidateNvBlock: can-be-invoked-concurrently=true, symbol=NvM_InvalidateNvBlock
        EraseBlock: can-be-invoked-concurrently=true, symbol=NvM_EraseNvBlock
        SetBlockProtection: can-be-invoked-concurrently=true, symbol=NvM_SetBlockProtection
        RestoreBlockDefaults: can-be-invoked-concurrently=true, symbol=NvM_RestoreBlockDefaults
  swc implementation NvMImplementation: programming-language=C, behavior=NvMInternalBehavior
package /COM/VECTOR/CFG/WORKFLOW/SYSDESC/SYNC
  system SYSTEM: category=ECU_EXTRACT
    system mapping MAPPINGS
      data-mappings:
        data-element=COMPOSITIONTYPE.PpDoorStateRearLeft.DeDoorState, system-signal=sig_State_RearLeftDoor
        data-element=COMPOSITIONTYPE.PpDoorStateRearRight.DeDoorState, system-signal=sig_State_RearRightDoor
        data-element=COMPOSITIONTYPE.PpLightStateRear.DeLightState, system-signal=sig_RearInteriorLight
    root-software-compositions:
      root sw composition prototype COMPOSITIONTYPE: software-composition=COMPOSITIONTYPE
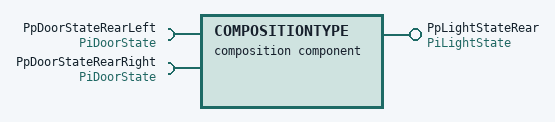
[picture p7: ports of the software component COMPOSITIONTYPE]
  composition sw component type COMPOSITIONTYPE  # UB:Derived from original system description
    require port PpDoorStateRearLeft: nonqueued-receiver-com-spec{data-element=DeDoorState, filter=data-filter-type=ALWAYS, init-value=0}, required-interface=PiDoorState
    require port PpDoorStateRearRight: nonqueued-receiver-com-spec{data-element=DeDoorState, filter=data-filter-type=ALWAYS, init-value=0}, required-interface=PiDoorState
    provide port PpLightStateRear: nonqueued-sender-com-spec{data-element=DeLightState, init-value=0}, provided-interface=PiLightState
    14 x component:
      BswM: type=BswM
      ComM: type=ComM
      Det: type=Det
      EcuM: type=EcuM
      DemMaster_0: type=DemMaster_0
      DemSatellite_0: type=DemSatellite_0
      CpSaDoorFrontLeft: type=CtSaDoor
      CpSaInteriorLightFront: type=CtSaInteriorLight
      CpApMySwc: type=CtApMySwc
      CpSaDoorFrontRight: type=CtSaDoor
      NvM: type=NvM
      CpCddIoHwAb: type=CtCddIoHwAb
      CpSaDisplay: type=CtSaDisplay
      Dcm: type=Dcm
    connect CpApMySwc.PpLightStateFront -> CpSaInteriorLightFront.PpLightState  # UB:Derived from original system description
    connect CpSaDoorFrontLeft.PpDoorState -> CpApMySwc.PpDoorStateFrontLeft  # UB:Derived from original system description
    connect CpSaDoorFrontRight.PpDoorState -> CpApMySwc.PpDoorStateFrontRight  # UB:Derived from original system description
    connect CpCddIoHwAb.PpInteriorLightFront -> CpSaInteriorLightFront.PpInteriorLightIoHwAb  # UB:Derived from original system description
    connect CpCddIoHwAb.PpDoorFrontLeft -> CpSaDoorFrontLeft.PpDoorIoHwAb  # UB:Derived from original system description
    connect CpCddIoHwAb.PpDoorFrontRight -> CpSaDoorFrontRight.PpDoorIoHwAb  # UB:Derived from original system description
    connect CpCddIoHwAb.PpInteriorLightFrontDEFECT -> CpSaInteriorLightFront.PpInteriorLightDefect  # UB:Derived from original system description
    delegate CpApMySwc.PpLightStateRear <-> outer port COMPOSITIONTYPE/PpLightStateRear  # UB:Derived from original system description
    delegate CpApMySwc.PpDoorStateRearRight <-> outer port COMPOSITIONTYPE/PpDoorStateRearRight  # UB:Derived from original system description
    delegate CpApMySwc.PpDoorStateRearLeft <-> outer port COMPOSITIONTYPE/PpDoorStateRearLeft  # UB:Derived from original system description
    connect CpApMySwc.PpDisplayState -> CpSaDisplay.PpDisplayState  # UB:Derived from original system description
    connect CpSaDisplay.PpLocalIgnitionState -> CpApMySwc.PpLocalIgnitionState  # UB:Derived from original system description
    connect CpCddIoHwAb.PpDisplayState -> CpSaDisplay.PpDisplayStateIoHwAb  # UB:Derived from original system description
    connect CpCddIoHwAb.PpLocalClamp15 -> CpSaDisplay.PplocalIgnitionStateIoHwAb  # UB:Derived from original system description
    connect BswM.Switch_ESH_ModeSwitch -> BswM.Notification_ESH_ModeNotification
    connect ComM.UR_USR_INTERIOR_LIGHT -> CpApMySwc.PpComMUserRequestCtApMySwc
    connect CpApMySwc.PpBswMRunRequestCtApMySwc -> BswM.Request_ESH_RunRequest_0
    connect CpApMySwc.PpBswMPostRunRequestCtApMySwc -> BswM.Request_ESH_PostRunRequest_0
    connect ComM.UM_USR_INTERIOR_LIGHT -> CpApMySwc.PpComMCurrentModeCtApMySwc
    connect BswM.Provide_MrpPShutdownTimerDisplay -> CpApMySwc.PpMrpPShutdownTimerDisplayCtApMySwc
    connect BswM.Switch_ESH_ModeSwitch -> CpApMySwc.PpBswMEshModeNotificationCtApMySwc
    connect NvM.PS_CpApMySwcSnNvMPimLightOnOffCounter -> CpApMySwc.PpNvMLightOnOffCtApMySwc
    connect CpApMySwc.PpNvMNotifyJobFinishedOdometerCtApMySwc -> NvM.NvM_RpNotifyJobEnd_CpApMySwcSnNvMPimOdometer
    connect NvM.PS_CpApMySwcSnNvMPimOdometer -> CpApMySwc.PpNvMOdometerCtApMySwc
    connect CpApMySwc.DataServices_Diag_RWDI_LightOnOffCounter_LightOnOffCounter_Value -> Dcm.DataServices_Diag_RWDI_LightOnOffCounter_LightOnOffCounter_Value
    connect CpApMySwc.CBReadData_OccurrenceCounter_OccurenceCounter -> DemMaster_0.CBReadData_OccurrenceCounter_OccurenceCounter
    connect CpApMySwc.CBReadData_OdometerValue_OdometerValue -> DemMaster_0.CBReadData_OdometerValue_OdometerValue
    connect DemMaster_0.OpCycle_IgnitionCycle -> CpApMySwc.OpCycle_IgnitionCycle
    connect DemSatellite_0.Event_DTC_0x000002 -> CpSaInteriorLightFront.Event_DTC_0x000002
  end to end protection set E2EPROTECTIONSET
  port interface mapping set PORTINTERFACEMAPPINGSET
package /ComponentTypes
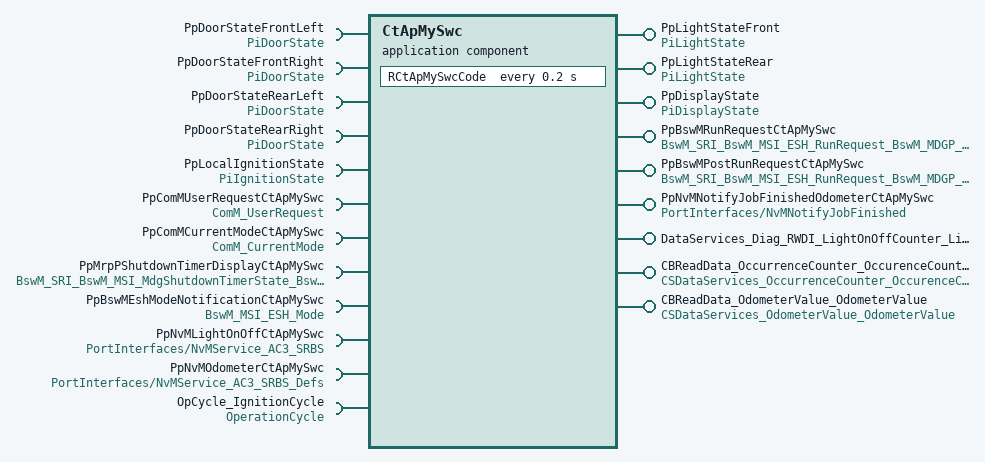
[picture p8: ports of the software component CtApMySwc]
  application sw component type CtApMySwc
    require port PpDoorStateFrontLeft: nonqueued-receiver-com-spec{data-element=DeDoorState, filter=data-filter-type=ALWAYS, init-value=constant-reference=CDoorClosed}, required-interface=PiDoorState
    require port PpDoorStateFrontRight: nonqueued-receiver-com-spec{data-element=DeDoorState, filter=data-filter-type=ALWAYS, init-value=constant-reference=CDoorClosed}, required-interface=PiDoorState
    provide port PpLightStateFront: nonqueued-sender-com-spec{data-element=DeLightState, init-value=constant-reference=CLightOff}, provided-interface=PiLightState
    require port PpDoorStateRearLeft: nonqueued-receiver-com-spec{data-element=DeDoorState, filter=data-filter-type=ALWAYS, init-value=0}, required-interface=PiDoorState
    require port PpDoorStateRearRight: nonqueued-receiver-com-spec{data-element=DeDoorState, filter=data-filter-type=ALWAYS, init-value=0}, required-interface=PiDoorState
    provide port PpLightStateRear: nonqueued-sender-com-spec{data-element=DeLightState, init-value=0}, provided-interface=PiLightState
    require port PpLocalIgnitionState: nonqueued-receiver-com-spec{data-element=DeIgnitionState, filter=data-filter-type=ALWAYS, init-value=1}, required-interface=PiIgnitionState
    provide port PpDisplayState: provided-interface=PiDisplayState
      provided-com-specs:
        data-element=DeDisplayBusState, init-value=constant-reference=CDisplayOff
        data-element=DeLightOnOffCounter, init-value=constant-reference=CUInt32Zero
        data-element=DeOdometerValue, init-value=constant-reference=CUInt32Zero
        data-element=DeOdometerWriteRequestPending, init-value=constant-reference=CWriteReqNotPending
    require port PpComMUserRequestCtApMySwc: required-com-specs=[RequestComMode, GetCurrentComMode, GetMaxComMode, GetRequestedComMode], required-interface=ComM_UserRequest
    provide port PpBswMRunRequestCtApMySwc: nonqueued-sender-com-spec=BswM_SRI_BswM_MSI_ESH_RunRequest_BswM_MDGP_ESH_RunRequest/requestedMode, provided-interface=BswM_SRI_BswM_MSI_ESH_RunRequest_BswM_MDGP_ESH_RunRequest
    provide port PpBswMPostRunRequestCtApMySwc: nonqueued-sender-com-spec=BswM_SRI_BswM_MSI_ESH_RunRequest_BswM_MDGP_ESH_RunRequest/requestedMode, provided-interface=BswM_SRI_BswM_MSI_ESH_RunRequest_BswM_MDGP_ESH_RunRequest
    5 x require port:
      PpComMCurrentModeCtApMySwc: mode-switch-receiver-com-spec=currentMode, required-interface=ComM_CurrentMode
      PpMrpPShutdownTimerDisplayCtApMySwc: nonqueued-receiver-com-spec=data-element=BswM_SRI_BswM_MSI_MdgShutdownTimerState_BswM_MDGP_MdgShutdownTimerState/requestedMode, required-interface=BswM_SRI_BswM_MSI_MdgShutdownTimerState_BswM_MDGP_MdgShutdownTimerState
      PpBswMEshModeNotificationCtApMySwc: mode-switch-receiver-com-spec=BswM_MDGP_ESH_Mode, required-interface=BswM_MSI_ESH_Mode
      PpNvMLightOnOffCtApMySwc: required-interface=PortInterfaces/NvMService_AC3_SRBS
        required-com-specs:
          NvMService_AC3_SRBS/WriteBlock
          NvMService_AC3_SRBS/SetRamBlockStatus
          NvMService_AC3_SRBS/ReadBlock
          NvMService_AC3_SRBS/InvalidateNvBlock
          NvMService_AC3_SRBS/GetErrorStatus
          NvMService_AC3_SRBS/EraseBlock
      PpNvMOdometerCtApMySwc: required-interface=PortInterfaces/NvMService_AC3_SRBS_Defs
        required-com-specs:
          NvMService_AC3_SRBS_Defs/WriteBlock
          NvMService_AC3_SRBS_Defs/SetRamBlockStatus
          NvMService_AC3_SRBS_Defs/RestoreBlockDefaults
          NvMService_AC3_SRBS_Defs/ReadBlock
          NvMService_AC3_SRBS_Defs/InvalidateNvBlock
          NvMService_AC3_SRBS_Defs/GetErrorStatus
          NvMService_AC3_SRBS_Defs/EraseBlock
    4 x provide port:
      PpNvMNotifyJobFinishedOdometerCtApMySwc: server-com-spec{operation=NvMNotifyJobFinished/JobFinished, queue-length=1}, provided-interface=PortInterfaces/NvMNotifyJobFinished
      DataServices_Diag_RWDI_LightOnOffCounter_LightOnOffCounter_Value: provided-interface=DataServices_Diag_RWDI_LightOnOffCounter_LightOnOffCounter_Value
        provided-com-specs:
          operation=DataServices_Diag_RWDI_LightOnOffCounter_LightOnOffCounter_Value/ReadData, queue-length=1
          operation=ConditionCheckRead, queue-length=1
          operation=WriteData, queue-length=1
      CBReadData_OccurrenceCounter_OccurenceCounter: server-com-spec{operation=CSDataServices_OccurrenceCounter_OccurenceCounter/ReadData, queue-length=1}, provided-interface=CSDataServices_OccurrenceCounter_OccurenceCounter
      CBReadData_OdometerValue_OdometerValue: server-com-spec{operation=CSDataServices_OdometerValue_OdometerValue/ReadData, queue-length=1}, provided-interface=CSDataServices_OdometerValue_OdometerValue
    require port OpCycle_IgnitionCycle: required-com-specs=[GetOperationCycleState, SetOperationCycleState], required-interface=OperationCycle
    behavior CtApMySwc_InternalBehavior: data-type-mapping=DemoTypeMapping
      exclusive area ExArLightOnOffCounter
      exclusive area ExArOdometer
      ar-typed-per-instance-memorys:
        data PimOdometer: sw-calibration-access=READ-ONLY, type=AdtOdometer
        data PimLightOnOffCounter: sw-calibration-access=READ-ONLY, type=AdtLightOnOffCounter
      timing event TMT_RCtApMySwcCode: start-on-event=RCtApMySwcCode, period=0.2
      init event CtApMySwc_InitEvent: start-on-event=RCtApMySwcInit
      swc mode switch event MST_RCtApMySwcComM_ModeChange_FULL_COMM_Entry_0: start-on-event=RCtApMySwcComM_ModeChange_FULL_COMM_Entry, activation=ON-ENTRY, mode=PpComMCurrentModeCtApMySwc.currentMode.COMM_FULL_COMMUNICATION
      swc mode switch event MST_RCtApMySwcComM_ModeChange_FULL_COMM_Exit_0: start-on-event=RCtApMySwcComM_ModeChange_FULL_COMM_Exit, activation=ON-EXIT, mode=PpComMCurrentModeCtApMySwc.currentMode.COMM_FULL_COMMUNICATION
      data received event DRT_Runnable_PpMrpPShutdownTimerDisplayCtApMySwc_requestedMode: start-on-event=RCtApMySwcPostRunCode, data=PpMrpPShutdownTimerDisplayCtApMySwc.requestedMode
      swc mode switch event MST_RCtApMySwcPostRunCode_0: start-on-event=RCtApMySwcPostRunCode, activation=ON-ENTRY, mode=PpBswMEshModeNotificationCtApMySwc.BswM_MDGP_ESH_Mode.POSTRUN
      6 x operation invoked event:
        OIT_PpNvMNotifyJobFinishedOdometerCtApMySwc_JobFinished_PpNvMNotifyJobFinishedOdometerCtApMySwc_JobFinished: start-on-event=PpNvMNotifyJobFinishedOdometerCtApMySwc_JobFinished, operation=PpNvMNotifyJobFinishedOdometerCtApMySwc.JobFinished
        OIT_DataServices_Diag_RWDI_LightOnOffCounter_LightOnOffCounter_Value_WriteData_DataServices_Diag_RWDI_LightOnOffCounter_9798F8A6: start-on-event=DataServices_Diag_RWDI_LightOnOffCounter_LightOnOffCounter_Value_WriteData, operation=DataServices_Diag_RWDI_LightOnOffCounter_LightOnOffCounter_Value.WriteData
        OIT_DataServices_Diag_RWDI_LightOnOffCounter_LightOnOffCounter_Value_ConditionCheckRead_DataServices_Diag_RWDI_LightOnOf2065F94A: start-on-event=DataServices_Diag_RWDI_LightOnOffCounter_LightOnOffCounter_Value_ConditionCheckRead, operation=DataServices_Diag_RWDI_LightOnOffCounter_LightOnOffCounter_Value.ConditionCheckRead
        OIT_DataServices_Diag_RWDI_LightOnOffCounter_LightOnOffCounter_Value_ReadData_DataServices_Diag_RWDI_LightOnOffCounter_LBCB6C10A: start-on-event=DataServices_Diag_RWDI_LightOnOffCounter_LightOnOffCounter_Value_ReadData, operation=DataServices_Diag_RWDI_LightOnOffCounter_LightOnOffCounter_Value.ReadData
        OIT_CBReadData_OccurrenceCounter_OccurenceCounter_ReadData_CBReadData_OccurrenceCounter_OccurenceCounter_ReadData: start-on-event=CBReadData_OccurrenceCounter_OccurenceCounter_ReadData, operation=CBReadData_OccurrenceCounter_OccurenceCounter.ReadData
        OIT_CBReadData_OdometerValue_OdometerValue_ReadData_CBReadData_OdometerValue_OdometerValue_ReadData: start-on-event=CBReadData_OdometerValue_OdometerValue_ReadData, operation=CBReadData_OdometerValue_OdometerValue.ReadData
      explicit-inter-runnable-variables:
        data IrvDoorStateOld: type=uint16, init-value=constant-reference=CDoorClosed
      11 x runnable:
        RCtApMySwcCode: can-enter-exclusive-area=[ExArLightOnOffCounter, ExArOdometer]
          data-read-access:
            access READ_PpDoorStateFrontLeft_DeDoorState: accessed-variable=PpDoorStateFrontLeft.DeDoorState
            access REC_PpDoorStateRearLeft_DeDoorState: accessed-variable=PpDoorStateRearLeft.DeDoorState
          data-receive-point-by-arguments:
            access REC_PpDoorStateFrontRight_DeDoorState: accessed-variable=PpDoorStateFrontRight.DeDoorState
            access REC_PpDoorStateRearRight_DeDoorState: accessed-variable=PpDoorStateRearRight.DeDoorState
            access REC_PpLocalIgnitionState_DeIgnitionState: accessed-variable=PpLocalIgnitionState.DeIgnitionState
          data-send-points:
            7 x access:
              SEND_PpLightStateFront_DeLightState: accessed-variable=PpLightStateFront.DeLightState
              SEND_PpLightStateRear_DeLightState: accessed-variable=PpLightStateRear.DeLightState
              SEND_PpDisplayState_DeDisplayBusState: accessed-variable=PpDisplayState.DeDisplayBusState
              SEND_PpBswMRunRequestCtApMySwc_requestedMode: accessed-variable=PpBswMRunRequestCtApMySwc.requestedMode
              SEND_PpDisplayState_DeLightOnOffCounter: accessed-variable=PpDisplayState.DeLightOnOffCounter
              SEND_PpDisplayState_DeOdometerValue: accessed-variable=PpDisplayState.DeOdometerValue
              SEND_PpDisplayState_DeOdometerWriteRequestPending: accessed-variable=PpDisplayState.DeOdometerWriteRequestPending
          read-local-variables:
            access Read_IrvDoorStateOld: accessed-variable=IrvDoorStateOld
          4 x sync call:
            SC_PpComMUserRequestCtApMySwc_RequestComMode: operation=PpComMUserRequestCtApMySwc.RequestComMode
            SC_PpNvMLightOnOffCounterCtApMySwc_WriteBlock: operation=PpNvMLightOnOffCtApMySwc.WriteBlock
            SC_PpNvMPimOdometerCtApMySwc_GetErrorStatus: operation=PpNvMOdometerCtApMySwc.GetErrorStatus
            SC_PpNvMPimOdometerCtApMySwc_WriteBlock: operation=PpNvMOdometerCtApMySwc.WriteBlock
          written-local-variables:
            access WRITE_IrvDoorStateOld: accessed-variable=IrvDoorStateOld
        RCtApMySwcInit: can-enter-exclusive-area=ExArLightOnOffCounter
          data-send-points:
            access SEND_PpBswMPostRunRequestCtApMySwc_requestedMode: accessed-variable=PpBswMPostRunRequestCtApMySwc.requestedMode
            access SEND_PpBswMRunRequestCtApMySwc_requestedMode: accessed-variable=PpBswMRunRequestCtApMySwc.requestedMode
            access SEND_PpDisplayState_DeLightOnOffCounter: accessed-variable=PpDisplayState.DeLightOnOffCounter
          sync call SC_OpCycle_IgnitionCycle_SetOperationCycleState: operation=OpCycle_IgnitionCycle.SetOperationCycleState
        RCtApMySwcComM_ModeChange_FULL_COMM_Entry
          data-send-points:
            access SEND_PpDisplayState_DeDisplayBusState: accessed-variable=PpDisplayState.DeDisplayBusState
        RCtApMySwcComM_ModeChange_FULL_COMM_Exit
          data-send-points:
            access SEND_PpDisplayState_DeDisplayBusState: accessed-variable=PpDisplayState.DeDisplayBusState
        RCtApMySwcPostRunCode
          data-receive-point-by-arguments:
            access REC_PpMrpPShutdownTimerDisplayCtApMySwc_requestedMode: accessed-variable=PpMrpPShutdownTimerDisplayCtApMySwc.requestedMode
          data-send-points:
            access SEND_PpBswMPostRunRequestCtApMySwc_requestedMode: accessed-variable=PpBswMPostRunRequestCtApMySwc.requestedMode
            access SEND_PpLightStateFront_DeLightState: accessed-variable=PpLightStateFront.DeLightState
            access SEND_PpLightStateRear_DeLightState: accessed-variable=PpLightStateRear.DeLightState
          sync call SC_PpComMUserRequestCtApMySwc_RequestComMode: operation=PpComMUserRequestCtApMySwc.RequestComMode
        PpNvMNotifyJobFinishedOdometerCtApMySwc_JobFinished
          data-send-points:
            access SEND_PpDisplayState_DeOdometerWriteRequestPending: accessed-variable=PpDisplayState.DeOdometerWriteRequestPending
        DataServices_Diag_RWDI_LightOnOffCounter_LightOnOffCounter_Value_WriteData: can-enter-exclusive-area=ExArLightOnOffCounter
        DataServices_Diag_RWDI_LightOnOffCounter_LightOnOffCounter_Value_ConditionCheckRead: can-enter-exclusive-area=ExArLightOnOffCounter
        DataServices_Diag_RWDI_LightOnOffCounter_LightOnOffCounter_Value_ReadData: can-enter-exclusive-area=ExArLightOnOffCounter
        CBReadData_OccurrenceCounter_OccurenceCounter_ReadData
        CBReadData_OdometerValue_OdometerValue_ReadData: can-enter-exclusive-area=ExArOdometer
      swc service dependency SnNvMPimLightOnOffCounter: assigned-datas=role-based-data-assignment={role=ramBlock, used-data-element=PimLightOnOffCounter}, assigned-ports=role-based-port-assignment={port-prototype=PpNvMLightOnOffCtApMySwc, role=NvMService_AC3_SRBS}
        service-needs:
          nv block needs SnNvMPimLightOnOffCounter: readonly=false, resistant-to-changed-sw=false, restore-at-start=true, store-at-shutdown=true, write-only-once=false
      swc service dependency SnNvMPimOdometer
        assigned-datas:
          role=ramBlock, used-data-element=PimOdometer
          role=defaultValue, used-parameter-element=CalOdometer
        assigned-ports:
          port-prototype=PpNvMOdometerCtApMySwc, role=NvMService_AC3_SRBS_Defs
          port-prototype=PpNvMNotifyJobFinishedOdometerCtApMySwc, role=NvMNotifyJobFinished
        service-needs:
          nv block needs SnNvMPimOdometer: readonly=false, resistant-to-changed-sw=false, restore-at-start=true, store-at-shutdown=true, write-only-once=false
      shared-parameters:
        parameter data prototype CalOdometer: sw-calibration-access=READ-WRITE, type=AdtOdometer, init-value=constant-reference=COdometerDefault
  swc implementation CtApMySwc_Implementation: behavior=CtApMySwc_InternalBehavior
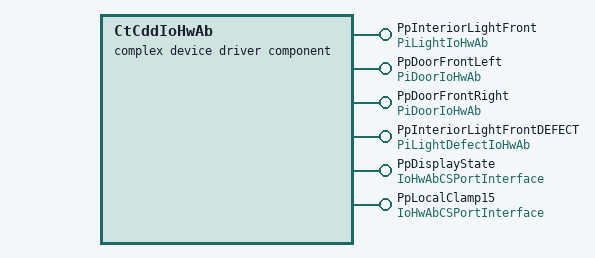
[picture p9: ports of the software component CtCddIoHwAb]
  complex device driver sw component type CtCddIoHwAb
    6 x provide port:
      PpInteriorLightFront: server-com-spec{operation=PiLightIoHwAb/WriteChannel, queue-length=1}, provided-interface=PiLightIoHwAb
      PpDoorFrontLeft: server-com-spec{operation=PiDoorIoHwAb/ReadChannel, queue-length=1}, provided-interface=PiDoorIoHwAb
      PpDoorFrontRight: server-com-spec{operation=PiDoorIoHwAb/ReadChannel, queue-length=1}, provided-interface=PiDoorIoHwAb
      PpInteriorLightFrontDEFECT: server-com-spec{operation=PiLightDefectIoHwAb/ReadChannel, queue-length=1}, provided-interface=PiLightDefectIoHwAb
      PpDisplayState: provided-interface=IoHwAbCSPortInterface
        provided-com-specs:
          operation=IoHwAbCSPortInterface/ReadChannel, queue-length=1
          operation=IoHwAbCSPortInterface/WriteChannel, queue-length=1
      PpLocalClamp15: provided-interface=IoHwAbCSPortInterface
        provided-com-specs:
          operation=IoHwAbCSPortInterface/ReadChannel, queue-length=1
          operation=IoHwAbCSPortInterface/WriteChannel, queue-length=1
    behavior CtCddIoHwAb_InternalBehavior
      8 x operation invoked event:
        OIT_PpDoorFrontLeft_ReadChannel_PpDoorFrontLeft_ReadChannel: start-on-event=RCtCddIoHwAb_PpDoorFrontLeft_ReadChannel, operation=PpDoorFrontLeft.ReadChannel
        OIT_PpInteriorLightFront_WriteChannel_PpInteriorLightFront_WriteChannel: start-on-event=RCtCddIoHwAb_PpInteriorLightFront_WriteChannel, operation=PpInteriorLightFront.WriteChannel
        OIT_PpDoorFrontRight_ReadChannel_PpDoorFrontRight_ReadChannel: start-on-event=RCtCddIoHwAb_PpDoorFrontRight_ReadChannel, operation=PpDoorFrontRight.ReadChannel
        OIT_PpInteriorLightFrontDEFECT_ReadChannel_PpInteriorLightFrontDEFECT_ReadChannel: start-on-event=RCtCddIoHwAb_PpInteriorLightFrontDEFECT_ReadChannel, operation=PpInteriorLightFrontDEFECT.ReadChannel
        OIT_RCtCddIoHwAb_PpDisplayState_ReadChannel_PpDisplayState_ReadChannel: start-on-event=RCtCddIoHwAb_PpDisplayState_ReadChannel, operation=PpDisplayState.ReadChannel
        OIT_RCtCddIoHwAb_PpDisplayState_WriteChannel_PpDisplayState_WriteChannel: start-on-event=RCtCddIoHwAb_PpDisplayState_WriteChannel, operation=PpDisplayState.WriteChannel
        OIT_RCtCddIoHwAb_PpLocalClamp15_ReadChannel_PpLocalClamp15_ReadChannel: start-on-event=RCtCddIoHwAb_PpLocalClamp15_ReadChannel, operation=PpLocalClamp15.ReadChannel
        OIT_RCtCddIoHwAb_PpLocalClamp15_WriteChannel_PpLocalClamp15_WriteChannel: start-on-event=RCtCddIoHwAb_PpLocalClamp15_WriteChannel, operation=PpLocalClamp15.WriteChannel
      8 x runnable:
        RCtCddIoHwAb_PpDoorFrontLeft_ReadChannel
        RCtCddIoHwAb_PpInteriorLightFront_WriteChannel
        RCtCddIoHwAb_PpDoorFrontRight_ReadChannel
        RCtCddIoHwAb_PpInteriorLightFrontDEFECT_ReadChannel
        RCtCddIoHwAb_PpDisplayState_ReadChannel
        RCtCddIoHwAb_PpDisplayState_WriteChannel
        RCtCddIoHwAb_PpLocalClamp15_ReadChannel
        RCtCddIoHwAb_PpLocalClamp15_WriteChannel
  swc implementation CtCddIoHwAb_Implementation: behavior=CtCddIoHwAb_InternalBehavior
  sensor actuator sw component type CtSaDisplay
    require port PpDisplayState: required-interface=PiDisplayState
      required-com-specs:
        data-element=DeDisplayBusState, filter=data-filter-type=ALWAYS, init-value=constant-reference=CBackLightDimCtrlInit
        data-element=DeLightOnOffCounter, filter=data-filter-type=ALWAYS, init-value=constant-reference=CUInt32Zero
        data-element=DeOdometerValue, filter=data-filter-type=ALWAYS, init-value=constant-reference=CUInt32Zero
        data-element=DeOdometerWriteRequestPending, filter=data-filter-type=ALWAYS, init-value=constant-reference=CWriteReqNotPending
    require port PpDisplayStateIoHwAb: required-com-specs=[IoHwAbCSPortInterface/ReadChannel, IoHwAbCSPortInterface/WriteChannel], required-interface=IoHwAbCSPortInterface
    require port PplocalIgnitionStateIoHwAb: required-com-specs=[IoHwAbCSPortInterface/ReadChannel, IoHwAbCSPortInterface/WriteChannel], required-interface=IoHwAbCSPortInterface
    provide port PpLocalIgnitionState: nonqueued-sender-com-spec{data-element=DeIgnitionState, init-value=1}, provided-interface=PiIgnitionState
    behavior CtSaDisplay_InternalBehavior: data-type-mapping=DemoTypeMapping
      4 x data received event:
        DRT_RCtApDisplayBusStateHandling_PiDisplayState_DeDisplayBusState: start-on-event=RCtApDisplayBusStateHandling, data=PpDisplayState.DeDisplayBusState
        DRT_RCtApDisplayLightOnOffHandling_PiDisplayState_DeLightOnOffCounter: start-on-event=RCtApDisplayLightOnOffHandling, data=PpDisplayState.DeLightOnOffCounter
        DRT_RCtApDisplayOdometerValue_PiDisplayState_DeOdometerValue: start-on-event=RCtApDisplayOdometerValue, data=PpDisplayState.DeOdometerValue
        DRT_RCtApDisplayOdometerWriteRequestPending_PiDisplayState_DeOdometerWriteRequestPending: start-on-event=RCtApDisplayOdometerWriteRequestPending, data=PpDisplayState.DeOdometerWriteRequestPending
      timing event TMT_RCtApDisplayReadIgnitionSignal: start-on-event=RCtApDisplayReadIgnitionSignal, period=0.2
      5 x runnable:
        RCtApDisplayBusStateHandling
          data-receive-point-by-arguments:
            access REC_PiDisplayState_DeDisplayBusState: accessed-variable=PpDisplayState.DeDisplayBusState
          sync call SC_PpDisplayStateIoHwAb_WriteChannel: operation=PpDisplayStateIoHwAb.WriteChannel
          sync call SC_PplocalIgnitionStateIoHwAb_ReadChannel: operation=PplocalIgnitionStateIoHwAb.ReadChannel
        RCtApDisplayLightOnOffHandling
          data-receive-point-by-arguments:
            access REC_PiDisplayState_DeLightOnOffCounter: accessed-variable=PpDisplayState.DeLightOnOffCounter
        RCtApDisplayOdometerValue
          data-receive-point-by-arguments:
            access REC_PiDisplayState_DeOdometerValue: accessed-variable=PpDisplayState.DeOdometerValue
        RCtApDisplayOdometerWriteRequestPending
          data-receive-point-by-arguments:
            access REC_PiDisplayState_DeOdometerWriteRequestPending: accessed-variable=PpDisplayState.DeOdometerWriteRequestPending
        RCtApDisplayReadIgnitionSignal
          data-send-points:
            access SEND_PpLocalIgnitionState_DeIgnitionState: accessed-variable=PpLocalIgnitionState.DeIgnitionState
          sync call SC_PplocalIgnitionStateIoHwAb_ReadChannel: operation=PplocalIgnitionStateIoHwAb.ReadChannel
  swc implementation CtSaDisplay_Implementation: behavior=CtSaDisplay_InternalBehavior
  sensor actuator sw component type CtSaDoor
    provide port PpDoorState: nonqueued-sender-com-spec{data-element=DeDoorState, init-value=constant-reference=CDoorClosed}, provided-interface=PiDoorState
    require port PpDoorIoHwAb: client-com-spec=PiDoorIoHwAb/ReadChannel, required-interface=PiDoorIoHwAb
    behavior CtSaDoor_InternalBehavior: data-type-mapping=DemoTypeMapping, supports-multiple-instantiation=true
      timing event TMT_RCtSaDoorReadDoor: start-on-event=RCtSaDoorReadDoor, period=0.2
      runnable RCtSaDoorReadDoor
        data-send-points:
          access SEND_PpDoorState_DeDoorState: accessed-variable=PpDoorState.DeDoorState
        sync call SC_PpDoorIoHwAb_ReadChannel: operation=PpDoorIoHwAb.ReadChannel
  swc implementation CtSaDoor_Implementation: behavior=CtSaDoor_InternalBehavior
  sensor actuator sw component type CtSaInteriorLight
    4 x require port:
      PpLightState: nonqueued-receiver-com-spec{data-element=DeLightState, filter=data-filter-type=ALWAYS, init-value=constant-reference=CLightOff}, required-interface=PiLightState
      PpInteriorLightIoHwAb: client-com-spec=PiLightIoHwAb/WriteChannel, required-interface=PiLightIoHwAb
      PpInteriorLightDefect: client-com-spec=PiLightDefectIoHwAb/ReadChannel, required-interface=PiLightDefectIoHwAb
      Event_DTC_0x000002: required-interface=DiagnosticMonitor
        required-com-specs:
          SetEventStatus
          ResetEventStatus
          ResetEventDebounceStatus
          DiagnosticMonitor/GetEventUdsStatus
          DiagnosticMonitor/GetEventStatus
          DiagnosticMonitor/GetEventFailed
          DiagnosticMonitor/GetEventTested
          DiagnosticMonitor/GetDTCOfEvent
          DiagnosticMonitor/GetFaultDetectionCounter
          DiagnosticMonitor/GetEventFreezeFrameDataEx
          DiagnosticMonitor/GetEventExtendedDataRecordEx
    behavior CtSaInteriorLight_InternalBehavior: data-type-mapping=DemoTypeMapping, supports-multiple-instantiation=true
      data received event DRT_RCtSaInteriorLightSwitchLight_PpLightState_DeLightState: start-on-event=RCtSaInteriorLightSwitchLight, data=PpLightState.DeLightState
      runnable RCtSaInteriorLightSwitchLight
        data-receive-point-by-arguments:
          access REC_PpLightState_DeLightState: accessed-variable=PpLightState.DeLightState
        sync call SC_PpLightIoHwAb_WriteChannel: operation=PpInteriorLightIoHwAb.WriteChannel
        sync call SC_PpInteriorLightDefect_ReadChannel: operation=PpInteriorLightDefect.ReadChannel
        sync call SC_Event_DTC_0x000002_SetEventStatus: operation=Event_DTC_0x000002.SetEventStatus
  swc implementation CtSaInteriorLight_Implementation: behavior=CtSaInteriorLight_InternalBehavior
package /ComponentTypes/DataTypeMappingSets
  data type mapping set DemoTypeMapping
    data-type-maps:
      application-data-type=AdtDoorState, implementation-data-type=IdtDoorState
      application-data-type=AdtLightState, implementation-data-type=IdtLightState
      application-data-type=AdtLightOnOffCounter, implementation-data-type=PlatformTypes/uint32
      application-data-type=AdtOdometer, implementation-data-type=PlatformTypes/uint32
    mode-request-type-maps:
      implementation-data-type=BswM_ESH_Mode, mode-group=ESH_Mode
      implementation-data-type=PlatformTypes/uint8, mode-group=ComMMode
package /Constants
  7 x constant specification:
    CBackLightDimCtrlInit: value-spec=0
    CDisplayOff: value-spec=0
    CDoorClosed: value-spec=0
    CLightOff: value-spec=0
    COdometerDefault: value-spec=1000
    CUInt32Zero: value-spec=0
    CWriteReqNotPending: value-spec=0
package /Predefined_DEV/ImplementationDataTypes
  impl type NvM_RequestResultType: compu {0=NVM_REQ_OK, 1=NVM_REQ_NOT_OK, 2=NVM_REQ_PENDING, 3=NVM_REQ_INTEGRITY_FAILED, 4=NVM_REQ_BLOCK_SKIPPED, 5=NVM_REQ_NV_INVALIDATED, 6=NVM_REQ_CANCELED, 7=NVM_REQ_REDUNDANCY_FAILED, 8=NVM_REQ_RESTORED_FROM_ROM}, implementation-data-type=ImplementationDataTypes/uint8
  impl type NvM_ServiceIdType: compu {6=NVM_READ_BLOCK, 7=NVM_WRITE_BLOCK, 8=NVM_RESTORE_BLOCK_DEFAULTS, 9=NVM_ERASE_BLOCK, 11=NVM_INVALIDATE_NV_BLOCK, 12=NVM_READ_ALL}, implementation-data-type=ImplementationDataTypes/uint8
  impl type Dem_UdsStatusByteType: compu {mask 1: 1=DEM_UDS_STATUS_TF, mask 2: 2=DEM_UDS_STATUS_TFTOC, mask 4: 4=DEM_UDS_STATUS_PDTC, mask 8: 8=DEM_UDS_STATUS_CDTC, mask 16: 16=DEM_UDS_STATUS_TNCSLC, mask 32: 32=DEM_UDS_STATUS_TFSLC, mask 64: 64=DEM_UDS_STATUS_TNCTOC, mask 128: 128=DEM_UDS_STATUS_WIR}, range raw 0..255, implementation-data-type=ImplementationDataTypes/uint8
package /Predefined_DEV/PortInterfaces
  43 x client server interface:
    NvMNotifyInitBlock: is-service=true
      operation InitBlock
    NvSWC_NvMNotifyInitBlock
      operation InitBlock
    NvMAdministration: is-service=true
      operation SetBlockProtection: possible-error=NvMAdministration/E_NOT_OK
        arg ProtectionEnabled: type=ImplementationDataTypes/boolean, direction=IN, server-argument-impl-policy=USE-ARGUMENT-TYPE
      error E_NOT_OK: error-code=1
    NvSWC_NvMAdministration
      operation SetBlockProtection: possible-error=NvSWC_NvMAdministration/E_NOT_OK
        arg ProtectionEnabled: type=ImplementationDataTypes/boolean, direction=IN, server-argument-impl-policy=USE-ARGUMENT-TYPE
      error E_NOT_OK: error-code=1
    NvMService: is-service=true
      operation GetErrorStatus: possible-error=NvMService/E_NOT_OK
        arg ErrorStatus: type=ImplementationDataTypes/NvM_RequestResultType, direction=OUT, server-argument-impl-policy=USE-ARGUMENT-TYPE
      error E_NOT_OK: error-code=1
    NvMService_AC2: is-service=true
      operation GetErrorStatus: possible-error=NvMService_AC2/E_NOT_OK
        arg ErrorStatus: type=ImplementationDataTypes/NvM_RequestResultType, direction=OUT, server-argument-impl-policy=USE-ARGUMENT-TYPE
      operation ReadBlock: possible-error=NvMService_AC2/E_NOT_OK
        arg DstPtr: type=dtRef_VOID, direction=IN, server-argument-impl-policy=USE-ARGUMENT-TYPE
      operation WriteBlock: possible-error=NvMService_AC2/E_NOT_OK
        arg SrcPtr: type=dtRef_const_VOID, direction=IN, server-argument-impl-policy=USE-ARGUMENT-TYPE
      error E_NOT_OK: error-code=1
    NvMService_AC2_Defs: is-service=true
      4 x operation, all with possible-error=NvMService_AC2_Defs/E_NOT_OK:
        GetErrorStatus
          arg ErrorStatus: type=ImplementationDataTypes/NvM_RequestResultType, direction=OUT, server-argument-impl-policy=USE-ARGUMENT-TYPE
        ReadBlock
          arg DstPtr: type=dtRef_VOID, direction=IN, server-argument-impl-policy=USE-ARGUMENT-TYPE
        RestoreBlockDefaults
          arg DstPtr: type=dtRef_VOID, direction=IN, server-argument-impl-policy=USE-ARGUMENT-TYPE
        WriteBlock
          arg SrcPtr: type=dtRef_const_VOID, direction=IN, server-argument-impl-policy=USE-ARGUMENT-TYPE
      error E_NOT_OK: error-code=1
    NvMService_AC2_DS: is-service=true
      5 x operation, all with possible-error=NvMService_AC2_DS/E_NOT_OK:
        GetDataIndex
          arg DataIndex: type=ImplementationDataTypes/uint8, direction=OUT, server-argument-impl-policy=USE-ARGUMENT-TYPE
        GetErrorStatus
          arg ErrorStatus: type=ImplementationDataTypes/NvM_RequestResultType, direction=OUT, server-argument-impl-policy=USE-ARGUMENT-TYPE
        ReadBlock
          arg DstPtr: type=dtRef_VOID, direction=IN, server-argument-impl-policy=USE-ARGUMENT-TYPE
        SetDataIndex
          arg DataIndex: type=ImplementationDataTypes/uint8, direction=IN, server-argument-impl-policy=USE-ARGUMENT-TYPE
        WriteBlock
          arg SrcPtr: type=dtRef_const_VOID, direction=IN, server-argument-impl-policy=USE-ARGUMENT-TYPE
      error E_NOT_OK: error-code=1
    NvMService_AC2_DS_Defs: is-service=true
      6 x operation, all with possible-error=NvMService_AC2_DS_Defs/E_NOT_OK:
        GetDataIndex
          arg DataIndex: type=ImplementationDataTypes/uint8, direction=OUT, server-argument-impl-policy=USE-ARGUMENT-TYPE
        GetErrorStatus
          arg ErrorStatus: type=ImplementationDataTypes/NvM_RequestResultType, direction=OUT, server-argument-impl-policy=USE-ARGUMENT-TYPE
        ReadBlock
          arg DstPtr: type=dtRef_VOID, direction=IN, server-argument-impl-policy=USE-ARGUMENT-TYPE
        RestoreBlockDefaults
          arg DstPtr: type=dtRef_VOID, direction=IN, server-argument-impl-policy=USE-ARGUMENT-TYPE
        SetDataIndex
          arg DataIndex: type=ImplementationDataTypes/uint8, direction=IN, server-argument-impl-policy=USE-ARGUMENT-TYPE
        WriteBlock
          arg SrcPtr: type=dtRef_const_VOID, direction=IN, server-argument-impl-policy=USE-ARGUMENT-TYPE
      error E_NOT_OK: error-code=1
    NvMService_AC2_SRBS: is-service=true
      4 x operation, all with possible-error=NvMService_AC2_SRBS/E_NOT_OK:
        GetErrorStatus
          arg ErrorStatus: type=ImplementationDataTypes/NvM_RequestResultType, direction=OUT, server-argument-impl-policy=USE-ARGUMENT-TYPE
        ReadBlock
          arg DstPtr: type=dtRef_VOID, direction=IN, server-argument-impl-policy=USE-ARGUMENT-TYPE
        SetRamBlockStatus
          arg RamBlockStatus: type=ImplementationDataTypes/boolean, direction=IN, server-argument-impl-policy=USE-ARGUMENT-TYPE
        WriteBlock
          arg SrcPtr: type=dtRef_const_VOID, direction=IN, server-argument-impl-policy=USE-ARGUMENT-TYPE
      error E_NOT_OK: error-code=1
    NvMService_AC2_SRBS_Defs: is-service=true
      5 x operation, all with possible-error=NvMService_AC2_SRBS_Defs/E_NOT_OK:
        GetErrorStatus
          arg ErrorStatus: type=ImplementationDataTypes/NvM_RequestResultType, direction=OUT, server-argument-impl-policy=USE-ARGUMENT-TYPE
        ReadBlock
          arg DstPtr: type=dtRef_VOID, direction=IN, server-argument-impl-policy=USE-ARGUMENT-TYPE
        RestoreBlockDefaults
          arg DstPtr: type=dtRef_VOID, direction=IN, server-argument-impl-policy=USE-ARGUMENT-TYPE
        SetRamBlockStatus
          arg RamBlockStatus: type=ImplementationDataTypes/boolean, direction=IN, server-argument-impl-policy=USE-ARGUMENT-TYPE
        WriteBlock
          arg SrcPtr: type=dtRef_const_VOID, direction=IN, server-argument-impl-policy=USE-ARGUMENT-TYPE
      error E_NOT_OK: error-code=1
    NvMService_AC2_SRBS_DS: is-service=true
      6 x operation, all with possible-error=NvMService_AC2_SRBS_DS/E_NOT_OK:
        GetDataIndex
          arg DataIndex: type=ImplementationDataTypes/uint8, direction=OUT, server-argument-impl-policy=USE-ARGUMENT-TYPE
        GetErrorStatus
          arg ErrorStatus: type=ImplementationDataTypes/NvM_RequestResultType, direction=OUT, server-argument-impl-policy=USE-ARGUMENT-TYPE
        ReadBlock
          arg DstPtr: type=dtRef_VOID, direction=IN, server-argument-impl-policy=USE-ARGUMENT-TYPE
        SetDataIndex
          arg DataIndex: type=ImplementationDataTypes/uint8, direction=IN, server-argument-impl-policy=USE-ARGUMENT-TYPE
        SetRamBlockStatus
          arg RamBlockStatus: type=ImplementationDataTypes/boolean, direction=IN, server-argument-impl-policy=USE-ARGUMENT-TYPE
        WriteBlock
          arg SrcPtr: type=dtRef_const_VOID, direction=IN, server-argument-impl-policy=USE-ARGUMENT-TYPE
      error E_NOT_OK: error-code=1
    NvMService_AC2_SRBS_DS_Defs: is-service=true
      7 x operation, all with possible-error=NvMService_AC2_SRBS_DS_Defs/E_NOT_OK:
        GetDataIndex
          arg DataIndex: type=ImplementationDataTypes/uint8, direction=OUT, server-argument-impl-policy=USE-ARGUMENT-TYPE
        GetErrorStatus
          arg ErrorStatus: type=ImplementationDataTypes/NvM_RequestResultType, direction=OUT, server-argument-impl-policy=USE-ARGUMENT-TYPE
        ReadBlock
          arg DstPtr: type=dtRef_VOID, direction=IN, server-argument-impl-policy=USE-ARGUMENT-TYPE
        RestoreBlockDefaults
          arg DstPtr: type=dtRef_VOID, direction=IN, server-argument-impl-policy=USE-ARGUMENT-TYPE
        SetDataIndex
          arg DataIndex: type=ImplementationDataTypes/uint8, direction=IN, server-argument-impl-policy=USE-ARGUMENT-TYPE
        SetRamBlockStatus
          arg RamBlockStatus: type=ImplementationDataTypes/boolean, direction=IN, server-argument-impl-policy=USE-ARGUMENT-TYPE
        WriteBlock
          arg SrcPtr: type=dtRef_const_VOID, direction=IN, server-argument-impl-policy=USE-ARGUMENT-TYPE
      error E_NOT_OK: error-code=1
    NvMService_AC3: is-service=true
      5 x operation, all with possible-error=NvMService_AC3/E_NOT_OK:
        EraseBlock
        GetErrorStatus
          arg ErrorStatus: type=ImplementationDataTypes/NvM_RequestResultType, direction=OUT, server-argument-impl-policy=USE-ARGUMENT-TYPE
        InvalidateNvBlock
        ReadBlock
          arg DstPtr: type=dtRef_VOID, direction=IN, server-argument-impl-policy=USE-ARGUMENT-TYPE
        WriteBlock
          arg SrcPtr: type=dtRef_const_VOID, direction=IN, server-argument-impl-policy=USE-ARGUMENT-TYPE
      error E_NOT_OK: error-code=1
    NvMService_AC3_Defs: is-service=true
      6 x operation, all with possible-error=NvMService_AC3_Defs/E_NOT_OK:
        EraseBlock
        GetErrorStatus
          arg ErrorStatus: type=ImplementationDataTypes/NvM_RequestResultType, direction=OUT, server-argument-impl-policy=USE-ARGUMENT-TYPE
        InvalidateNvBlock
        ReadBlock
          arg DstPtr: type=dtRef_VOID, direction=IN, server-argument-impl-policy=USE-ARGUMENT-TYPE
        RestoreBlockDefaults
          arg DstPtr: type=dtRef_VOID, direction=IN, server-argument-impl-policy=USE-ARGUMENT-TYPE
        WriteBlock
          arg SrcPtr: type=dtRef_const_VOID, direction=IN, server-argument-impl-policy=USE-ARGUMENT-TYPE
      error E_NOT_OK: error-code=1
    NvMService_AC3_DS: is-service=true
      7 x operation, all with possible-error=NvMService_AC3_DS/E_NOT_OK:
        EraseBlock
        GetDataIndex
          arg DataIndex: type=ImplementationDataTypes/uint8, direction=OUT, server-argument-impl-policy=USE-ARGUMENT-TYPE
        GetErrorStatus
          arg ErrorStatus: type=ImplementationDataTypes/NvM_RequestResultType, direction=OUT, server-argument-impl-policy=USE-ARGUMENT-TYPE
        InvalidateNvBlock
        ReadBlock
          arg DstPtr: type=dtRef_VOID, direction=IN, server-argument-impl-policy=USE-ARGUMENT-TYPE
        SetDataIndex
          arg DataIndex: type=ImplementationDataTypes/uint8, direction=IN, server-argument-impl-policy=USE-ARGUMENT-TYPE
        WriteBlock
          arg SrcPtr: type=dtRef_const_VOID, direction=IN, server-argument-impl-policy=USE-ARGUMENT-TYPE
      error E_NOT_OK: error-code=1
    NvMService_AC3_DS_Defs: is-service=true
      8 x operation, all with possible-error=NvMService_AC3_DS_Defs/E_NOT_OK:
        EraseBlock
        GetDataIndex
          arg DataIndex: type=ImplementationDataTypes/uint8, direction=OUT, server-argument-impl-policy=USE-ARGUMENT-TYPE
        GetErrorStatus
          arg ErrorStatus: type=ImplementationDataTypes/NvM_RequestResultType, direction=OUT, server-argument-impl-policy=USE-ARGUMENT-TYPE
        InvalidateNvBlock
        ReadBlock
          arg DstPtr: type=dtRef_VOID, direction=IN, server-argument-impl-policy=USE-ARGUMENT-TYPE
        RestoreBlockDefaults
          arg DstPtr: type=dtRef_VOID, direction=IN, server-argument-impl-policy=USE-ARGUMENT-TYPE
        SetDataIndex
          arg DataIndex: type=ImplementationDataTypes/uint8, direction=IN, server-argument-impl-policy=USE-ARGUMENT-TYPE
        WriteBlock
          arg SrcPtr: type=dtRef_const_VOID, direction=IN, server-argument-impl-policy=USE-ARGUMENT-TYPE
      error E_NOT_OK: error-code=1
    NvMService_AC3_SRBS: is-service=true
      6 x operation, all with possible-error=NvMService_AC3_SRBS/E_NOT_OK:
        EraseBlock
        GetErrorStatus
          arg ErrorStatus: type=ImplementationDataTypes/NvM_RequestResultType, direction=OUT, server-argument-impl-policy=USE-ARGUMENT-TYPE
        InvalidateNvBlock
        ReadBlock
          arg DstPtr: type=dtRef_VOID, direction=IN, server-argument-impl-policy=USE-ARGUMENT-TYPE
        SetRamBlockStatus
          arg RamBlockStatus: type=ImplementationDataTypes/boolean, direction=IN, server-argument-impl-policy=USE-ARGUMENT-TYPE
        WriteBlock
          arg SrcPtr: type=dtRef_const_VOID, direction=IN, server-argument-impl-policy=USE-ARGUMENT-TYPE
      error E_NOT_OK: error-code=1
    NvMService_AC3_SRBS_Defs: is-service=true
      7 x operation, all with possible-error=NvMService_AC3_SRBS_Defs/E_NOT_OK:
        EraseBlock
        GetErrorStatus
          arg ErrorStatus: type=ImplementationDataTypes/NvM_RequestResultType, direction=OUT, server-argument-impl-policy=USE-ARGUMENT-TYPE
        InvalidateNvBlock
        ReadBlock
          arg DstPtr: type=dtRef_VOID, direction=IN, server-argument-impl-policy=USE-ARGUMENT-TYPE
        RestoreBlockDefaults
          arg DstPtr: type=dtRef_VOID, direction=IN, server-argument-impl-policy=USE-ARGUMENT-TYPE
        SetRamBlockStatus
          arg RamBlockStatus: type=ImplementationDataTypes/boolean, direction=IN, server-argument-impl-policy=USE-ARGUMENT-TYPE
        WriteBlock
          arg SrcPtr: type=dtRef_const_VOID, direction=IN, server-argument-impl-policy=USE-ARGUMENT-TYPE
      error E_NOT_OK: error-code=1
    NvMService_AC3_SRBS_DS: is-service=true
      8 x operation, all with possible-error=NvMService_AC3_SRBS_DS/E_NOT_OK:
        EraseBlock
        GetDataIndex
          arg DataIndex: type=ImplementationDataTypes/uint8, direction=OUT, server-argument-impl-policy=USE-ARGUMENT-TYPE
        GetErrorStatus
          arg ErrorStatus: type=ImplementationDataTypes/NvM_RequestResultType, direction=OUT, server-argument-impl-policy=USE-ARGUMENT-TYPE
        InvalidateNvBlock
        ReadBlock
          arg DstPtr: type=dtRef_VOID, direction=IN, server-argument-impl-policy=USE-ARGUMENT-TYPE
        SetDataIndex
          arg DataIndex: type=ImplementationDataTypes/uint8, direction=IN, server-argument-impl-policy=USE-ARGUMENT-TYPE
        SetRamBlockStatus
          arg RamBlockStatus: type=ImplementationDataTypes/boolean, direction=IN, server-argument-impl-policy=USE-ARGUMENT-TYPE
        WriteBlock
          arg SrcPtr: type=dtRef_const_VOID, direction=IN, server-argument-impl-policy=USE-ARGUMENT-TYPE
      error E_NOT_OK: error-code=1
    NvMService_AC3_SRBS_DS_Defs: is-service=true
      9 x operation, all with possible-error=NvMService_AC3_SRBS_DS_Defs/E_NOT_OK:
        EraseBlock
        GetDataIndex
          arg DataIndex: type=ImplementationDataTypes/uint8, direction=OUT, server-argument-impl-policy=USE-ARGUMENT-TYPE
        GetErrorStatus
          arg ErrorStatus: type=ImplementationDataTypes/NvM_RequestResultType, direction=OUT, server-argument-impl-policy=USE-ARGUMENT-TYPE
        InvalidateNvBlock
        ReadBlock
          arg DstPtr: type=dtRef_VOID, direction=IN, server-argument-impl-policy=USE-ARGUMENT-TYPE
        RestoreBlockDefaults
          arg DstPtr: type=dtRef_VOID, direction=IN, server-argument-impl-policy=USE-ARGUMENT-TYPE
        SetDataIndex
          arg DataIndex: type=ImplementationDataTypes/uint8, direction=IN, server-argument-impl-policy=USE-ARGUMENT-TYPE
        SetRamBlockStatus
          arg RamBlockStatus: type=ImplementationDataTypes/boolean, direction=IN, server-argument-impl-policy=USE-ARGUMENT-TYPE
        WriteBlock
          arg SrcPtr: type=dtRef_const_VOID, direction=IN, server-argument-impl-policy=USE-ARGUMENT-TYPE
      error E_NOT_OK: error-code=1
    NvMService_SRBS: is-service=true
      operation GetErrorStatus: possible-error=NvMService_SRBS/E_NOT_OK
        arg ErrorStatus: type=ImplementationDataTypes/NvM_RequestResultType, direction=OUT, server-argument-impl-policy=USE-ARGUMENT-TYPE
      operation SetRamBlockStatus: possible-error=NvMService_SRBS/E_NOT_OK
        arg RamBlockStatus: type=ImplementationDataTypes/boolean, direction=IN, server-argument-impl-policy=USE-ARGUMENT-TYPE
      error E_NOT_OK: error-code=1
    NvSWC_NvMService
      operation GetErrorStatus: possible-error=NvSWC_NvMService/E_NOT_OK
        arg ErrorStatus: type=ImplementationDataTypes/NvM_RequestResultType, direction=OUT, server-argument-impl-policy=USE-ARGUMENT-TYPE
      error E_NOT_OK: error-code=1
    NvSWC_NvMService_AC2
      operation GetErrorStatus: possible-error=NvSWC_NvMService_AC2/E_NOT_OK
        arg ErrorStatus: type=ImplementationDataTypes/NvM_RequestResultType, direction=OUT, server-argument-impl-policy=USE-ARGUMENT-TYPE
      operation ReadBlock: possible-error=NvSWC_NvMService_AC2/E_NOT_OK
        arg DstPtr: type=dtRef_VOID, direction=IN, server-argument-impl-policy=USE-ARGUMENT-TYPE
      operation WriteBlock: possible-error=NvSWC_NvMService_AC2/E_NOT_OK
        arg SrcPtr: type=dtRef_const_VOID, direction=IN, server-argument-impl-policy=USE-ARGUMENT-TYPE
      error E_NOT_OK: error-code=1
    NvSWC_NvMService_AC2_Defs
      4 x operation, all with possible-error=NvSWC_NvMService_AC2_Defs/E_NOT_OK:
        GetErrorStatus
          arg ErrorStatus: type=ImplementationDataTypes/NvM_RequestResultType, direction=OUT, server-argument-impl-policy=USE-ARGUMENT-TYPE
        ReadBlock
          arg DstPtr: type=dtRef_VOID, direction=IN, server-argument-impl-policy=USE-ARGUMENT-TYPE
        RestoreBlockDefaults
          arg DstPtr: type=dtRef_VOID, direction=IN, server-argument-impl-policy=USE-ARGUMENT-TYPE
        WriteBlock
          arg SrcPtr: type=dtRef_const_VOID, direction=IN, server-argument-impl-policy=USE-ARGUMENT-TYPE
      error E_NOT_OK: error-code=1
    NvSWC_NvMService_AC2_DS
      5 x operation, all with possible-error=NvSWC_NvMService_AC2_DS/E_NOT_OK:
        GetDataIndex
          arg DataIndex: type=ImplementationDataTypes/uint8, direction=OUT, server-argument-impl-policy=USE-ARGUMENT-TYPE
        GetErrorStatus
          arg ErrorStatus: type=ImplementationDataTypes/NvM_RequestResultType, direction=OUT, server-argument-impl-policy=USE-ARGUMENT-TYPE
        ReadBlock
          arg DstPtr: type=dtRef_VOID, direction=IN, server-argument-impl-policy=USE-ARGUMENT-TYPE
        SetDataIndex
          arg DataIndex: type=ImplementationDataTypes/uint8, direction=IN, server-argument-impl-policy=USE-ARGUMENT-TYPE
        WriteBlock
          arg SrcPtr: type=dtRef_const_VOID, direction=IN, server-argument-impl-policy=USE-ARGUMENT-TYPE
      error E_NOT_OK: error-code=1
    NvSWC_NvMService_AC2_DS_Defs
      6 x operation, all with possible-error=NvSWC_NvMService_AC2_DS_Defs/E_NOT_OK:
        GetDataIndex
          arg DataIndex: type=ImplementationDataTypes/uint8, direction=OUT, server-argument-impl-policy=USE-ARGUMENT-TYPE
        GetErrorStatus
          arg ErrorStatus: type=ImplementationDataTypes/NvM_RequestResultType, direction=OUT, server-argument-impl-policy=USE-ARGUMENT-TYPE
        ReadBlock
          arg DstPtr: type=dtRef_VOID, direction=IN, server-argument-impl-policy=USE-ARGUMENT-TYPE
        RestoreBlockDefaults
          arg DstPtr: type=dtRef_VOID, direction=IN, server-argument-impl-policy=USE-ARGUMENT-TYPE
        SetDataIndex
          arg DataIndex: type=ImplementationDataTypes/uint8, direction=IN, server-argument-impl-policy=USE-ARGUMENT-TYPE
        WriteBlock
          arg SrcPtr: type=dtRef_const_VOID, direction=IN, server-argument-impl-policy=USE-ARGUMENT-TYPE
      error E_NOT_OK: error-code=1
    NvSWC_NvMService_AC2_SRBS
      4 x operation, all with possible-error=NvSWC_NvMService_AC2_SRBS/E_NOT_OK:
        GetErrorStatus
          arg ErrorStatus: type=ImplementationDataTypes/NvM_RequestResultType, direction=OUT, server-argument-impl-policy=USE-ARGUMENT-TYPE
        ReadBlock
          arg DstPtr: type=dtRef_VOID, direction=IN, server-argument-impl-policy=USE-ARGUMENT-TYPE
        SetRamBlockStatus
          arg RamBlockStatus: type=ImplementationDataTypes/boolean, direction=IN, server-argument-impl-policy=USE-ARGUMENT-TYPE
        WriteBlock
          arg SrcPtr: type=dtRef_const_VOID, direction=IN, server-argument-impl-policy=USE-ARGUMENT-TYPE
      error E_NOT_OK: error-code=1
    NvSWC_NvMService_AC2_SRBS_Defs
      5 x operation, all with possible-error=NvSWC_NvMService_AC2_SRBS_Defs/E_NOT_OK:
        GetErrorStatus
          arg ErrorStatus: type=ImplementationDataTypes/NvM_RequestResultType, direction=OUT, server-argument-impl-policy=USE-ARGUMENT-TYPE
        ReadBlock
          arg DstPtr: type=dtRef_VOID, direction=IN, server-argument-impl-policy=USE-ARGUMENT-TYPE
        RestoreBlockDefaults
          arg DstPtr: type=dtRef_VOID, direction=IN, server-argument-impl-policy=USE-ARGUMENT-TYPE
        SetRamBlockStatus
          arg RamBlockStatus: type=ImplementationDataTypes/boolean, direction=IN, server-argument-impl-policy=USE-ARGUMENT-TYPE
        WriteBlock
          arg SrcPtr: type=dtRef_const_VOID, direction=IN, server-argument-impl-policy=USE-ARGUMENT-TYPE
      error E_NOT_OK: error-code=1
    NvSWC_NvMService_AC2_SRBS_DS
      6 x operation, all with possible-error=NvSWC_NvMService_AC2_SRBS_DS/E_NOT_OK:
        GetDataIndex
          arg DataIndex: type=ImplementationDataTypes/uint8, direction=OUT, server-argument-impl-policy=USE-ARGUMENT-TYPE
        GetErrorStatus
          arg ErrorStatus: type=ImplementationDataTypes/NvM_RequestResultType, direction=OUT, server-argument-impl-policy=USE-ARGUMENT-TYPE
        ReadBlock
          arg DstPtr: type=dtRef_VOID, direction=IN, server-argument-impl-policy=USE-ARGUMENT-TYPE
        SetDataIndex
          arg DataIndex: type=ImplementationDataTypes/uint8, direction=IN, server-argument-impl-policy=USE-ARGUMENT-TYPE
        SetRamBlockStatus
          arg RamBlockStatus: type=ImplementationDataTypes/boolean, direction=IN, server-argument-impl-policy=USE-ARGUMENT-TYPE
        WriteBlock
          arg SrcPtr: type=dtRef_const_VOID, direction=IN, server-argument-impl-policy=USE-ARGUMENT-TYPE
      error E_NOT_OK: error-code=1
    NvSWC_NvMService_AC2_SRBS_DS_Defs
      7 x operation, all with possible-error=NvSWC_NvMService_AC2_SRBS_DS_Defs/E_NOT_OK:
        GetDataIndex
          arg DataIndex: type=ImplementationDataTypes/uint8, direction=OUT, server-argument-impl-policy=USE-ARGUMENT-TYPE
        GetErrorStatus
          arg ErrorStatus: type=ImplementationDataTypes/NvM_RequestResultType, direction=OUT, server-argument-impl-policy=USE-ARGUMENT-TYPE
        ReadBlock
          arg DstPtr: type=dtRef_VOID, direction=IN, server-argument-impl-policy=USE-ARGUMENT-TYPE
        RestoreBlockDefaults
          arg DstPtr: type=dtRef_VOID, direction=IN, server-argument-impl-policy=USE-ARGUMENT-TYPE
        SetDataIndex
          arg DataIndex: type=ImplementationDataTypes/uint8, direction=IN, server-argument-impl-policy=USE-ARGUMENT-TYPE
        SetRamBlockStatus
          arg RamBlockStatus: type=ImplementationDataTypes/boolean, direction=IN, server-argument-impl-policy=USE-ARGUMENT-TYPE
        WriteBlock
          arg SrcPtr: type=dtRef_const_VOID, direction=IN, server-argument-impl-policy=USE-ARGUMENT-TYPE
      error E_NOT_OK: error-code=1
    NvSWC_NvMService_AC3
      5 x operation, all with possible-error=NvSWC_NvMService_AC3/E_NOT_OK:
        EraseBlock
        GetErrorStatus
          arg ErrorStatus: type=ImplementationDataTypes/NvM_RequestResultType, direction=OUT, server-argument-impl-policy=USE-ARGUMENT-TYPE
        InvalidateNvBlock
        ReadBlock
          arg DstPtr: type=dtRef_VOID, direction=IN, server-argument-impl-policy=USE-ARGUMENT-TYPE
        WriteBlock
          arg SrcPtr: type=dtRef_const_VOID, direction=IN, server-argument-impl-policy=USE-ARGUMENT-TYPE
      error E_NOT_OK: error-code=1
    NvSWC_NvMService_AC3_Defs
      6 x operation, all with possible-error=NvSWC_NvMService_AC3_Defs/E_NOT_OK:
        EraseBlock
        GetErrorStatus
          arg ErrorStatus: type=ImplementationDataTypes/NvM_RequestResultType, direction=OUT, server-argument-impl-policy=USE-ARGUMENT-TYPE
        InvalidateNvBlock
        ReadBlock
          arg DstPtr: type=dtRef_VOID, direction=IN, server-argument-impl-policy=USE-ARGUMENT-TYPE
        RestoreBlockDefaults
          arg DstPtr: type=dtRef_VOID, direction=IN, server-argument-impl-policy=USE-ARGUMENT-TYPE
        WriteBlock
          arg SrcPtr: type=dtRef_const_VOID, direction=IN, server-argument-impl-policy=USE-ARGUMENT-TYPE
      error E_NOT_OK: error-code=1
    NvSWC_NvMService_AC3_DS
      7 x operation, all with possible-error=NvSWC_NvMService_AC3_DS/E_NOT_OK:
        EraseBlock
        GetDataIndex
          arg DataIndex: type=ImplementationDataTypes/uint8, direction=OUT, server-argument-impl-policy=USE-ARGUMENT-TYPE
        GetErrorStatus
          arg ErrorStatus: type=ImplementationDataTypes/NvM_RequestResultType, direction=OUT, server-argument-impl-policy=USE-ARGUMENT-TYPE
        InvalidateNvBlock
        ReadBlock
          arg DstPtr: type=dtRef_VOID, direction=IN, server-argument-impl-policy=USE-ARGUMENT-TYPE
        SetDataIndex
          arg DataIndex: type=ImplementationDataTypes/uint8, direction=IN, server-argument-impl-policy=USE-ARGUMENT-TYPE
        WriteBlock
          arg SrcPtr: type=dtRef_const_VOID, direction=IN, server-argument-impl-policy=USE-ARGUMENT-TYPE
      error E_NOT_OK: error-code=1
    NvSWC_NvMService_AC3_DS_Defs
      8 x operation, all with possible-error=NvSWC_NvMService_AC3_DS_Defs/E_NOT_OK:
        EraseBlock
        GetDataIndex
          arg DataIndex: type=ImplementationDataTypes/uint8, direction=OUT, server-argument-impl-policy=USE-ARGUMENT-TYPE
        GetErrorStatus
          arg ErrorStatus: type=ImplementationDataTypes/NvM_RequestResultType, direction=OUT, server-argument-impl-policy=USE-ARGUMENT-TYPE
        InvalidateNvBlock
        ReadBlock
          arg DstPtr: type=dtRef_VOID, direction=IN, server-argument-impl-policy=USE-ARGUMENT-TYPE
        RestoreBlockDefaults
          arg DstPtr: type=dtRef_VOID, direction=IN, server-argument-impl-policy=USE-ARGUMENT-TYPE
        SetDataIndex
          arg DataIndex: type=ImplementationDataTypes/uint8, direction=IN, server-argument-impl-policy=USE-ARGUMENT-TYPE
        WriteBlock
          arg SrcPtr: type=dtRef_const_VOID, direction=IN, server-argument-impl-policy=USE-ARGUMENT-TYPE
      error E_NOT_OK: error-code=1
    NvSWC_NvMService_AC3_SRBS
      6 x operation, all with possible-error=NvSWC_NvMService_AC3_SRBS/E_NOT_OK:
        EraseBlock
        GetErrorStatus
          arg ErrorStatus: type=ImplementationDataTypes/NvM_RequestResultType, direction=OUT, server-argument-impl-policy=USE-ARGUMENT-TYPE
        InvalidateNvBlock
        ReadBlock
          arg DstPtr: type=dtRef_VOID, direction=IN, server-argument-impl-policy=USE-ARGUMENT-TYPE
        SetRamBlockStatus
          arg RamBlockStatus: type=ImplementationDataTypes/boolean, direction=IN, server-argument-impl-policy=USE-ARGUMENT-TYPE
        WriteBlock
          arg SrcPtr: type=dtRef_const_VOID, direction=IN, server-argument-impl-policy=USE-ARGUMENT-TYPE
      error E_NOT_OK: error-code=1
    NvSWC_NvMService_AC3_SRBS_Defs
      7 x operation, all with possible-error=NvSWC_NvMService_AC3_SRBS_Defs/E_NOT_OK:
        EraseBlock
        GetErrorStatus
          arg ErrorStatus: type=ImplementationDataTypes/NvM_RequestResultType, direction=OUT, server-argument-impl-policy=USE-ARGUMENT-TYPE
        InvalidateNvBlock
        ReadBlock
          arg DstPtr: type=dtRef_VOID, direction=IN, server-argument-impl-policy=USE-ARGUMENT-TYPE
        RestoreBlockDefaults
          arg DstPtr: type=dtRef_VOID, direction=IN, server-argument-impl-policy=USE-ARGUMENT-TYPE
        SetRamBlockStatus
          arg RamBlockStatus: type=ImplementationDataTypes/boolean, direction=IN, server-argument-impl-policy=USE-ARGUMENT-TYPE
        WriteBlock
          arg SrcPtr: type=dtRef_const_VOID, direction=IN, server-argument-impl-policy=USE-ARGUMENT-TYPE
      error E_NOT_OK: error-code=1
    NvSWC_NvMService_AC3_SRBS_DS
      8 x operation, all with possible-error=NvSWC_NvMService_AC3_SRBS_DS/E_NOT_OK:
        EraseBlock
        GetDataIndex
          arg DataIndex: type=ImplementationDataTypes/uint8, direction=OUT, server-argument-impl-policy=USE-ARGUMENT-TYPE
        GetErrorStatus
          arg ErrorStatus: type=ImplementationDataTypes/NvM_RequestResultType, direction=OUT, server-argument-impl-policy=USE-ARGUMENT-TYPE
        InvalidateNvBlock
        ReadBlock
          arg DstPtr: type=dtRef_VOID, direction=IN, server-argument-impl-policy=USE-ARGUMENT-TYPE
        SetDataIndex
          arg DataIndex: type=ImplementationDataTypes/uint8, direction=IN, server-argument-impl-policy=USE-ARGUMENT-TYPE
        SetRamBlockStatus
          arg RamBlockStatus: type=ImplementationDataTypes/boolean, direction=IN, server-argument-impl-policy=USE-ARGUMENT-TYPE
        WriteBlock
          arg SrcPtr: type=dtRef_const_VOID, direction=IN, server-argument-impl-policy=USE-ARGUMENT-TYPE
      error E_NOT_OK: error-code=1
    NvSWC_NvMService_AC3_SRBS_DS_Defs
      9 x operation, all with possible-error=NvSWC_NvMService_AC3_SRBS_DS_Defs/E_NOT_OK:
        EraseBlock
        GetDataIndex
          arg DataIndex: type=ImplementationDataTypes/uint8, direction=OUT, server-argument-impl-policy=USE-ARGUMENT-TYPE
        GetErrorStatus
          arg ErrorStatus: type=ImplementationDataTypes/NvM_RequestResultType, direction=OUT, server-argument-impl-policy=USE-ARGUMENT-TYPE
        InvalidateNvBlock
        ReadBlock
          arg DstPtr: type=dtRef_VOID, direction=IN, server-argument-impl-policy=USE-ARGUMENT-TYPE
        RestoreBlockDefaults
          arg DstPtr: type=dtRef_VOID, direction=IN, server-argument-impl-policy=USE-ARGUMENT-TYPE
        SetDataIndex
          arg DataIndex: type=ImplementationDataTypes/uint8, direction=IN, server-argument-impl-policy=USE-ARGUMENT-TYPE
        SetRamBlockStatus
          arg RamBlockStatus: type=ImplementationDataTypes/boolean, direction=IN, server-argument-impl-policy=USE-ARGUMENT-TYPE
        WriteBlock
          arg SrcPtr: type=dtRef_const_VOID, direction=IN, server-argument-impl-policy=USE-ARGUMENT-TYPE
      error E_NOT_OK: error-code=1
    NvSWC_NvMService_SRBS
      operation GetErrorStatus: possible-error=NvSWC_NvMService_SRBS/E_NOT_OK
        arg ErrorStatus: type=ImplementationDataTypes/NvM_RequestResultType, direction=OUT, server-argument-impl-policy=USE-ARGUMENT-TYPE
      operation SetRamBlockStatus: possible-error=NvSWC_NvMService_SRBS/E_NOT_OK
        arg RamBlockStatus: type=ImplementationDataTypes/boolean, direction=IN, server-argument-impl-policy=USE-ARGUMENT-TYPE
      error E_NOT_OK: error-code=1
    NvMNotifyJobFinished: is-service=true
      operation JobFinished
        arg ServiceId: type=ImplementationDataTypes/NvM_ServiceIdType, direction=IN, server-argument-impl-policy=USE-ARGUMENT-TYPE
        arg JobResult: type=ImplementationDataTypes/NvM_RequestResultType, direction=IN, server-argument-impl-policy=USE-ARGUMENT-TYPE
    NvSWC_NvMNotifyJobFinished
      operation JobFinished
        arg ServiceId: type=ImplementationDataTypes/NvM_ServiceIdType, direction=IN, server-argument-impl-policy=USE-ARGUMENT-TYPE
        arg JobResult: type=ImplementationDataTypes/NvM_RequestResultType, direction=IN, server-argument-impl-policy=USE-ARGUMENT-TYPE
    CallbackDTCStatusChange: is-service=true, service-kind=DIAGNOSTIC-EVENT-MANAGER
      operation DTCStatusChanged: possible-error=CallbackDTCStatusChange/E_NOT_OK
        arg DTC: type=ImplementationDataTypes/uint32, direction=IN, server-argument-impl-policy=USE-ARGUMENT-TYPE
        arg DTCStatusOld: type=ImplementationDataTypes/Dem_UdsStatusByteType, direction=IN, server-argument-impl-policy=USE-ARGUMENT-TYPE
        arg DTCStatusNew: type=ImplementationDataTypes/Dem_UdsStatusByteType, direction=IN, server-argument-impl-policy=USE-ARGUMENT-TYPE
      error E_NOT_OK: error-code=1
package /DataTypes
  app type AdtDoorState: category=BOOLEAN, sw-calibration-access=READ-ONLY
  app type AdtLightState: category=BOOLEAN, sw-calibration-access=READ-ONLY
  4 x impl type, all with type-emitter=RTE:
    IdtDoorState: compu {0=CMDOORSTATE_DOORCLOSED, 1=CMDOORSTATE_DOOROPEN}, implementation-data-type=PlatformTypes/boolean
    IdtLightState: compu {0=CMLIGHTSTATE_LIGHTOFF, 1=CMLIGHTSTATE_LIGHTON}, implementation-data-type=PlatformTypes/boolean
    IdtDioValueType: implementation-data-type=PlatformTypes/uint8
    IdtDisplayIgnitionState: category=VALUE, base-type=UInt8, sw-calibration-access=READ-ONLY, compu {0=CMIGNITION_STATEON, 1=CMIGNITION_STATEOFF}
  app type AdtOdometer: category=VALUE, sw-calibration-access=READ-ONLY
  app type AdtLightOnOffCounter: category=VALUE, sw-calibration-access=READ-ONLY
package /NM
  nm config NmConfig: can-nm-cluster-coupling=coupled-cluster=CAN00_CAN
    can nm cluster CAN00_CAN: communication-cluster=CAN00, nm-channel-id=0, nm-msg-cycle-time=0.1, nm-network-timeout=1, nm-repeat-message-time=0.4, nm-user-data-length=6, nm-wait-bus-sleep-time=0.75
      can nm node MyECU: controller=CT_CAN00, nm-if-ecu=MyECU_CAN, nm-node-id=0, rx-nm-pdu=msg_nm_RearECU_oCAN00, tx-nm-pdu=msg_nm_MyECU_oCAN00, nm-msg-cycle-offset=0, nm-msg-reduced-time=0.05, nm-range-config={lower-can-id=1024, upper-can-id=1087}
      can nm node RearECU: nm-if-ecu=RearECU_CAN, nm-node-id=1, rx-nm-pdu=msg_nm_MyECU_oCAN00, tx-nm-pdu=msg_nm_RearECU_oCAN00, nm-msg-cycle-offset=0, nm-msg-reduced-time=0.05, nm-range-config={lower-can-id=1024, upper-can-id=1087}
      can nm node Tester: nm-if-ecu=Tester_CAN, nm-node-id=0, nm-passive-mode-enabled=true, nm-msg-cycle-offset=0, nm-msg-reduced-time=0.05, nm-range-config={lower-can-id=1024, upper-can-id=1087}
    nm-if-ecus:
      nm ecu MyECU_CAN: ecu-instance=MyECU, nm-node-id-enabled=true, nm-user-data-enabled=true
      nm ecu RearECU_CAN: nm-node-id-enabled=true, nm-user-data-enabled=true
      nm ecu Tester_CAN: nm-node-id-enabled=true, nm-passive-mode-enabled=true, nm-user-data-enabled=true
package /TP
  can tp config CAN00_CAN: communication-cluster=CAN00, can-tp-ecu{cycle-time-main-function=0.005, ecu-instance=MyECU}
    can tp channel TPCH: channel-id=0, channel-mode=FULL-DUPLEX-MODE
    can-tp-connection addressing-format=STANDARD, can-tp-channel=TPCH, data-pdu=msg_diag_RequestGlobal_Tp_oCAN00, receiver=TN_MyECU, ta-type=FUNCTIONAL, tp-sdu=msg_diag_RequestGlobal_oCAN00, transmitter=TN_Tester:
      ident msg_diag_RequestGlobal_oTN_Tester
    can-tp-connection addressing-format=STANDARD, can-tp-channel=TPCH, data-pdu=msg_diag_Request_MyECU_Tp_oCAN00, flow-control-pdu=msg_diag_Response_MyECU_Tp_oCAN00, receiver=TN_MyECU, ta-type=PHYSICAL, tp-sdu=msg_diag_Request_MyECU_oCAN00, transmitter=TN_Tester:
      ident msg_diag_Request_MyECU_oTN_MyECU
    can-tp-connection addressing-format=STANDARD, can-tp-channel=TPCH, data-pdu=msg_diag_Response_MyECU_Tp_oCAN00, flow-control-pdu=msg_diag_Request_MyECU_Tp_oCAN00, receiver=TN_Tester, ta-type=PHYSICAL, tp-sdu=msg_diag_Response_MyECU_oCAN00, transmitter=TN_MyECU:
      ident msg_diag_Response_MyECU_oTN_MyECU
    can tp node TN_MyECU: connector=CN_CAN00
    can tp node TN_Tester
package /Cluster
  can cluster CAN00: protocol-name=CAN
    can physical channel CHNL: comm-connectors=CN_CAN00
      frame msg_diag_Request_MyECU_oCAN00: id 0x610, to MyECU, frame-length=8, can-addressing-mode=STANDARD
        n pdu msg_diag_Request_MyECU_Tp_oCAN00: length=8
      frame msg_diag_RequestGlobal_oCAN00: id 0x614, to MyECU, frame-length=8, can-addressing-mode=STANDARD
        n pdu msg_diag_RequestGlobal_Tp_oCAN00: length=8
      frame msg_diag_Response_MyECU_oCAN00: id 0x612, from MyECU, frame-length=8, can-addressing-mode=STANDARD
        n pdu msg_diag_Response_MyECU_Tp_oCAN00: length=8
      frame msg_nm_MyECU_oCAN00: id 0x400, from MyECU, frame-length=8, can-addressing-mode=STANDARD
        nm pdu msg_nm_MyECU_oCAN00: length=8, unused-bit-pattern=0
      frame msg_nm_RearECU_oCAN00: id 0x401, to MyECU, frame-length=8, can-addressing-mode=STANDARD
        nm pdu msg_nm_RearECU_oCAN00: length=8, unused-bit-pattern=0
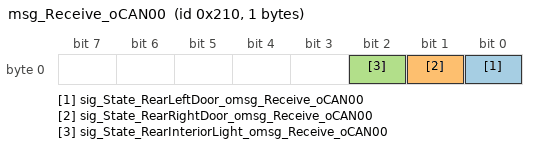
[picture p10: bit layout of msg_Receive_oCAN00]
      frame msg_Receive_oCAN00: id 0x210, to MyECU, frame-length=1, can-addressing-mode=STANDARD
        pdu msg_Receive_oCAN00: length=1, minimum-delay=0, transmission-mode-false-timing=cyclic-timing={time-offset=0, time-period=0.1}, transmission-mode-true-timing=cyclic-timing={time-offset=0, time-period=0.1}, unused-bit-pattern=0
          signal sig_State_RearLeftDoor_omsg_Receive_oCAN00: start 0, 1 bit, little-endian, init-value=0, base-type=DataType/boolean, compu {0..1=RANGE}, transfer-property=PENDING, to MyECU
          signal sig_State_RearRightDoor_omsg_Receive_oCAN00: start 1, 1 bit, little-endian, init-value=0, base-type=DataType/boolean, compu {0..1=RANGE}, transfer-property=PENDING, to MyECU
          signal sig_State_RearInteriorLight_omsg_Receive_oCAN00: start 2, 1 bit, little-endian, init-value=0, base-type=DataType/boolean, compu {0..1=RANGE}, transfer-property=PENDING, to MyECU
      frame msg_Transmit_oCAN00: id 0x200, from MyECU, frame-length=1, can-addressing-mode=STANDARD
        pdu msg_Transmit_oCAN00: length=1, minimum-delay=0, transmission-mode-false-timing=cyclic-timing={time-offset=0, time-period=0.1}, transmission-mode-true-timing=cyclic-timing={time-offset=0, time-period=0.1}, unused-bit-pattern=0
          signal sig_RearInteriorLight_omsg_Transmit_oCAN00: start 0, 1 bit, little-endian, init-value=0, base-type=DataType/boolean, compu {0..1=RANGE}, transfer-property=PENDING
      pdu triggering PT_msg_diag_Request_MyECU: pdu=msg_diag_Request_MyECU_oCAN00, to MyECU
      pdu triggering PT_msg_diag_RequestGlobal: pdu=msg_diag_RequestGlobal_oCAN00, to MyECU
      pdu triggering PT_msg_diag_Response_MyECU: pdu=msg_diag_Response_MyECU_oCAN00, from MyECU
package /ECU
  ecu instance MyECU: associated-com-i-pdu-group=[MyECU_oCAN00_Rx, MyECU_oCAN00_Tx]
    can communication controller CT_CAN00
    can communication connector CN_CAN00: comm-controller=CT_CAN00
package /IPDUGroup
  i signal i pdu group MyECU_oCAN00_Rx: communication-direction=IN, i-signal-i-pdus=msg_Receive_oCAN00
  i signal i pdu group MyECU_oCAN00_Tx: communication-direction=OUT, i-signal-i-pdus=msg_Transmit_oCAN00
package /PDU
  dcm i pdu msg_diag_Request_MyECU_oCAN00: length=8, diag-pdu-type=DIAG-REQUEST
  dcm i pdu msg_diag_RequestGlobal_oCAN00: length=7, diag-pdu-type=DIAG-REQUEST
  dcm i pdu msg_diag_Response_MyECU_oCAN00: length=8, diag-pdu-type=DIAG-RESPONSE
package /PortInterfaces
  sender receiver interface PiDoorState
    data DeDoorState: type=AdtDoorState
  sender receiver interface PiLightState
    data DeLightState: type=AdtLightState
  4 x client server interface:
    PiDoorIoHwAb
      operation ReadChannel
        arg value: type=IdtDioValueType, direction=OUT, server-argument-impl-policy=USE-ARGUMENT-TYPE
      error E_NOT_OK: error-code=1
    PiLightIoHwAb
      operation WriteChannel
        arg value: type=IdtDioValueType, direction=IN, server-argument-impl-policy=USE-ARGUMENT-TYPE
      error E_NOT_OK: error-code=1
    PiLightDefectIoHwAb
      operation ReadChannel
        arg value: type=IdtDioValueType, direction=OUT, server-argument-impl-policy=USE-ARGUMENT-TYPE
    IoHwAbCSPortInterface
      operation ReadChannel
        arg value: type=IdtDioValueType, direction=OUT, server-argument-impl-policy=USE-ARGUMENT-TYPE
      operation WriteChannel
        arg value: type=IdtDioValueType, direction=IN, server-argument-impl-policy=USE-ARGUMENT-TYPE
      error E_NOT_OK: error-code=1
  sender receiver interface PiDisplayState
    4 x data:
      DeDisplayBusState: type=PlatformTypes/boolean
      DeLightOnOffCounter: type=PlatformTypes/uint32
      DeOdometerValue: type=PlatformTypes/uint32
      DeOdometerWriteRequestPending: type=PlatformTypes/boolean
  sender receiver interface PiIgnitionState
    data DeIgnitionState: type=IdtDisplayIgnitionState
